VERSION "12.2.7"

NS_ :

BS_:

BU_: ACM ADAS_Body APM ASU_Gateway BCM BCM_BPM CCU_F CCU_R DUMMY_BCM_BPM ETG LDM_L LDM_R OCS_P PSM_D SRR_RR_M SHVU_F SHVU_R TRM USS_F USS_R XGW_Body

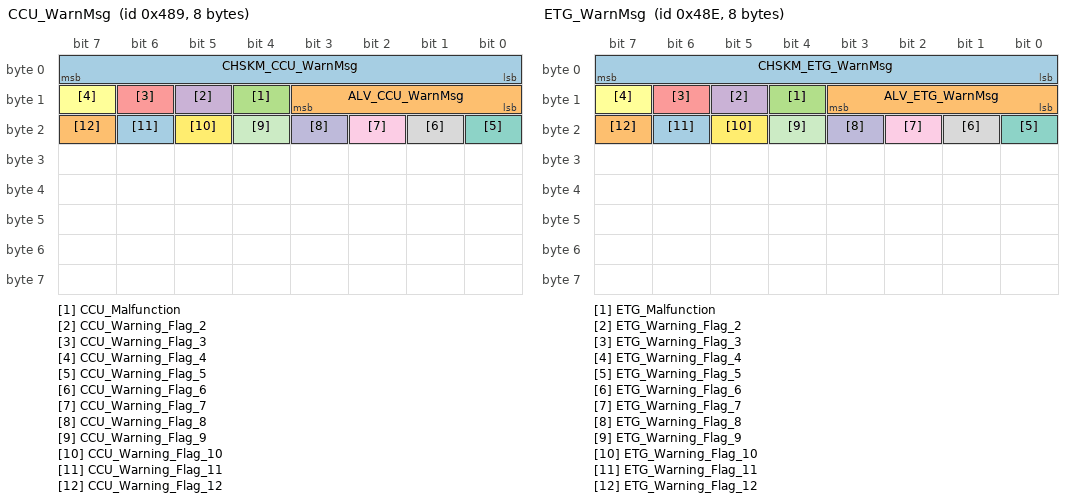
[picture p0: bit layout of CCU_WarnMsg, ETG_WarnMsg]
BO_ 1161 CCU_WarnMsg: 8 CCU_F
 SG_ CHSKM_CCU_WarnMsg : 7|8@0+ (1,0) [0|255] ""  XGW_Body
 SG_ ALV_CCU_WarnMsg : 11|4@0+ (1,0) [0|14] ""  XGW_Body
 SG_ CCU_Malfunction : 12|1@0+ (1,0) [0|1] ""  XGW_Body
 SG_ CCU_Warning_Flag_2 : 13|1@0+ (1,0) [0|1] "-"  XGW_Body
 SG_ CCU_Warning_Flag_3 : 14|1@0+ (1,0) [0|1] ""  XGW_Body
 SG_ CCU_Warning_Flag_4 : 15|1@0+ (1,0) [0|1] "-"  XGW_Body
 SG_ CCU_Warning_Flag_5 : 16|1@0+ (1,0) [0|1] "-"  XGW_Body
 SG_ CCU_Warning_Flag_6 : 17|1@0+ (1,0) [0|1] "-"  XGW_Body
 SG_ CCU_Warning_Flag_7 : 18|1@0+ (1,0) [0|1] "-"  XGW_Body
 SG_ CCU_Warning_Flag_8 : 19|1@0+ (1,0) [0|1] ""  XGW_Body
 SG_ CCU_Warning_Flag_9 : 20|1@0+ (1,0) [0|1] ""  XGW_Body
 SG_ CCU_Warning_Flag_10 : 21|1@0+ (1,0) [0|1] ""  XGW_Body
 SG_ CCU_Warning_Flag_11 : 22|1@0+ (1,0) [0|1] ""  XGW_Body
 SG_ CCU_Warning_Flag_12 : 23|1@0+ (1,0) [0|1] ""  XGW_Body

BO_ 1166 ETG_WarnMsg: 8 ETG
 SG_ CHSKM_ETG_WarnMsg : 7|8@0+ (1,0) [0|255] ""  XGW_Body
 SG_ ALV_ETG_WarnMsg : 11|4@0+ (1,0) [0|14] ""  XGW_Body
 SG_ ETG_Malfunction : 12|1@0+ (1,0) [0|1] "-"  XGW_Body
 SG_ ETG_Warning_Flag_2 : 13|1@0+ (1,0) [0|1] "-"  XGW_Body
 SG_ ETG_Warning_Flag_3 : 14|1@0+ (1,0) [0|1] ""  XGW_Body
 SG_ ETG_Warning_Flag_4 : 15|1@0+ (1,0) [0|1] ""  XGW_Body
 SG_ ETG_Warning_Flag_5 : 16|1@0+ (1,0) [0|1] "-"  XGW_Body
 SG_ ETG_Warning_Flag_6 : 17|1@0+ (1,0) [0|1] "-"  XGW_Body
 SG_ ETG_Warning_Flag_7 : 18|1@0+ (1,0) [0|1] "-"  XGW_Body
 SG_ ETG_Warning_Flag_8 : 19|1@0+ (1,0) [0|1] ""  XGW_Body
 SG_ ETG_Warning_Flag_9 : 20|1@0+ (1,0) [0|1] ""  XGW_Body
 SG_ ETG_Warning_Flag_10 : 21|1@0+ (1,0) [0|1] ""  XGW_Body
 SG_ ETG_Warning_Flag_11 : 22|1@0+ (1,0) [0|1] "-"  XGW_Body
 SG_ ETG_Warning_Flag_12 : 23|1@0+ (1,0) [0|1] ""  XGW_Body

BO_ 1171 BMS_WarnMsg: 8 XGW_Body
 SG_ CHSKM_BMS_WarnMsg : 7|8@0+ (1,0) [0|255] ""  BCM
 SG_ ALV_BMS_WarnMsg : 11|4@0+ (1,0) [0|14] ""  BCM
 SG_ BMS_PackTempSts : 13|2@0+ (1,0) [0|3] ""  BCM
 SG_ BMS_ThermalRunaway : 14|1@0+ (1,0) [0|1] ""  BCM
 SG_ BMS_BatteryReplacement : 15|1@0+ (1,0) [0|1] ""  BCM
 SG_ BMS_Warning_PowerDegrade : 16|1@0+ (1,0) [0|1] ""  BCM
 SG_ BMS_Warning_DeltaSoC : 17|1@0+ (1,0) [0|1] ""  BCM
 SG_ BMS_Warning_HVILSts : 18|1@0+ (1,0) [0|1] ""  BCM
 SG_ BMS_Warning_Isolation : 19|1@0+ (1,0) [0|1] ""  BCM
 SG_ BMS_Warning_CoolantLeakage : 20|1@0+ (1,0) [0|1] ""  BCM
 SG_ BMS_MalfunctionSts : 21|1@0+ (1,0) [0|1] ""  BCM
 SG_ BMS_LowBattery : 23|2@0+ (1,0) [0|3] ""  BCM
 SG_ BMS_Warning_DeltaTemperature : 31|8@0+ (1,0) [0|255] ""  BCM
 SG_ BMS_Warning_BDUTemperatureSts : 39|8@0+ (1,0) [0|255] ""  BCM
 SG_ BMS_Reserved_signal3 : 47|8@0+ (1,0) [0|255] ""  BCM
 SG_ BMS_Reserved_signal4 : 55|8@0+ (1,0) [0|255] ""  BCM
 SG_ BMS_Reserved_signal5 : 63|8@0+ (1,0) [0|255] ""  BCM

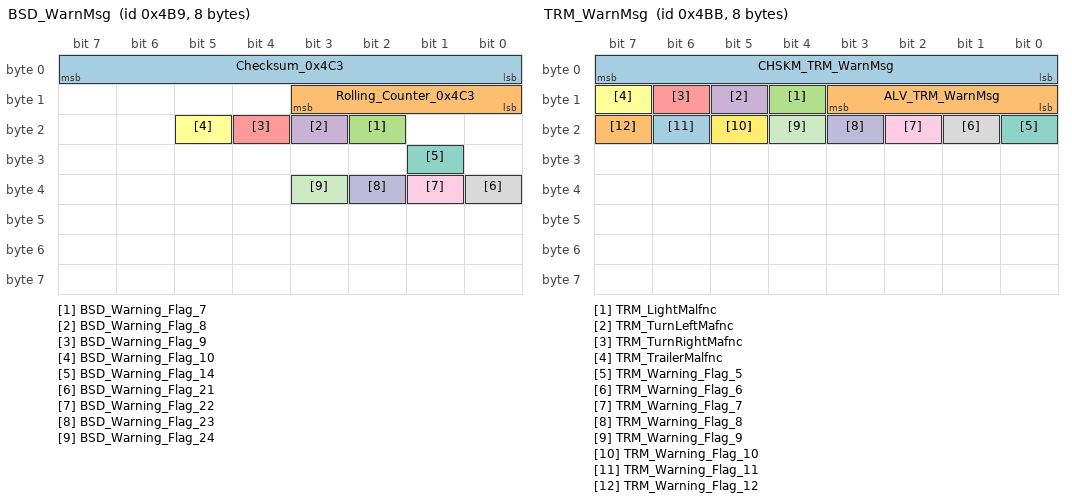
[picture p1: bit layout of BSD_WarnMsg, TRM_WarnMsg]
BO_ 1209 BSD_WarnMsg: 8 SRR_RR_M
 SG_ Checksum_0x4C3 : 7|8@0+ (1,0) [0|255] "" BCM,XGW_Body
 SG_ Rolling_Counter_0x4C3 : 11|4@0+ (1,0) [0|15] "" BCM,XGW_Body
 SG_ BSD_Warning_Flag_7 : 18|1@0+ (1,0) [0|1] "" BCM,XGW_Body
 SG_ BSD_Warning_Flag_8 : 19|1@0+ (1,0) [0|1] "" BCM,XGW_Body
 SG_ BSD_Warning_Flag_9 : 20|1@0+ (1,0) [0|1] "" BCM,XGW_Body
 SG_ BSD_Warning_Flag_10 : 21|1@0+ (1,0) [0|1] "" BCM,XGW_Body
 SG_ BSD_Warning_Flag_14 : 25|1@0+ (1,0) [0|1] "" BCM,XGW_Body
 SG_ BSD_Warning_Flag_21 : 32|1@0+ (1,0) [0|1] "" BCM,XGW_Body
 SG_ BSD_Warning_Flag_22 : 33|1@0+ (1,0) [0|1] "" BCM,XGW_Body
 SG_ BSD_Warning_Flag_23 : 34|1@0+ (1,0) [0|1] "" BCM,XGW_Body
 SG_ BSD_Warning_Flag_24 : 35|1@0+ (1,0) [0|1] "" BCM,XGW_Body

BO_ 1211 TRM_WarnMsg: 8 TRM
 SG_ CHSKM_TRM_WarnMsg : 7|8@0+ (1,0) [0|255] ""  XGW_Body
 SG_ ALV_TRM_WarnMsg : 11|4@0+ (1,0) [0|14] ""  XGW_Body
 SG_ TRM_LightMalfnc : 12|1@0+ (1,0) [0|1] "-"  XGW_Body
 SG_ TRM_TurnLeftMafnc : 13|1@0+ (1,0) [0|1] "-"  XGW_Body
 SG_ TRM_TurnRightMafnc : 14|1@0+ (1,0) [0|1] ""  XGW_Body
 SG_ TRM_TrailerMalfnc : 15|1@0+ (1,0) [0|1] ""  XGW_Body
 SG_ TRM_Warning_Flag_5 : 16|1@0+ (1,0) [0|1] "-"  XGW_Body
 SG_ TRM_Warning_Flag_6 : 17|1@0+ (1,0) [0|1] ""  XGW_Body
 SG_ TRM_Warning_Flag_7 : 18|1@0+ (1,0) [0|1] ""  XGW_Body
 SG_ TRM_Warning_Flag_8 : 19|1@0+ (1,0) [0|1] "-"  XGW_Body
 SG_ TRM_Warning_Flag_9 : 20|1@0+ (1,0) [0|1] "-"  XGW_Body
 SG_ TRM_Warning_Flag_10 : 21|1@0+ (1,0) [0|1] "-"  XGW_Body
 SG_ TRM_Warning_Flag_11 : 22|1@0+ (1,0) [0|1] ""  XGW_Body
 SG_ TRM_Warning_Flag_12 : 23|1@0+ (1,0) [0|1] ""  XGW_Body

BO_ 1216 BCM_STAT_DOOR: 8 BCM
 SG_ SECCAN_BCM_STAT_Door : 55|8@0+ (1,0) [0|255] ""  Vector__XXX
 SG_ BCM_STAT_DoorHandleRR : 56|1@0+ (1,0) [0|1] ""  Vector__XXX
 SG_ BCM_STAT_DoorHandleRL : 57|1@0+ (1,0) [0|1] ""  Vector__XXX
 SG_ BCM_STAT_DoorHandleFR : 58|1@0+ (1,0) [0|1] ""  Vector__XXX
 SG_ BCM_STAT_DoorHandleFL : 59|1@0+ (1,0) [0|1] ""  Vector__XXX

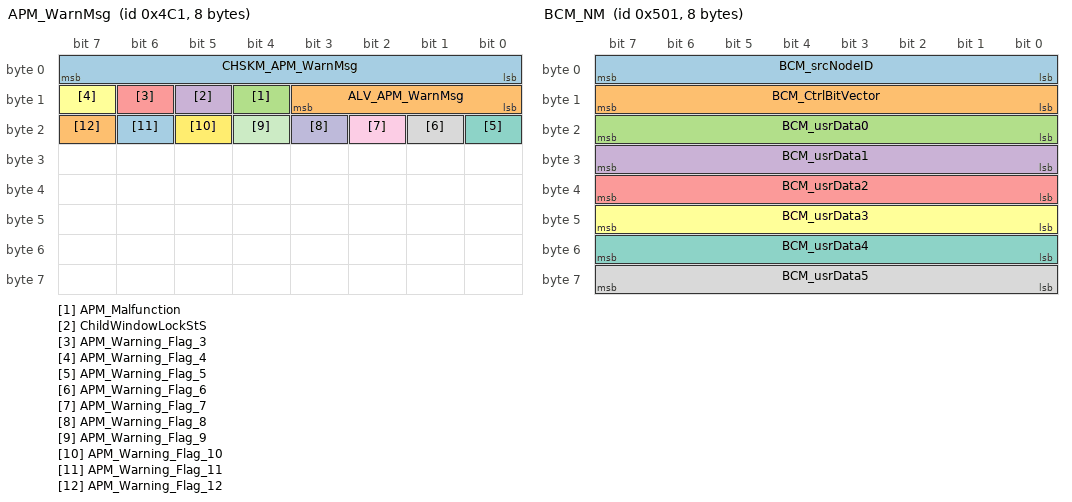
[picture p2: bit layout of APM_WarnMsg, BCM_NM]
BO_ 1217 APM_WarnMsg: 8 APM
 SG_ CHSKM_APM_WarnMsg : 7|8@0+ (1,0) [0|255] ""  XGW_Body
 SG_ ALV_APM_WarnMsg : 11|4@0+ (1,0) [0|14] ""  XGW_Body
 SG_ APM_Malfunction : 12|1@0+ (1,0) [0|1] ""  XGW_Body
 SG_ ChildWindowLockStS : 13|1@0+ (1,0) [0|1] "-"  XGW_Body
 SG_ APM_Warning_Flag_3 : 14|1@0+ (1,0) [0|1] ""  XGW_Body
 SG_ APM_Warning_Flag_4 : 15|1@0+ (1,0) [0|1] ""  XGW_Body
 SG_ APM_Warning_Flag_5 : 16|1@0+ (1,0) [0|1] "-"  XGW_Body
 SG_ APM_Warning_Flag_6 : 17|1@0+ (1,0) [0|1] ""  XGW_Body
 SG_ APM_Warning_Flag_7 : 18|1@0+ (1,0) [0|1] "-"  XGW_Body
 SG_ APM_Warning_Flag_8 : 19|1@0+ (1,0) [0|1] ""  XGW_Body
 SG_ APM_Warning_Flag_9 : 20|1@0+ (1,0) [0|1] ""  XGW_Body
 SG_ APM_Warning_Flag_10 : 21|1@0+ (1,0) [0|1] ""  XGW_Body
 SG_ APM_Warning_Flag_11 : 22|1@0+ (1,0) [0|1] ""  XGW_Body
 SG_ APM_Warning_Flag_12 : 23|1@0+ (1,0) [0|1] "-"  XGW_Body

BO_ 1281 BCM_NM: 8 BCM
 SG_ BCM_srcNodeID : 7|8@0+ (1,0) [0|255] ""  APM,CCU_F,CCU_R,ETG,LDM_L,LDM_R,PSM_D,SRR_RR_M,TRM,XGW_Body
 SG_ BCM_CtrlBitVector : 15|8@0+ (1,0) [0|255] ""  APM,CCU_F,CCU_R,ETG,LDM_L,LDM_R,PSM_D,SRR_RR_M,TRM,XGW_Body
 SG_ BCM_usrData0 : 23|8@0+ (1,0) [0|255] ""  APM,CCU_F,CCU_R,ETG,LDM_L,LDM_R,PSM_D,SRR_RR_M,TRM,XGW_Body
 SG_ BCM_usrData1 : 31|8@0+ (1,0) [0|255] ""  APM,CCU_F,CCU_R,ETG,LDM_L,LDM_R,PSM_D,SRR_RR_M,TRM,XGW_Body
 SG_ BCM_usrData2 : 39|8@0+ (1,0) [0|255] ""  APM,CCU_F,CCU_R,ETG,LDM_L,LDM_R,PSM_D,SRR_RR_M,TRM,XGW_Body
 SG_ BCM_usrData3 : 47|8@0+ (1,0) [0|255] ""  APM,CCU_F,CCU_R,ETG,LDM_L,LDM_R,PSM_D,SRR_RR_M,TRM,XGW_Body
 SG_ BCM_usrData4 : 55|8@0+ (1,0) [0|255] ""  APM,CCU_F,CCU_R,ETG,LDM_L,LDM_R,PSM_D,SRR_RR_M,TRM,XGW_Body
 SG_ BCM_usrData5 : 63|8@0+ (1,0) [0|255] ""  APM,CCU_F,CCU_R,ETG,LDM_L,LDM_R,PSM_D,SRR_RR_M,TRM,XGW_Body

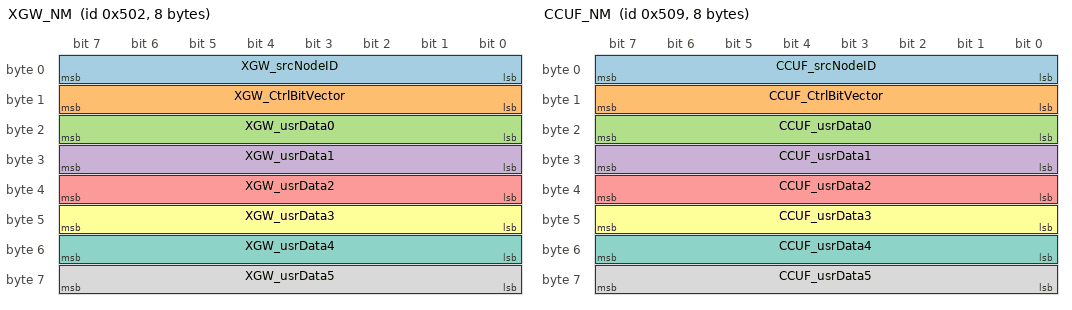
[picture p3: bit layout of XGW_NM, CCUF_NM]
BO_ 1282 XGW_NM: 8 XGW_Body
 SG_ XGW_srcNodeID : 7|8@0+ (1,0) [0|255] ""  APM,ASU_Gateway,BCM,CCU_F,CCU_R,ETG,LDM_L,LDM_R,PSM_D,SRR_RR_M,TRM
 SG_ XGW_CtrlBitVector : 15|8@0+ (1,0) [0|255] ""  APM,ASU_Gateway,BCM,CCU_F,CCU_R,ETG,LDM_L,LDM_R,PSM_D,SRR_RR_M,TRM
 SG_ XGW_usrData0 : 23|8@0+ (1,0) [0|255] ""  APM,ASU_Gateway,BCM,CCU_F,CCU_R,ETG,LDM_L,LDM_R,PSM_D,SRR_RR_M,TRM
 SG_ XGW_usrData1 : 31|8@0+ (1,0) [0|255] ""  APM,ASU_Gateway,BCM,CCU_F,CCU_R,ETG,LDM_L,LDM_R,PSM_D,SRR_RR_M,TRM
 SG_ XGW_usrData2 : 39|8@0+ (1,0) [0|255] ""  APM,ASU_Gateway,BCM,CCU_F,CCU_R,ETG,LDM_L,LDM_R,PSM_D,SRR_RR_M,TRM
 SG_ XGW_usrData3 : 47|8@0+ (1,0) [0|255] ""  APM,ASU_Gateway,BCM,CCU_F,CCU_R,ETG,LDM_L,LDM_R,PSM_D,SRR_RR_M,TRM
 SG_ XGW_usrData4 : 55|8@0+ (1,0) [0|255] ""  APM,ASU_Gateway,BCM,CCU_F,CCU_R,ETG,LDM_L,LDM_R,PSM_D,SRR_RR_M,TRM
 SG_ XGW_usrData5 : 63|8@0+ (1,0) [0|255] ""  APM,ASU_Gateway,BCM,CCU_F,CCU_R,ETG,LDM_L,LDM_R,PSM_D,SRR_RR_M,TRM

BO_ 1289 CCUF_NM: 8 CCU_F
 SG_ CCUF_srcNodeID : 7|8@0+ (1,0) [0|255] ""  APM,BCM,CCU_R,ETG,LDM_L,LDM_R,PSM_D,TRM,XGW_Body
 SG_ CCUF_CtrlBitVector : 15|8@0+ (1,0) [0|255] ""  APM,BCM,CCU_R,ETG,LDM_L,LDM_R,PSM_D,TRM,XGW_Body
 SG_ CCUF_usrData0 : 23|8@0+ (1,0) [0|255] ""  APM,BCM,CCU_R,ETG,LDM_L,LDM_R,PSM_D,TRM,XGW_Body
 SG_ CCUF_usrData1 : 31|8@0+ (1,0) [0|255] ""  APM,BCM,CCU_R,ETG,LDM_L,LDM_R,PSM_D,TRM,XGW_Body
 SG_ CCUF_usrData2 : 39|8@0+ (1,0) [0|255] ""  APM,BCM,CCU_R,ETG,LDM_L,LDM_R,PSM_D,TRM,XGW_Body
 SG_ CCUF_usrData3 : 47|8@0+ (1,0) [0|255] ""  APM,BCM,CCU_R,ETG,LDM_L,LDM_R,PSM_D,TRM,XGW_Body
 SG_ CCUF_usrData4 : 55|8@0+ (1,0) [0|255] ""  APM,BCM,CCU_R,ETG,LDM_L,LDM_R,PSM_D,TRM,XGW_Body
 SG_ CCUF_usrData5 : 63|8@0+ (1,0) [0|255] ""  APM,BCM,CCU_R,ETG,LDM_L,LDM_R,PSM_D,TRM,XGW_Body

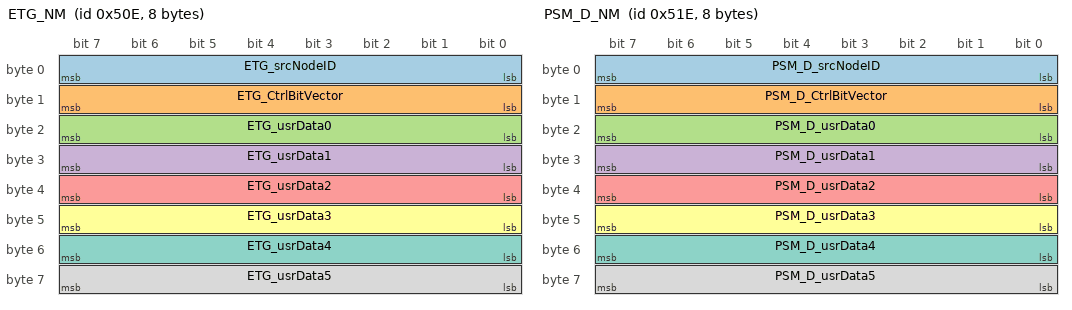
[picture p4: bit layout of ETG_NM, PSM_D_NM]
BO_ 1294 ETG_NM: 8 ETG
 SG_ ETG_srcNodeID : 7|8@0+ (1,0) [0|255] ""  APM,BCM,CCU_F,CCU_R,LDM_L,LDM_R,PSM_D,TRM,XGW_Body
 SG_ ETG_CtrlBitVector : 15|8@0+ (1,0) [0|255] ""  APM,BCM,CCU_F,CCU_R,LDM_L,LDM_R,PSM_D,TRM,XGW_Body
 SG_ ETG_usrData0 : 23|8@0+ (1,0) [0|255] ""  APM,BCM,CCU_F,CCU_R,LDM_L,LDM_R,PSM_D,TRM,XGW_Body
 SG_ ETG_usrData1 : 31|8@0+ (1,0) [0|255] ""  APM,BCM,CCU_F,CCU_R,LDM_L,LDM_R,PSM_D,TRM,XGW_Body
 SG_ ETG_usrData2 : 39|8@0+ (1,0) [0|255] ""  APM,BCM,CCU_F,CCU_R,LDM_L,LDM_R,PSM_D,TRM,XGW_Body
 SG_ ETG_usrData3 : 47|8@0+ (1,0) [0|255] ""  APM,BCM,CCU_F,CCU_R,LDM_L,LDM_R,PSM_D,TRM,XGW_Body
 SG_ ETG_usrData4 : 55|8@0+ (1,0) [0|255] ""  APM,BCM,CCU_F,CCU_R,LDM_L,LDM_R,PSM_D,TRM,XGW_Body
 SG_ ETG_usrData5 : 63|8@0+ (1,0) [0|255] ""  APM,BCM,CCU_F,CCU_R,LDM_L,LDM_R,PSM_D,TRM,XGW_Body

BO_ 1310 PSM_D_NM: 8 PSM_D
 SG_ PSM_D_srcNodeID : 7|8@0+ (1,0) [0|255] ""  APM,BCM,CCU_F,CCU_R,ETG,LDM_L,LDM_R,TRM,XGW_Body
 SG_ PSM_D_CtrlBitVector : 15|8@0+ (1,0) [0|255] ""  APM,BCM,CCU_F,CCU_R,ETG,LDM_L,LDM_R,TRM,XGW_Body
 SG_ PSM_D_usrData0 : 23|8@0+ (1,0) [0|255] ""  APM,BCM,CCU_F,CCU_R,ETG,LDM_L,LDM_R,TRM,XGW_Body
 SG_ PSM_D_usrData1 : 31|8@0+ (1,0) [0|255] ""  APM,BCM,CCU_F,CCU_R,ETG,LDM_L,LDM_R,TRM,XGW_Body
 SG_ PSM_D_usrData2 : 39|8@0+ (1,0) [0|255] ""  APM,BCM,CCU_F,CCU_R,ETG,LDM_L,LDM_R,TRM,XGW_Body
 SG_ PSM_D_usrData3 : 47|8@0+ (1,0) [0|255] ""  APM,BCM,CCU_F,CCU_R,ETG,LDM_L,LDM_R,TRM,XGW_Body
 SG_ PSM_D_usrData4 : 55|8@0+ (1,0) [0|255] ""  APM,BCM,CCU_F,CCU_R,ETG,LDM_L,LDM_R,TRM,XGW_Body
 SG_ PSM_D_usrData5 : 63|8@0+ (1,0) [0|255] ""  APM,BCM,CCU_F,CCU_R,ETG,LDM_L,LDM_R,TRM,XGW_Body

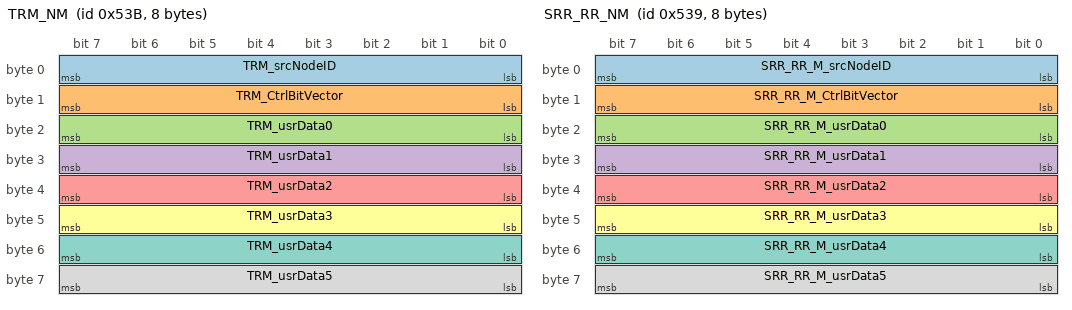
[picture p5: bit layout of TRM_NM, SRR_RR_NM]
BO_ 1339 TRM_NM: 8 TRM
 SG_ TRM_srcNodeID : 7|8@0+ (1,0) [0|255] ""  LDM_R,LDM_L,XGW_Body,BCM,ETG,APM,CCU_F,PSM_D,CCU_R
 SG_ TRM_CtrlBitVector : 15|8@0+ (1,0) [0|255] ""  LDM_R,LDM_L,XGW_Body,BCM,ETG,APM,CCU_F,PSM_D,CCU_R
 SG_ TRM_usrData0 : 23|8@0+ (1,0) [0|255] ""  LDM_R,LDM_L,XGW_Body,BCM,ETG,APM,CCU_F,PSM_D,CCU_R
 SG_ TRM_usrData1 : 31|8@0+ (1,0) [0|255] ""  LDM_R,LDM_L,XGW_Body,BCM,ETG,APM,CCU_F,PSM_D,CCU_R
 SG_ TRM_usrData2 : 39|8@0+ (1,0) [0|255] ""  LDM_R,LDM_L,XGW_Body,BCM,ETG,APM,CCU_F,PSM_D,CCU_R
 SG_ TRM_usrData3 : 47|8@0+ (1,0) [0|255] ""  LDM_R,LDM_L,XGW_Body,BCM,ETG,APM,CCU_F,PSM_D,CCU_R
 SG_ TRM_usrData4 : 55|8@0+ (1,0) [0|255] ""  LDM_R,LDM_L,XGW_Body,BCM,ETG,APM,CCU_F,PSM_D,CCU_R
 SG_ TRM_usrData5 : 63|8@0+ (1,0) [0|255] ""  LDM_R,LDM_L,XGW_Body,BCM,ETG,APM,CCU_F,PSM_D,CCU_R

BO_ 1337 SRR_RR_NM: 8 SRR_RR_M
 SG_ SRR_RR_M_srcNodeID : 7|8@0+ (1,0) [0|255] "" XGW_Body,BCM,ACM
 SG_ SRR_RR_M_CtrlBitVector : 15|8@0+ (1,0) [0|255] "" XGW_Body,BCM,ACM
 SG_ SRR_RR_M_usrData0 : 23|8@0+ (1,0) [0|255] "" XGW_Body,BCM,ACM
 SG_ SRR_RR_M_usrData1 : 31|8@0+ (1,0) [0|255] "" XGW_Body,BCM,ACM
 SG_ SRR_RR_M_usrData2 : 39|8@0+ (1,0) [0|255] "" XGW_Body,BCM,ACM
 SG_ SRR_RR_M_usrData3 : 47|8@0+ (1,0) [0|255] "" XGW_Body,BCM,ACM
 SG_ SRR_RR_M_usrData4 : 55|8@0+ (1,0) [0|255] "" XGW_Body,BCM,ACM
 SG_ SRR_RR_M_usrData5 : 63|8@0+ (1,0) [0|255] "" XGW_Body,BCM,ACM

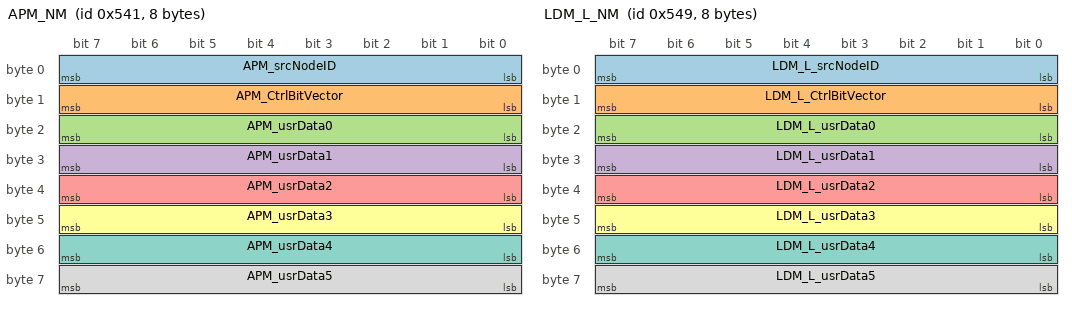
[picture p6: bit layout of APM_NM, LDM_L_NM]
BO_ 1345 APM_NM: 8 APM
 SG_ APM_srcNodeID : 7|8@0+ (1,0) [0|255] ""  BCM,CCU_F,CCU_R,ETG,LDM_L,LDM_R,PSM_D,TRM,XGW_Body
 SG_ APM_CtrlBitVector : 15|8@0+ (1,0) [0|255] ""  BCM,CCU_F,CCU_R,ETG,LDM_L,LDM_R,PSM_D,TRM,XGW_Body
 SG_ APM_usrData0 : 23|8@0+ (1,0) [0|255] ""  BCM,CCU_F,CCU_R,ETG,LDM_L,LDM_R,PSM_D,TRM,XGW_Body
 SG_ APM_usrData1 : 31|8@0+ (1,0) [0|255] ""  BCM,CCU_F,CCU_R,ETG,LDM_L,LDM_R,PSM_D,TRM,XGW_Body
 SG_ APM_usrData2 : 39|8@0+ (1,0) [0|255] ""  BCM,CCU_F,CCU_R,ETG,LDM_L,LDM_R,PSM_D,TRM,XGW_Body
 SG_ APM_usrData3 : 47|8@0+ (1,0) [0|255] ""  BCM,CCU_F,CCU_R,ETG,LDM_L,LDM_R,PSM_D,TRM,XGW_Body
 SG_ APM_usrData4 : 55|8@0+ (1,0) [0|255] ""  BCM,CCU_F,CCU_R,ETG,LDM_L,LDM_R,PSM_D,TRM,XGW_Body
 SG_ APM_usrData5 : 63|8@0+ (1,0) [0|255] ""  BCM,CCU_F,CCU_R,ETG,LDM_L,LDM_R,PSM_D,TRM,XGW_Body

BO_ 1353 LDM_L_NM: 8 LDM_L
 SG_ LDM_L_srcNodeID : 7|8@0+ (1,0) [0|255] ""  APM,BCM,CCU_F,CCU_R,ETG,PSM_D,TRM,XGW_Body
 SG_ LDM_L_CtrlBitVector : 15|8@0+ (1,0) [0|255] ""  APM,BCM,CCU_F,CCU_R,ETG,PSM_D,TRM,XGW_Body
 SG_ LDM_L_usrData0 : 23|8@0+ (1,0) [0|255] ""  APM,BCM,CCU_F,CCU_R,ETG,PSM_D,TRM,XGW_Body
 SG_ LDM_L_usrData1 : 31|8@0+ (1,0) [0|255] ""  APM,BCM,CCU_F,CCU_R,ETG,PSM_D,TRM,XGW_Body
 SG_ LDM_L_usrData2 : 39|8@0+ (1,0) [0|255] ""  APM,BCM,CCU_F,CCU_R,ETG,PSM_D,TRM,XGW_Body
 SG_ LDM_L_usrData3 : 47|8@0+ (1,0) [0|255] ""  APM,BCM,CCU_F,CCU_R,ETG,PSM_D,TRM,XGW_Body
 SG_ LDM_L_usrData4 : 55|8@0+ (1,0) [0|255] ""  APM,BCM,CCU_F,CCU_R,ETG,PSM_D,TRM,XGW_Body
 SG_ LDM_L_usrData5 : 63|8@0+ (1,0) [0|255] ""  APM,BCM,CCU_F,CCU_R,ETG,PSM_D,TRM,XGW_Body

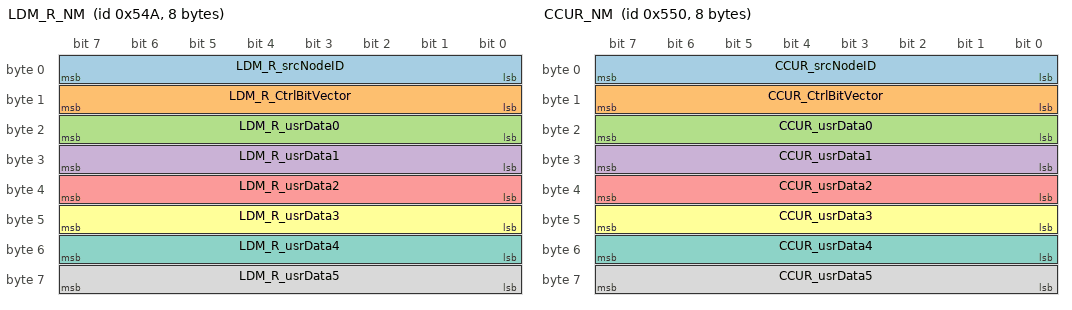
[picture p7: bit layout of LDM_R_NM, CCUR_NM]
BO_ 1354 LDM_R_NM: 8 LDM_R
 SG_ LDM_R_srcNodeID : 7|8@0+ (1,0) [0|255] ""  APM,BCM,CCU_F,CCU_R,ETG,LDM_L,LDM_R,PSM_D,TRM,XGW_Body
 SG_ LDM_R_CtrlBitVector : 15|8@0+ (1,0) [0|255] ""  APM,BCM,CCU_F,CCU_R,ETG,LDM_L,LDM_R,PSM_D,TRM,XGW_Body
 SG_ LDM_R_usrData0 : 23|8@0+ (1,0) [0|255] ""  APM,BCM,CCU_F,CCU_R,ETG,LDM_L,LDM_R,PSM_D,TRM,XGW_Body
 SG_ LDM_R_usrData1 : 31|8@0+ (1,0) [0|255] ""  APM,BCM,CCU_F,CCU_R,ETG,LDM_L,LDM_R,PSM_D,TRM,XGW_Body
 SG_ LDM_R_usrData2 : 39|8@0+ (1,0) [0|255] ""  APM,BCM,CCU_F,CCU_R,ETG,LDM_L,LDM_R,PSM_D,TRM,XGW_Body
 SG_ LDM_R_usrData3 : 47|8@0+ (1,0) [0|255] ""  APM,BCM,CCU_F,CCU_R,ETG,LDM_L,LDM_R,PSM_D,TRM,XGW_Body
 SG_ LDM_R_usrData4 : 55|8@0+ (1,0) [0|255] ""  APM,BCM,CCU_F,CCU_R,ETG,LDM_L,LDM_R,PSM_D,TRM,XGW_Body
 SG_ LDM_R_usrData5 : 63|8@0+ (1,0) [0|255] ""  APM,BCM,CCU_F,CCU_R,ETG,LDM_L,LDM_R,PSM_D,TRM,XGW_Body

BO_ 1360 CCUR_NM: 8 CCU_R
 SG_ CCUR_srcNodeID : 7|8@0+ (1,0) [0|255] ""  APM,BCM,CCU_F,ETG,LDM_L,LDM_R,PSM_D,TRM,XGW_Body
 SG_ CCUR_CtrlBitVector : 15|8@0+ (1,0) [0|255] ""  APM,BCM,CCU_F,ETG,LDM_L,LDM_R,PSM_D,TRM,XGW_Body
 SG_ CCUR_usrData0 : 23|8@0+ (1,0) [0|255] ""  APM,BCM,CCU_F,ETG,LDM_L,LDM_R,PSM_D,TRM,XGW_Body
 SG_ CCUR_usrData1 : 31|8@0+ (1,0) [0|255] ""  APM,BCM,CCU_F,ETG,LDM_L,LDM_R,PSM_D,TRM,XGW_Body
 SG_ CCUR_usrData2 : 39|8@0+ (1,0) [0|255] ""  APM,BCM,CCU_F,ETG,LDM_L,LDM_R,PSM_D,TRM,XGW_Body
 SG_ CCUR_usrData3 : 47|8@0+ (1,0) [0|255] ""  APM,BCM,CCU_F,ETG,LDM_L,LDM_R,PSM_D,TRM,XGW_Body
 SG_ CCUR_usrData4 : 55|8@0+ (1,0) [0|255] ""  APM,BCM,CCU_F,ETG,LDM_L,LDM_R,PSM_D,TRM,XGW_Body
 SG_ CCUR_usrData5 : 63|8@0+ (1,0) [0|255] ""  APM,BCM,CCU_F,ETG,LDM_L,LDM_R,PSM_D,TRM,XGW_Body

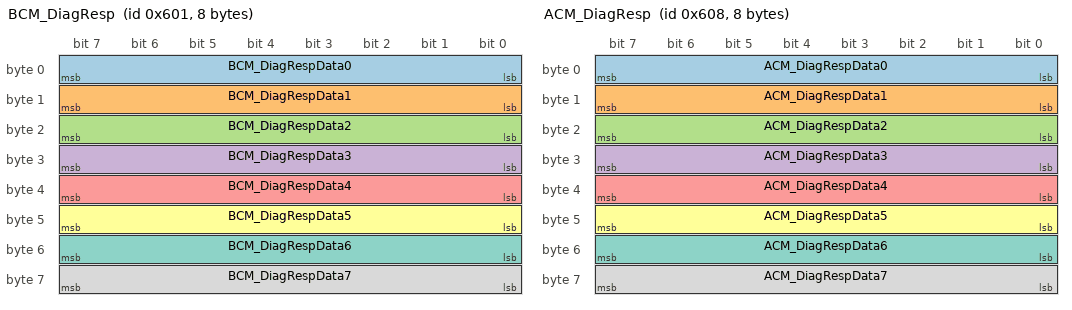
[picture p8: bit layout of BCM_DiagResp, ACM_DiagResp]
BO_ 1537 BCM_DiagResp: 8 BCM
 SG_ BCM_DiagRespData0 : 7|8@0+ (1,0) [0|255] ""  XGW_Body
 SG_ BCM_DiagRespData1 : 15|8@0+ (1,0) [0|255] "-"  XGW_Body
 SG_ BCM_DiagRespData2 : 23|8@0+ (1,0) [0|255] ""  XGW_Body
 SG_ BCM_DiagRespData3 : 31|8@0+ (1,0) [0|255] ""  XGW_Body
 SG_ BCM_DiagRespData4 : 39|8@0+ (1,0) [0|255] ""  XGW_Body
 SG_ BCM_DiagRespData5 : 47|8@0+ (1,0) [0|255] ""  XGW_Body
 SG_ BCM_DiagRespData6 : 55|8@0+ (1,0) [0|255] "-"  XGW_Body
 SG_ BCM_DiagRespData7 : 63|8@0+ (1,0) [0|255] ""  XGW_Body

BO_ 1544 ACM_DiagResp: 8 ACM
 SG_ ACM_DiagRespData0 : 7|8@0+ (1,0) [0|255] ""  XGW_Body
 SG_ ACM_DiagRespData1 : 15|8@0+ (1,0) [0|255] "-"  XGW_Body
 SG_ ACM_DiagRespData2 : 23|8@0+ (1,0) [0|255] ""  XGW_Body
 SG_ ACM_DiagRespData3 : 31|8@0+ (1,0) [0|255] "-"  XGW_Body
 SG_ ACM_DiagRespData4 : 39|8@0+ (1,0) [0|255] ""  XGW_Body
 SG_ ACM_DiagRespData5 : 47|8@0+ (1,0) [0|255] "-"  XGW_Body
 SG_ ACM_DiagRespData6 : 55|8@0+ (1,0) [0|255] ""  XGW_Body
 SG_ ACM_DiagRespData7 : 63|8@0+ (1,0) [0|255] "-"  XGW_Body

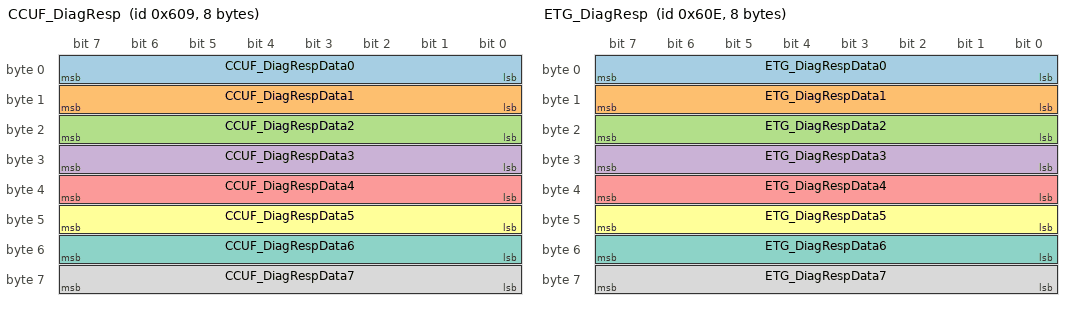
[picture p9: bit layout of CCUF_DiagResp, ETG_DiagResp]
BO_ 1545 CCUF_DiagResp: 8 CCU_F
 SG_ CCUF_DiagRespData0 : 7|8@0+ (1,0) [0|255] ""  XGW_Body
 SG_ CCUF_DiagRespData1 : 15|8@0+ (1,0) [0|255] "-"  XGW_Body
 SG_ CCUF_DiagRespData2 : 23|8@0+ (1,0) [0|255] "-"  XGW_Body
 SG_ CCUF_DiagRespData3 : 31|8@0+ (1,0) [0|255] ""  XGW_Body
 SG_ CCUF_DiagRespData4 : 39|8@0+ (1,0) [0|255] ""  XGW_Body
 SG_ CCUF_DiagRespData5 : 47|8@0+ (1,0) [0|255] "-"  XGW_Body
 SG_ CCUF_DiagRespData6 : 55|8@0+ (1,0) [0|255] "-"  XGW_Body
 SG_ CCUF_DiagRespData7 : 63|8@0+ (1,0) [0|255] ""  XGW_Body

BO_ 1550 ETG_DiagResp: 8 ETG
 SG_ ETG_DiagRespData0 : 7|8@0+ (1,0) [0|255] ""  XGW_Body
 SG_ ETG_DiagRespData1 : 15|8@0+ (1,0) [0|255] ""  XGW_Body
 SG_ ETG_DiagRespData2 : 23|8@0+ (1,0) [0|255] ""  XGW_Body
 SG_ ETG_DiagRespData3 : 31|8@0+ (1,0) [0|255] "-"  XGW_Body
 SG_ ETG_DiagRespData4 : 39|8@0+ (1,0) [0|255] ""  XGW_Body
 SG_ ETG_DiagRespData5 : 47|8@0+ (1,0) [0|255] ""  XGW_Body
 SG_ ETG_DiagRespData6 : 55|8@0+ (1,0) [0|255] ""  XGW_Body
 SG_ ETG_DiagRespData7 : 63|8@0+ (1,0) [0|255] ""  XGW_Body

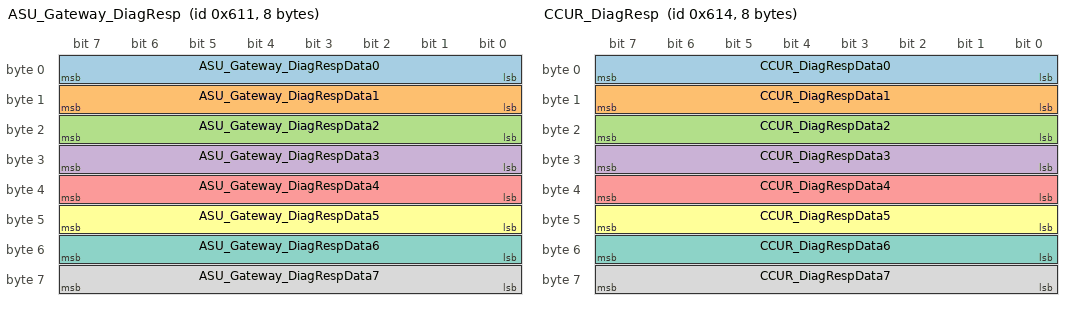
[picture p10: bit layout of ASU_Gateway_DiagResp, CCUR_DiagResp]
BO_ 1553 ASU_Gateway_DiagResp: 8 ASU_Gateway
 SG_ ASU_Gateway_DiagRespData0 : 7|8@0+ (1,0) [0|255] "-"  XGW_Body
 SG_ ASU_Gateway_DiagRespData1 : 15|8@0+ (1,0) [0|255] "-"  XGW_Body
 SG_ ASU_Gateway_DiagRespData2 : 23|8@0+ (1,0) [0|255] "-"  XGW_Body
 SG_ ASU_Gateway_DiagRespData3 : 31|8@0+ (1,0) [0|255] "-"  XGW_Body
 SG_ ASU_Gateway_DiagRespData4 : 39|8@0+ (1,0) [0|255] "-"  XGW_Body
 SG_ ASU_Gateway_DiagRespData5 : 47|8@0+ (1,0) [0|255] "-"  XGW_Body
 SG_ ASU_Gateway_DiagRespData6 : 55|8@0+ (1,0) [0|255] "-"  XGW_Body
 SG_ ASU_Gateway_DiagRespData7 : 63|8@0+ (1,0) [0|255] "-"  XGW_Body

BO_ 1556 CCUR_DiagResp: 8 CCU_R
 SG_ CCUR_DiagRespData0 : 7|8@0+ (1,0) [0|255] ""  XGW_Body
 SG_ CCUR_DiagRespData1 : 15|8@0+ (1,0) [0|255] ""  XGW_Body
 SG_ CCUR_DiagRespData2 : 23|8@0+ (1,0) [0|255] ""  XGW_Body
 SG_ CCUR_DiagRespData3 : 31|8@0+ (1,0) [0|255] ""  XGW_Body
 SG_ CCUR_DiagRespData4 : 39|8@0+ (1,0) [0|255] "-"  XGW_Body
 SG_ CCUR_DiagRespData5 : 47|8@0+ (1,0) [0|255] ""  XGW_Body
 SG_ CCUR_DiagRespData6 : 55|8@0+ (1,0) [0|255] "-"  XGW_Body
 SG_ CCUR_DiagRespData7 : 63|8@0+ (1,0) [0|255] ""  XGW_Body

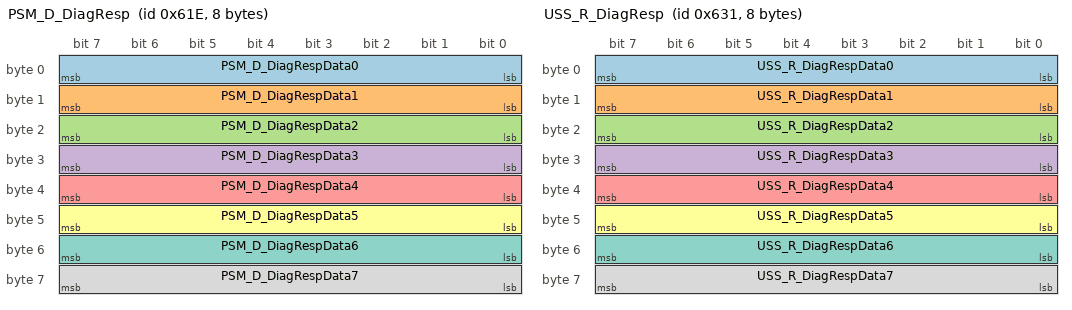
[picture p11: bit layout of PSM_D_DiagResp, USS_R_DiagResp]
BO_ 1566 PSM_D_DiagResp: 8 PSM_D
 SG_ PSM_D_DiagRespData0 : 7|8@0+ (1,0) [0|255] ""  XGW_Body
 SG_ PSM_D_DiagRespData1 : 15|8@0+ (1,0) [0|255] ""  XGW_Body
 SG_ PSM_D_DiagRespData2 : 23|8@0+ (1,0) [0|255] ""  XGW_Body
 SG_ PSM_D_DiagRespData3 : 31|8@0+ (1,0) [0|255] "-"  XGW_Body
 SG_ PSM_D_DiagRespData4 : 39|8@0+ (1,0) [0|255] ""  XGW_Body
 SG_ PSM_D_DiagRespData5 : 47|8@0+ (1,0) [0|255] ""  XGW_Body
 SG_ PSM_D_DiagRespData6 : 55|8@0+ (1,0) [0|255] ""  XGW_Body
 SG_ PSM_D_DiagRespData7 : 63|8@0+ (1,0) [0|255] ""  XGW_Body

BO_ 1585 USS_R_DiagResp: 8 USS_R
 SG_ USS_R_DiagRespData0 : 7|8@0+ (1,0) [0|255] "-"  XGW_Body
 SG_ USS_R_DiagRespData1 : 15|8@0+ (1,0) [0|255] "-"  XGW_Body
 SG_ USS_R_DiagRespData2 : 23|8@0+ (1,0) [0|255] "-"  XGW_Body
 SG_ USS_R_DiagRespData3 : 31|8@0+ (1,0) [0|255] "-"  XGW_Body
 SG_ USS_R_DiagRespData4 : 39|8@0+ (1,0) [0|255] "-"  XGW_Body
 SG_ USS_R_DiagRespData5 : 47|8@0+ (1,0) [0|255] "-"  XGW_Body
 SG_ USS_R_DiagRespData6 : 55|8@0+ (1,0) [0|255] "-"  XGW_Body
 SG_ USS_R_DiagRespData7 : 63|8@0+ (1,0) [0|255] "-"  XGW_Body

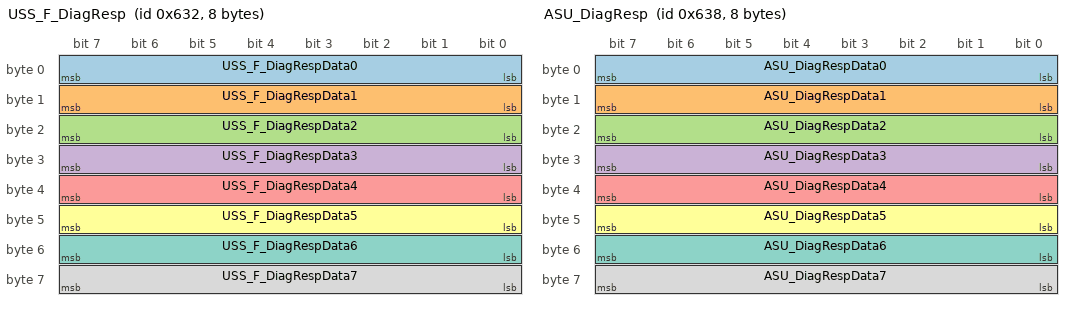
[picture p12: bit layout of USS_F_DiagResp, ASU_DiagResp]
BO_ 1586 USS_F_DiagResp: 8 USS_F
 SG_ USS_F_DiagRespData0 : 7|8@0+ (1,0) [0|255] "-"  XGW_Body
 SG_ USS_F_DiagRespData1 : 15|8@0+ (1,0) [0|255] "-"  XGW_Body
 SG_ USS_F_DiagRespData2 : 23|8@0+ (1,0) [0|255] "-"  XGW_Body
 SG_ USS_F_DiagRespData3 : 31|8@0+ (1,0) [0|255] "-"  XGW_Body
 SG_ USS_F_DiagRespData4 : 39|8@0+ (1,0) [0|255] "-"  XGW_Body
 SG_ USS_F_DiagRespData5 : 47|8@0+ (1,0) [0|255] "-"  XGW_Body
 SG_ USS_F_DiagRespData6 : 55|8@0+ (1,0) [0|255] "-"  XGW_Body
 SG_ USS_F_DiagRespData7 : 63|8@0+ (1,0) [0|255] "-"  XGW_Body

BO_ 1592 ASU_DiagResp: 8 ASU_Gateway
 SG_ ASU_DiagRespData0 : 7|8@0+ (1,0) [0|255] "-"  XGW_Body
 SG_ ASU_DiagRespData1 : 15|8@0+ (1,0) [0|255] "-"  XGW_Body
 SG_ ASU_DiagRespData2 : 23|8@0+ (1,0) [0|255] "-"  XGW_Body
 SG_ ASU_DiagRespData3 : 31|8@0+ (1,0) [0|255] "-"  XGW_Body
 SG_ ASU_DiagRespData4 : 39|8@0+ (1,0) [0|255] "-"  XGW_Body
 SG_ ASU_DiagRespData5 : 47|8@0+ (1,0) [0|255] "-"  XGW_Body
 SG_ ASU_DiagRespData6 : 55|8@0+ (1,0) [0|255] "-"  XGW_Body
 SG_ ASU_DiagRespData7 : 63|8@0+ (1,0) [0|255] "-"  XGW_Body

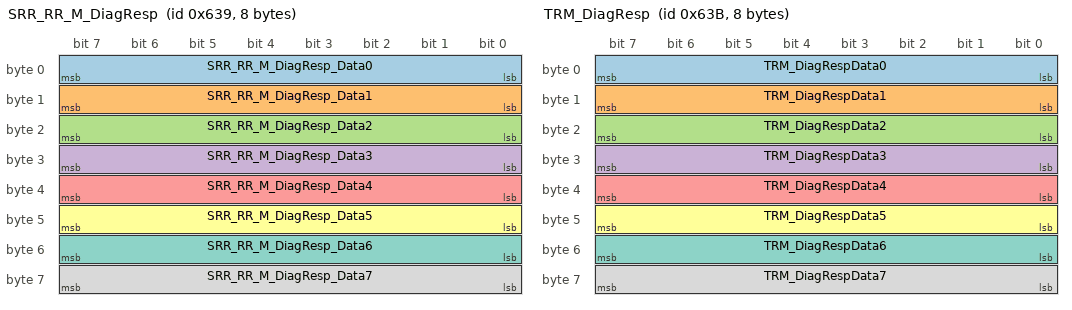
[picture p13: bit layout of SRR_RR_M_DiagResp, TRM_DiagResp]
BO_ 1593 SRR_RR_M_DiagResp: 8 SRR_RR_M
 SG_ SRR_RR_M_DiagResp_Data0 : 7|8@0+ (1,0) [0|255] "" XGW_Body
 SG_ SRR_RR_M_DiagResp_Data1 : 15|8@0+ (1,0) [0|255] "" XGW_Body
 SG_ SRR_RR_M_DiagResp_Data2 : 23|8@0+ (1,0) [0|255] "" XGW_Body
 SG_ SRR_RR_M_DiagResp_Data3 : 31|8@0+ (1,0) [0|255] "" XGW_Body
 SG_ SRR_RR_M_DiagResp_Data4 : 39|8@0+ (1,0) [0|255] "" XGW_Body
 SG_ SRR_RR_M_DiagResp_Data5 : 47|8@0+ (1,0) [0|255] "" XGW_Body
 SG_ SRR_RR_M_DiagResp_Data6 : 55|8@0+ (1,0) [0|255] "" XGW_Body
 SG_ SRR_RR_M_DiagResp_Data7 : 63|8@0+ (1,0) [0|255] "" XGW_Body

BO_ 1595 TRM_DiagResp: 8 TRM
 SG_ TRM_DiagRespData0 : 7|8@0+ (1,0) [0|255] ""  XGW_Body
 SG_ TRM_DiagRespData1 : 15|8@0+ (1,0) [0|255] ""  XGW_Body
 SG_ TRM_DiagRespData2 : 23|8@0+ (1,0) [0|255] ""  XGW_Body
 SG_ TRM_DiagRespData3 : 31|8@0+ (1,0) [0|255] "-"  XGW_Body
 SG_ TRM_DiagRespData4 : 39|8@0+ (1,0) [0|255] "-"  XGW_Body
 SG_ TRM_DiagRespData5 : 47|8@0+ (1,0) [0|255] "-"  XGW_Body
 SG_ TRM_DiagRespData6 : 55|8@0+ (1,0) [0|255] ""  XGW_Body
 SG_ TRM_DiagRespData7 : 63|8@0+ (1,0) [0|255] "-"  XGW_Body

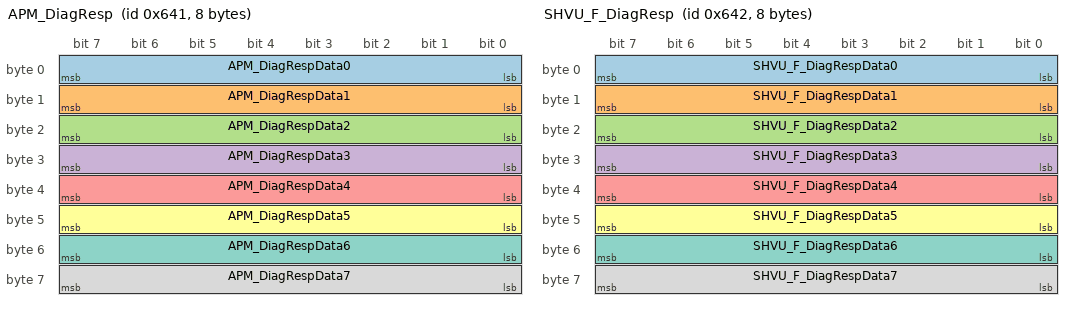
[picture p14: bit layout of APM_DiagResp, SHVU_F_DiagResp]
BO_ 1601 APM_DiagResp: 8 APM
 SG_ APM_DiagRespData0 : 7|8@0+ (1,0) [0|255] ""  XGW_Body
 SG_ APM_DiagRespData1 : 15|8@0+ (1,0) [0|255] ""  XGW_Body
 SG_ APM_DiagRespData2 : 23|8@0+ (1,0) [0|255] ""  XGW_Body
 SG_ APM_DiagRespData3 : 31|8@0+ (1,0) [0|255] ""  XGW_Body
 SG_ APM_DiagRespData4 : 39|8@0+ (1,0) [0|255] "-"  XGW_Body
 SG_ APM_DiagRespData5 : 47|8@0+ (1,0) [0|255] ""  XGW_Body
 SG_ APM_DiagRespData6 : 55|8@0+ (1,0) [0|255] "-"  XGW_Body
 SG_ APM_DiagRespData7 : 63|8@0+ (1,0) [0|255] ""  XGW_Body

BO_ 1602 SHVU_F_DiagResp: 8 SHVU_F
 SG_ SHVU_F_DiagRespData0 : 7|8@0+ (1,0) [0|255] ""  XGW_Body
 SG_ SHVU_F_DiagRespData1 : 15|8@0+ (1,0) [0|255] ""  XGW_Body
 SG_ SHVU_F_DiagRespData2 : 23|8@0+ (1,0) [0|255] "-"  XGW_Body
 SG_ SHVU_F_DiagRespData3 : 31|8@0+ (1,0) [0|255] ""  XGW_Body
 SG_ SHVU_F_DiagRespData4 : 39|8@0+ (1,0) [0|255] ""  XGW_Body
 SG_ SHVU_F_DiagRespData5 : 47|8@0+ (1,0) [0|255] ""  XGW_Body
 SG_ SHVU_F_DiagRespData6 : 55|8@0+ (1,0) [0|255] "-"  XGW_Body
 SG_ SHVU_F_DiagRespData7 : 63|8@0+ (1,0) [0|255] ""  XGW_Body

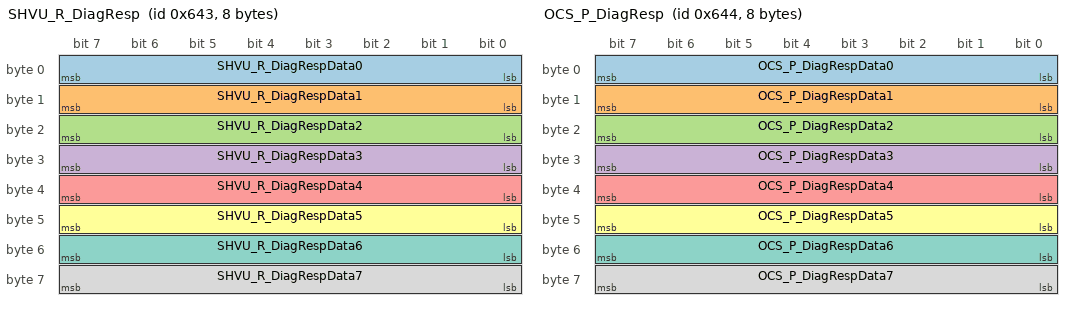
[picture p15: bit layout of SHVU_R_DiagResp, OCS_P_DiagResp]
BO_ 1603 SHVU_R_DiagResp: 8 SHVU_R
 SG_ SHVU_R_DiagRespData0 : 7|8@0+ (1,0) [0|255] ""  XGW_Body
 SG_ SHVU_R_DiagRespData1 : 15|8@0+ (1,0) [0|255] "-"  XGW_Body
 SG_ SHVU_R_DiagRespData2 : 23|8@0+ (1,0) [0|255] ""  XGW_Body
 SG_ SHVU_R_DiagRespData3 : 31|8@0+ (1,0) [0|255] "-"  XGW_Body
 SG_ SHVU_R_DiagRespData4 : 39|8@0+ (1,0) [0|255] "-"  XGW_Body
 SG_ SHVU_R_DiagRespData5 : 47|8@0+ (1,0) [0|255] ""  XGW_Body
 SG_ SHVU_R_DiagRespData6 : 55|8@0+ (1,0) [0|255] "-"  XGW_Body
 SG_ SHVU_R_DiagRespData7 : 63|8@0+ (1,0) [0|255] ""  XGW_Body

BO_ 1604 OCS_P_DiagResp: 8 OCS_P
 SG_ OCS_P_DiagRespData0 : 7|8@0+ (1,0) [0|255] ""  XGW_Body
 SG_ OCS_P_DiagRespData1 : 15|8@0+ (1,0) [0|255] "-"  XGW_Body
 SG_ OCS_P_DiagRespData2 : 23|8@0+ (1,0) [0|255] ""  XGW_Body
 SG_ OCS_P_DiagRespData3 : 31|8@0+ (1,0) [0|255] "-"  XGW_Body
 SG_ OCS_P_DiagRespData4 : 39|8@0+ (1,0) [0|255] ""  XGW_Body
 SG_ OCS_P_DiagRespData5 : 47|8@0+ (1,0) [0|255] ""  XGW_Body
 SG_ OCS_P_DiagRespData6 : 55|8@0+ (1,0) [0|255] ""  XGW_Body
 SG_ OCS_P_DiagRespData7 : 63|8@0+ (1,0) [0|255] ""  XGW_Body

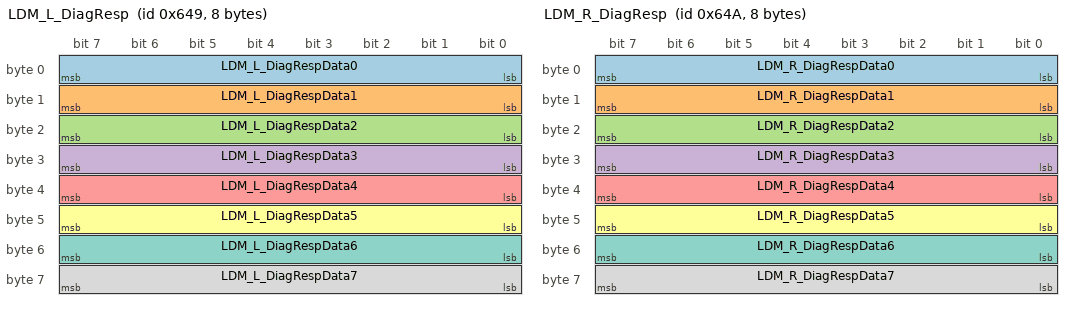
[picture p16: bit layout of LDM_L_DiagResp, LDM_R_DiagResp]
BO_ 1609 LDM_L_DiagResp: 8 LDM_L
 SG_ LDM_L_DiagRespData0 : 7|8@0+ (1,0) [0|255] "-"  XGW_Body
 SG_ LDM_L_DiagRespData1 : 15|8@0+ (1,0) [0|255] ""  XGW_Body
 SG_ LDM_L_DiagRespData2 : 23|8@0+ (1,0) [0|255] "-"  XGW_Body
 SG_ LDM_L_DiagRespData3 : 31|8@0+ (1,0) [0|255] ""  XGW_Body
 SG_ LDM_L_DiagRespData4 : 39|8@0+ (1,0) [0|255] ""  XGW_Body
 SG_ LDM_L_DiagRespData5 : 47|8@0+ (1,0) [0|255] "-"  XGW_Body
 SG_ LDM_L_DiagRespData6 : 55|8@0+ (1,0) [0|255] ""  XGW_Body
 SG_ LDM_L_DiagRespData7 : 63|8@0+ (1,0) [0|255] "-"  XGW_Body

BO_ 1610 LDM_R_DiagResp: 8 LDM_R
 SG_ LDM_R_DiagRespData0 : 7|8@0+ (1,0) [0|255] ""  XGW_Body
 SG_ LDM_R_DiagRespData1 : 15|8@0+ (1,0) [0|255] "-"  XGW_Body
 SG_ LDM_R_DiagRespData2 : 23|8@0+ (1,0) [0|255] ""  XGW_Body
 SG_ LDM_R_DiagRespData3 : 31|8@0+ (1,0) [0|255] ""  XGW_Body
 SG_ LDM_R_DiagRespData4 : 39|8@0+ (1,0) [0|255] "-"  XGW_Body
 SG_ LDM_R_DiagRespData5 : 47|8@0+ (1,0) [0|255] ""  XGW_Body
 SG_ LDM_R_DiagRespData6 : 55|8@0+ (1,0) [0|255] ""  XGW_Body
 SG_ LDM_R_DiagRespData7 : 63|8@0+ (1,0) [0|255] "-"  XGW_Body

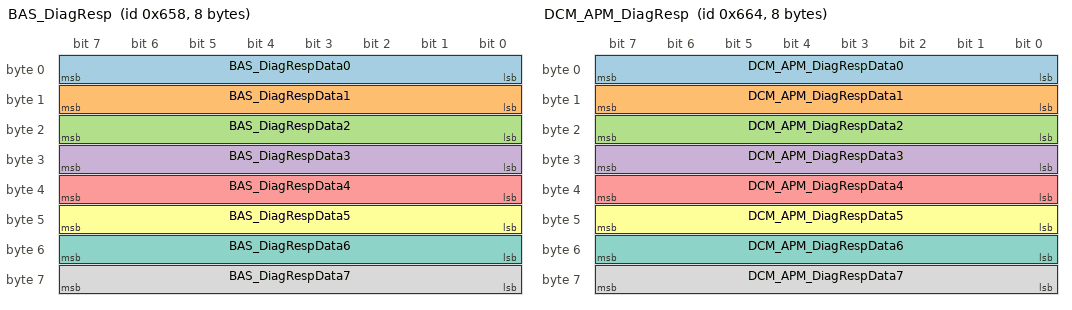
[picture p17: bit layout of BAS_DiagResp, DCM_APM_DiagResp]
BO_ 1624 BAS_DiagResp: 8 BCM
 SG_ BAS_DiagRespData0 : 7|8@0+ (1,0) [0|255] ""  XGW_Body
 SG_ BAS_DiagRespData1 : 15|8@0+ (1,0) [0|255] ""  XGW_Body
 SG_ BAS_DiagRespData2 : 23|8@0+ (1,0) [0|255] ""  XGW_Body
 SG_ BAS_DiagRespData3 : 31|8@0+ (1,0) [0|255] ""  XGW_Body
 SG_ BAS_DiagRespData4 : 39|8@0+ (1,0) [0|255] ""  XGW_Body
 SG_ BAS_DiagRespData5 : 47|8@0+ (1,0) [0|255] ""  XGW_Body
 SG_ BAS_DiagRespData6 : 55|8@0+ (1,0) [0|255] ""  XGW_Body
 SG_ BAS_DiagRespData7 : 63|8@0+ (1,0) [0|255] ""  XGW_Body

BO_ 1636 DCM_APM_DiagResp: 8 APM
 SG_ DCM_APM_DiagRespData0 : 7|8@0+ (1,0) [0|255] "-"  XGW_Body
 SG_ DCM_APM_DiagRespData1 : 15|8@0+ (1,0) [0|255] "-"  XGW_Body
 SG_ DCM_APM_DiagRespData2 : 23|8@0+ (1,0) [0|255] ""  XGW_Body
 SG_ DCM_APM_DiagRespData3 : 31|8@0+ (1,0) [0|255] "-"  XGW_Body
 SG_ DCM_APM_DiagRespData4 : 39|8@0+ (1,0) [0|255] ""  XGW_Body
 SG_ DCM_APM_DiagRespData5 : 47|8@0+ (1,0) [0|255] "-"  XGW_Body
 SG_ DCM_APM_DiagRespData6 : 55|8@0+ (1,0) [0|255] "-"  XGW_Body
 SG_ DCM_APM_DiagRespData7 : 63|8@0+ (1,0) [0|255] ""  XGW_Body

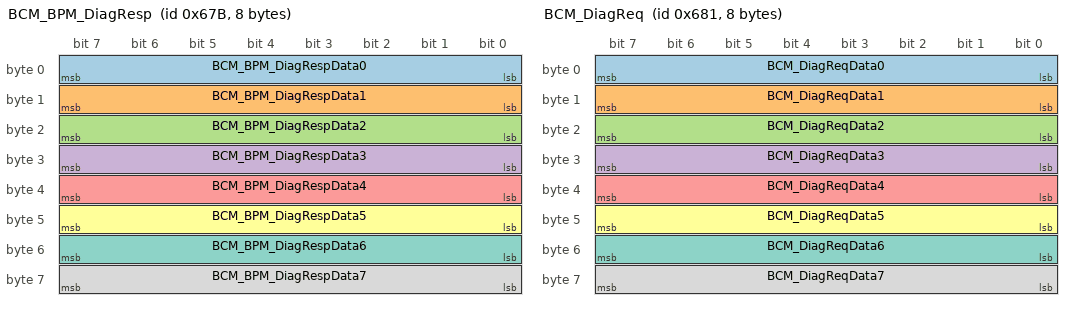
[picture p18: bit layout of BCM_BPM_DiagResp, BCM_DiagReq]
BO_ 1659 BCM_BPM_DiagResp: 8 BCM
 SG_ BCM_BPM_DiagRespData0 : 7|8@0+ (1,0) [0|255] ""  XGW_Body
 SG_ BCM_BPM_DiagRespData1 : 15|8@0+ (1,0) [0|255] "-"  XGW_Body
 SG_ BCM_BPM_DiagRespData2 : 23|8@0+ (1,0) [0|255] ""  XGW_Body
 SG_ BCM_BPM_DiagRespData3 : 31|8@0+ (1,0) [0|255] ""  XGW_Body
 SG_ BCM_BPM_DiagRespData4 : 39|8@0+ (1,0) [0|255] "-"  XGW_Body
 SG_ BCM_BPM_DiagRespData5 : 47|8@0+ (1,0) [0|255] ""  XGW_Body
 SG_ BCM_BPM_DiagRespData6 : 55|8@0+ (1,0) [0|255] "-"  XGW_Body
 SG_ BCM_BPM_DiagRespData7 : 63|8@0+ (1,0) [0|255] ""  XGW_Body

BO_ 1665 BCM_DiagReq: 8 XGW_Body
 SG_ BCM_DiagReqData0 : 7|8@0+ (1,0) [0|255] ""  BCM
 SG_ BCM_DiagReqData1 : 15|8@0+ (1,0) [0|255] ""  BCM
 SG_ BCM_DiagReqData2 : 23|8@0+ (1,0) [0|255] ""  BCM
 SG_ BCM_DiagReqData3 : 31|8@0+ (1,0) [0|255] ""  BCM
 SG_ BCM_DiagReqData4 : 39|8@0+ (1,0) [0|255] ""  BCM
 SG_ BCM_DiagReqData5 : 47|8@0+ (1,0) [0|255] ""  BCM
 SG_ BCM_DiagReqData6 : 55|8@0+ (1,0) [0|255] "-"  BCM
 SG_ BCM_DiagReqData7 : 63|8@0+ (1,0) [0|255] "-"  BCM

BO_ 1672 ACM_DiagReq: 8 XGW_Body
 SG_ ACM_DiagReqData0 : 7|8@0+ (1,0) [0|255] ""  ACM
 SG_ ACM_DiagReqData1 : 15|8@0+ (1,0) [0|255] ""  ACM
 SG_ ACM_DiagReqData2 : 23|8@0+ (1,0) [0|255] ""  ACM
 SG_ ACM_DiagReqData3 : 31|8@0+ (1,0) [0|255] "-"  ACM
 SG_ ACM_DiagReqData4 : 39|8@0+ (1,0) [0|255] ""  ACM
 SG_ ACM_DiagReqData5 : 47|8@0+ (1,0) [0|255] ""  ACM
 SG_ ACM_DiagReqData6 : 55|8@0+ (1,0) [0|255] "-"  ACM
 SG_ ACM_DiagReqData7 : 63|8@0+ (1,0) [0|255] ""  ACM

BO_ 1673 CCUF_DiagReq: 8 XGW_Body
 SG_ CCUF_DiagReqData0 : 7|8@0+ (1,0) [0|255] "-"  CCU_F
 SG_ CCUF_DiagReqData1 : 15|8@0+ (1,0) [0|255] ""  CCU_F
 SG_ CCUF_DiagReqData2 : 23|8@0+ (1,0) [0|255] ""  CCU_F
 SG_ CCUF_DiagReqData3 : 31|8@0+ (1,0) [0|255] ""  CCU_F
 SG_ CCUF_DiagReqData4 : 39|8@0+ (1,0) [0|255] ""  CCU_F
 SG_ CCUF_DiagReqData5 : 47|8@0+ (1,0) [0|255] ""  CCU_F
 SG_ CCUF_DiagReqData6 : 55|8@0+ (1,0) [0|255] ""  CCU_F
 SG_ CCUF_DiagReqData7 : 63|8@0+ (1,0) [0|255] ""  CCU_F

BO_ 1678 ETG_DiagReq: 8 XGW_Body
 SG_ ETG_DiagReqData0 : 7|8@0+ (1,0) [0|255] ""  ETG
 SG_ ETG_DiagReqData1 : 15|8@0+ (1,0) [0|255] ""  ETG
 SG_ ETG_DiagReqData2 : 23|8@0+ (1,0) [0|255] ""  ETG
 SG_ ETG_DiagReqData3 : 31|8@0+ (1,0) [0|255] ""  ETG
 SG_ ETG_DiagReqData4 : 39|8@0+ (1,0) [0|255] ""  ETG
 SG_ ETG_DiagReqData5 : 47|8@0+ (1,0) [0|255] ""  ETG
 SG_ ETG_DiagReqData6 : 55|8@0+ (1,0) [0|255] ""  ETG
 SG_ ETG_DiagReqData7 : 63|8@0+ (1,0) [0|255] "-"  ETG

BO_ 1681 ASU_Gateway_DiagReq: 8 XGW_Body
 SG_ ASU_Gateway_DiagReqData0 : 7|8@0+ (1,0) [0|255] "-"  ASU_Gateway
 SG_ ASU_Gateway_DiagReqData1 : 15|8@0+ (1,0) [0|255] "-"  ASU_Gateway
 SG_ ASU_Gateway_DiagReqData2 : 23|8@0+ (1,0) [0|255] "-"  ASU_Gateway
 SG_ ASU_Gateway_DiagReqData3 : 31|8@0+ (1,0) [0|255] "-"  ASU_Gateway
 SG_ ASU_Gateway_DiagReqData4 : 39|8@0+ (1,0) [0|255] "-"  ASU_Gateway
 SG_ ASU_Gateway_DiagReqData5 : 47|8@0+ (1,0) [0|255] "-"  ASU_Gateway
 SG_ ASU_Gateway_DiagReqData6 : 55|8@0+ (1,0) [0|255] "-"  ASU_Gateway
 SG_ ASU_Gateway_DiagReqData7 : 63|8@0+ (1,0) [0|255] "-"  ASU_Gateway

BO_ 1684 CCUR_DiagReq: 8 XGW_Body
 SG_ CCUR_DiagReqData0 : 7|8@0+ (1,0) [0|255] ""  CCU_R
 SG_ CCUR_DiagReqData1 : 15|8@0+ (1,0) [0|255] ""  CCU_R
 SG_ CCUR_DiagReqData2 : 23|8@0+ (1,0) [0|255] ""  CCU_R
 SG_ CCUR_DiagReqData3 : 31|8@0+ (1,0) [0|255] "-"  CCU_R
 SG_ CCUR_DiagReqData4 : 39|8@0+ (1,0) [0|255] "-"  CCU_R
 SG_ CCUR_DiagReqData5 : 47|8@0+ (1,0) [0|255] ""  CCU_R
 SG_ CCUR_DiagReqData6 : 55|8@0+ (1,0) [0|255] ""  CCU_R
 SG_ CCUR_DiagReqData7 : 63|8@0+ (1,0) [0|255] ""  CCU_R

BO_ 1694 PSM_D_DiagReq: 8 XGW_Body
 SG_ PSM_D_DiagReqData0 : 7|8@0+ (1,0) [0|255] "-"  PSM_D
 SG_ PSM_D_DiagReqData1 : 15|8@0+ (1,0) [0|255] ""  PSM_D
 SG_ PSM_D_DiagReqData2 : 23|8@0+ (1,0) [0|255] "-"  PSM_D
 SG_ PSM_D_DiagReqData3 : 31|8@0+ (1,0) [0|255] ""  PSM_D
 SG_ PSM_D_DiagReqData4 : 39|8@0+ (1,0) [0|255] ""  PSM_D
 SG_ PSM_D_DiagReqData5 : 47|8@0+ (1,0) [0|255] "-"  PSM_D
 SG_ PSM_D_DiagReqData6 : 55|8@0+ (1,0) [0|255] "-"  PSM_D
 SG_ PSM_D_DiagReqData7 : 63|8@0+ (1,0) [0|255] ""  PSM_D

BO_ 1713 USS_R_DiagReq: 8 XGW_Body
 SG_ USS_R_DiagReqData0 : 7|8@0+ (1,0) [0|255] "-"  USS_R
 SG_ USS_R_DiagReqData1 : 15|8@0+ (1,0) [0|255] ""  USS_R
 SG_ USS_R_DiagReqData2 : 23|8@0+ (1,0) [0|255] "-"  USS_R
 SG_ USS_R_DiagReqData3 : 31|8@0+ (1,0) [0|255] ""  USS_R
 SG_ USS_R_DiagReqData4 : 39|8@0+ (1,0) [0|255] ""  USS_R
 SG_ USS_R_DiagReqData5 : 47|8@0+ (1,0) [0|255] "-"  USS_R
 SG_ USS_R_DiagReqData6 : 55|8@0+ (1,0) [0|255] "-"  USS_R
 SG_ USS_R_DiagReqData7 : 63|8@0+ (1,0) [0|255] ""  USS_R

BO_ 1714 USS_F_DiagReq: 8 XGW_Body
 SG_ USS_F_DiagReqData0 : 7|8@0+ (1,0) [0|255] "-"  USS_F
 SG_ USS_F_DiagReqData1 : 15|8@0+ (1,0) [0|255] ""  USS_F
 SG_ USS_F_DiagReqData2 : 23|8@0+ (1,0) [0|255] "-"  USS_F
 SG_ USS_F_DiagReqData3 : 31|8@0+ (1,0) [0|255] ""  USS_F
 SG_ USS_F_DiagReqData4 : 39|8@0+ (1,0) [0|255] ""  USS_F
 SG_ USS_F_DiagReqData5 : 47|8@0+ (1,0) [0|255] "-"  USS_F
 SG_ USS_F_DiagReqData6 : 55|8@0+ (1,0) [0|255] "-"  USS_F
 SG_ USS_F_DiagReqData7 : 63|8@0+ (1,0) [0|255] ""  USS_F

BO_ 1721 SRR_RR_M_DiagReq: 8 XGW_Body
 SG_ SRR_RR_M_DiagReq_Data0 : 7|8@0+ (1,0) [0|255] "-"  SRR_RR_M
 SG_ SRR_RR_M_DiagReq_Data1 : 15|8@0+ (1,0) [0|255] ""  SRR_RR_M
 SG_ SRR_RR_M_DiagReq_Data2 : 23|8@0+ (1,0) [0|255] "-"  SRR_RR_M
 SG_ SRR_RR_M_DiagReq_Data3 : 31|8@0+ (1,0) [0|255] ""  SRR_RR_M
 SG_ SRR_RR_M_DiagReq_Data4 : 39|8@0+ (1,0) [0|255] ""  SRR_RR_M
 SG_ SRR_RR_M_DiagReq_Data5 : 47|8@0+ (1,0) [0|255] "-"  SRR_RR_M
 SG_ SRR_RR_M_DiagReq_Data6 : 55|8@0+ (1,0) [0|255] "-"  SRR_RR_M
 SG_ SRR_RR_M_DiagReq_Data7 : 63|8@0+ (1,0) [0|255] ""  SRR_RR_M

BO_ 1723 TRM_DiagReq: 8 XGW_Body
 SG_ TRM_DiagReqData0 : 7|8@0+ (1,0) [0|255] ""  TRM
 SG_ TRM_DiagReqData1 : 15|8@0+ (1,0) [0|255] ""  TRM
 SG_ TRM_DiagReqData2 : 23|8@0+ (1,0) [0|255] "-"  TRM
 SG_ TRM_DiagReqData3 : 31|8@0+ (1,0) [0|255] "-"  TRM
 SG_ TRM_DiagReqData4 : 39|8@0+ (1,0) [0|255] "-"  TRM
 SG_ TRM_DiagReqData5 : 47|8@0+ (1,0) [0|255] ""  TRM
 SG_ TRM_DiagReqData6 : 55|8@0+ (1,0) [0|255] ""  TRM
 SG_ TRM_DiagReqData7 : 63|8@0+ (1,0) [0|255] "-"  TRM

BO_ 1729 APM_DiagReq: 8 XGW_Body
 SG_ APM_DiagReqData0 : 7|8@0+ (1,0) [0|255] ""  APM
 SG_ APM_DiagReqData1 : 15|8@0+ (1,0) [0|255] ""  APM
 SG_ APM_DiagReqData2 : 23|8@0+ (1,0) [0|255] "-"  APM
 SG_ APM_DiagReqData3 : 31|8@0+ (1,0) [0|255] ""  APM
 SG_ APM_DiagReqData4 : 39|8@0+ (1,0) [0|255] ""  APM
 SG_ APM_DiagReqData5 : 47|8@0+ (1,0) [0|255] "-"  APM
 SG_ APM_DiagReqData6 : 55|8@0+ (1,0) [0|255] ""  APM
 SG_ APM_DiagReqData7 : 63|8@0+ (1,0) [0|255] ""  APM

BO_ 1730 SHVU_F_DiagReq: 8 XGW_Body
 SG_ SHVU_F_DiagReqData0 : 7|8@0+ (1,0) [0|255] ""  SHVU_F
 SG_ SHVU_F_DiagReqData1 : 15|8@0+ (1,0) [0|255] ""  SHVU_F
 SG_ SHVU_F_DiagReqData2 : 23|8@0+ (1,0) [0|255] ""  SHVU_F
 SG_ SHVU_F_DiagReqData3 : 31|8@0+ (1,0) [0|255] "-"  SHVU_F
 SG_ SHVU_F_DiagReqData4 : 39|8@0+ (1,0) [0|255] ""  SHVU_F
 SG_ SHVU_F_DiagReqData5 : 47|8@0+ (1,0) [0|255] ""  SHVU_F
 SG_ SHVU_F_DiagReqData6 : 55|8@0+ (1,0) [0|255] "-"  SHVU_F
 SG_ SHVU_F_DiagReqData7 : 63|8@0+ (1,0) [0|255] ""  SHVU_F

BO_ 1731 SHVU_R_DiagReq: 8 XGW_Body
 SG_ SHVU_R_DiagReqData0 : 7|8@0+ (1,0) [0|255] ""  SHVU_R
 SG_ SHVU_R_DiagReqData1 : 15|8@0+ (1,0) [0|255] ""  SHVU_R
 SG_ SHVU_R_DiagReqData2 : 23|8@0+ (1,0) [0|255] ""  SHVU_R
 SG_ SHVU_R_DiagReqData3 : 31|8@0+ (1,0) [0|255] ""  SHVU_R
 SG_ SHVU_R_DiagReqData4 : 39|8@0+ (1,0) [0|255] ""  SHVU_R
 SG_ SHVU_R_DiagReqData5 : 47|8@0+ (1,0) [0|255] "-"  SHVU_R
 SG_ SHVU_R_DiagReqData6 : 55|8@0+ (1,0) [0|255] ""  SHVU_R
 SG_ SHVU_R_DiagReqData7 : 63|8@0+ (1,0) [0|255] ""  SHVU_R

BO_ 1732 OCS_P_DiagReq: 8 XGW_Body
 SG_ OCS_P_DiagReqData0 : 7|8@0+ (1,0) [0|255] "-"  OCS_P
 SG_ OCS_P_DiagReqData1 : 15|8@0+ (1,0) [0|255] ""  OCS_P
 SG_ OCS_P_DiagReqData2 : 23|8@0+ (1,0) [0|255] ""  OCS_P
 SG_ OCS_P_DiagReqData3 : 31|8@0+ (1,0) [0|255] ""  OCS_P
 SG_ OCS_P_DiagReqData4 : 39|8@0+ (1,0) [0|255] ""  OCS_P
 SG_ OCS_P_DiagReqData5 : 47|8@0+ (1,0) [0|255] ""  OCS_P
 SG_ OCS_P_DiagReqData6 : 55|8@0+ (1,0) [0|255] ""  OCS_P
 SG_ OCS_P_DiagReqData7 : 63|8@0+ (1,0) [0|255] "-"  OCS_P

BO_ 1737 LDM_L_DiagReq: 8 XGW_Body
 SG_ LDM_L_DiagReqData0 : 7|8@0+ (1,0) [0|255] "-"  LDM_L
 SG_ LDM_L_DiagReqData1 : 15|8@0+ (1,0) [0|255] ""  LDM_L
 SG_ LDM_L_DiagReqData2 : 23|8@0+ (1,0) [0|255] ""  LDM_L
 SG_ LDM_L_DiagReqData3 : 31|8@0+ (1,0) [0|255] ""  LDM_L
 SG_ LDM_L_DiagReqData4 : 39|8@0+ (1,0) [0|255] "-"  LDM_L
 SG_ LDM_L_DiagReqData5 : 47|8@0+ (1,0) [0|255] ""  LDM_L
 SG_ LDM_L_DiagReqData6 : 55|8@0+ (1,0) [0|255] ""  LDM_L
 SG_ LDM_L_DiagReqData7 : 63|8@0+ (1,0) [0|255] ""  LDM_L

BO_ 1738 LDM_R_DiagReq: 8 XGW_Body
 SG_ LDM_R_DiagReqData0 : 7|8@0+ (1,0) [0|255] ""  LDM_R
 SG_ LDM_R_DiagReqData1 : 15|8@0+ (1,0) [0|255] ""  LDM_R
 SG_ LDM_R_DiagReqData2 : 23|8@0+ (1,0) [0|255] ""  LDM_R
 SG_ LDM_R_DiagReqData3 : 31|8@0+ (1,0) [0|255] "-"  LDM_R
 SG_ LDM_R_DiagReqData4 : 39|8@0+ (1,0) [0|255] ""  LDM_R
 SG_ LDM_R_DiagReqData5 : 47|8@0+ (1,0) [0|255] ""  LDM_R
 SG_ LDM_R_DiagReqData6 : 55|8@0+ (1,0) [0|255] "-"  LDM_R
 SG_ LDM_R_DiagReqData7 : 63|8@0+ (1,0) [0|255] "-"  LDM_R

BO_ 1752 BAS_DiagReq: 8 XGW_Body
 SG_ BAS_DiagReqData0 : 7|8@0+ (1,0) [0|255] ""  BCM
 SG_ BAS_DiagReqData1 : 15|8@0+ (1,0) [0|255] ""  BCM
 SG_ BAS_DiagReqData2 : 23|8@0+ (1,0) [0|255] ""  BCM
 SG_ BAS_DiagReqData3 : 31|8@0+ (1,0) [0|255] ""  BCM
 SG_ BAS_DiagReqData4 : 39|8@0+ (1,0) [0|255] ""  BCM
 SG_ BAS_DiagReqData5 : 47|8@0+ (1,0) [0|255] ""  BCM
 SG_ BAS_DiagReqData6 : 55|8@0+ (1,0) [0|255] ""  BCM
 SG_ BAS_DiagReqData7 : 63|8@0+ (1,0) [0|255] ""  ACM,BCM

BO_ 1764 DCM_APM_DiagReq: 8 XGW_Body
 SG_ DCM_APM_DiagReqData0 : 7|8@0+ (1,0) [0|255] "-"  APM,BCM
 SG_ DCM_APM_DiagReqData1 : 15|8@0+ (1,0) [0|255] "-"  APM
 SG_ DCM_APM_DiagReqData2 : 23|8@0+ (1,0) [0|255] "-"  APM
 SG_ DCM_APM_DiagReqData3 : 31|8@0+ (1,0) [0|255] "-"  APM
 SG_ DCM_APM_DiagReqData4 : 39|8@0+ (1,0) [0|255] ""  APM
 SG_ DCM_APM_DiagReqData5 : 47|8@0+ (1,0) [0|255] ""  APM
 SG_ DCM_APM_DiagReqData6 : 55|8@0+ (1,0) [0|255] ""  APM
 SG_ DCM_APM_DiagReqData7 : 63|8@0+ (1,0) [0|255] ""  APM

BO_ 1777 ASU_DiagReq: 8 XGW_Body
 SG_ ASU_DiagReqData0 : 7|8@0+ (1,0) [0|255] "-"  ASU_Gateway
 SG_ ASU_DiagReqData1 : 15|8@0+ (1,0) [0|255] "-"  ASU_Gateway
 SG_ ASU_DiagReqData2 : 23|8@0+ (1,0) [0|255] "-"  ASU_Gateway
 SG_ ASU_DiagReqData3 : 31|8@0+ (1,0) [0|255] "-"  ASU_Gateway
 SG_ ASU_DiagReqData4 : 39|8@0+ (1,0) [0|255] "-"  ASU_Gateway
 SG_ ASU_DiagReqData5 : 47|8@0+ (1,0) [0|255] "-"  ASU_Gateway
 SG_ ASU_DiagReqData6 : 55|8@0+ (1,0) [0|255] "-"  ASU_Gateway
 SG_ ASU_DiagReqData7 : 63|8@0+ (1,0) [0|255] "-"  ASU_Gateway

BO_ 1787 BCM_BPM_DiagReq: 8 XGW_Body
 SG_ BCM_BPM_DiagReqData0 : 7|8@0+ (1,0) [0|255] "-"  DUMMY_BCM_BPM
 SG_ BCM_BPM_DiagReqData1 : 15|8@0+ (1,0) [0|255] ""  DUMMY_BCM_BPM
 SG_ BCM_BPM_DiagReqData2 : 23|8@0+ (1,0) [0|255] ""  DUMMY_BCM_BPM
 SG_ BCM_BPM_DiagReqData3 : 31|8@0+ (1,0) [0|255] ""  DUMMY_BCM_BPM
 SG_ BCM_BPM_DiagReqData4 : 39|8@0+ (1,0) [0|255] ""  DUMMY_BCM_BPM
 SG_ BCM_BPM_DiagReqData5 : 47|8@0+ (1,0) [0|255] ""  DUMMY_BCM_BPM
 SG_ BCM_BPM_DiagReqData6 : 55|8@0+ (1,0) [0|255] "-"  DUMMY_BCM_BPM
 SG_ BCM_BPM_DiagReqData7 : 63|8@0+ (1,0) [0|255] "-"  DUMMY_BCM_BPM

BO_ 1791 DIAG_Req_All_Ecu: 8 XGW_Body
 SG_ OBD_Func_DiagReqData0 : 7|8@0+ (1,0) [0|255] ""  ACM,APM,ASU_Gateway,BCM,BCM_BPM,CCU_F,CCU_R,ETG,LDM_L,LDM_R,OCS_P,PSM_D,SHVU_F,SHVU_R,SRR_RR_M,TRM
 SG_ OBD_Func_DiagReqData1 : 15|8@0+ (1,0) [0|255] ""  ACM,APM,ASU_Gateway,BCM,BCM_BPM,CCU_F,CCU_R,ETG,LDM_L,LDM_R,OCS_P,PSM_D,SHVU_F,SHVU_R,SRR_RR_M,TRM
 SG_ OBD_Func_DiagReqData2 : 23|8@0+ (1,0) [0|255] ""  ACM,APM,ASU_Gateway,BCM,BCM_BPM,CCU_F,CCU_R,ETG,LDM_L,LDM_R,OCS_P,PSM_D,SHVU_F,SHVU_R,SRR_RR_M,TRM
 SG_ OBD_Func_DiagReqData3 : 31|8@0+ (1,0) [0|255] ""  ACM,APM,ASU_Gateway,BCM,BCM_BPM,CCU_F,CCU_R,ETG,LDM_L,LDM_R,OCS_P,PSM_D,SHVU_F,SHVU_R,SRR_RR_M,TRM
 SG_ OBD_Func_DiagReqData4 : 39|8@0+ (1,0) [0|255] ""  ACM,APM,ASU_Gateway,BCM,BCM_BPM,CCU_F,CCU_R,ETG,LDM_L,LDM_R,OCS_P,PSM_D,SHVU_F,SHVU_R,SRR_RR_M,TRM
 SG_ OBD_Func_DiagReqData5 : 47|8@0+ (1,0) [0|255] ""  ACM,APM,ASU_Gateway,BCM,BCM_BPM,CCU_F,CCU_R,ETG,LDM_L,LDM_R,OCS_P,PSM_D,SHVU_F,SHVU_R,SRR_RR_M,TRM
 SG_ OBD_Func_DiagReqData6 : 55|8@0+ (1,0) [0|255] ""  ACM,APM,ASU_Gateway,BCM,BCM_BPM,CCU_F,CCU_R,ETG,LDM_L,LDM_R,OCS_P,PSM_D,SHVU_F,SHVU_R,SRR_RR_M,TRM
 SG_ OBD_Func_DiagReqData7 : 63|8@0+ (1,0) [0|255] ""  ACM,APM,ASU_Gateway,BCM,BCM_BPM,CCU_F,CCU_R,ETG,LDM_L,LDM_R,OCS_P,PSM_D,SHVU_F,SHVU_R,SRR_RR_M,TRM

BO_ 1793 SEED_CAN_Req1_CCU_R: 8 CCU_R
 SG_ SEED_CAN_Req1 : 7|64@0+ (1,0) [0|1.84467440737096E+019] ""  CCU_F,XGW_Body

BO_ 1795 SEED_CAN_Req2_CCU_F: 8 CCU_F
 SG_ SEED_CAN_Req2 : 7|64@0+ (1,0) [0|1.84467440737096E+019] ""  CCU_R,XGW_Body

BO_ 1803 SEED_CAN_Req6_BCM: 8 BCM
 SG_ SEED_CAN_Req6 : 7|64@0+ (1,0) [0|1.84467440737096E+019] ""  XGW_Body

BO_ 1805 SEED_CAN_Req7_VCU_PT: 8 XGW_Body
 SG_ SEED_CAN_Req7 : 7|64@0+ (1,0) [0|1.84467440737096E+019] ""  BCM,CCU_F,CCU_R

BO_ 1809 BCM_Data: 8 BCM
 SG_ BCM_Data0 : 7|8@0+ (1,0) [0|255] ""  BCM_BPM
 SG_ BCM_Data1 : 15|8@0+ (1,0) [0|255] ""  BCM_BPM
 SG_ BCM_Data2 : 23|8@0+ (1,0) [0|255] ""  BCM_BPM
 SG_ BCM_Data3 : 31|8@0+ (1,0) [0|255] ""  BCM_BPM
 SG_ BCM_Data4 : 39|8@0+ (1,0) [0|255] ""  BCM_BPM
 SG_ BCM_Data5 : 47|8@0+ (1,0) [0|255] ""  BCM_BPM
 SG_ BCM_Data6 : 55|8@0+ (1,0) [0|255] ""  BCM_BPM
 SG_ BCM_Data7 : 63|8@0+ (1,0) [0|255] ""  BCM_BPM

BO_ 1810 BCM_BPM_Data: 8 BCM
 SG_ BCM_BPM_Data0 : 7|8@0+ (1,0) [0|255] ""  BCM_BPM
 SG_ BCM_BPM_Data1 : 15|8@0+ (1,0) [0|255] ""  BCM_BPM
 SG_ BCM_BPM_Data2 : 23|8@0+ (1,0) [0|255] ""  BCM_BPM
 SG_ BCM_BPM_Data3 : 31|8@0+ (1,0) [0|255] ""  BCM_BPM
 SG_ BCM_BPM_Data4 : 39|8@0+ (1,0) [0|255] ""  BCM_BPM
 SG_ BCM_BPM_Data5 : 47|8@0+ (1,0) [0|255] ""  BCM_BPM
 SG_ BCM_BPM_Data6 : 55|8@0+ (1,0) [0|255] ""  BCM_BPM
 SG_ BCM_BPM_Data7 : 63|8@0+ (1,0) [0|255] ""  BCM_BPM

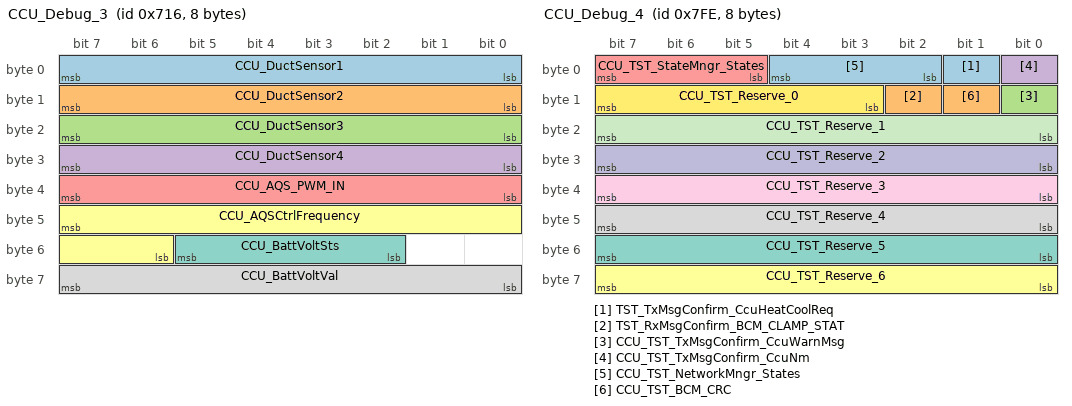
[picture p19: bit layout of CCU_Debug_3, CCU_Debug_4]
BO_ 1814 CCU_Debug_3: 8 CCU_F
 SG_ CCU_DuctSensor1 : 7|8@0+ (0.5,-30) [-30|97.5] "degree C" Vector__XXX
 SG_ CCU_DuctSensor2 : 15|8@0+ (0.5,-30) [-30|97.5] "degree C" Vector__XXX
 SG_ CCU_DuctSensor3 : 23|8@0+ (0.5,-30) [-30|97.5] "degree C" Vector__XXX
 SG_ CCU_DuctSensor4 : 31|8@0+ (0.5,-30) [-30|97.5] "degree C" Vector__XXX
 SG_ CCU_AQS_PWM_IN : 39|8@0+ (0.5,0) [0|100] "%" Vector__XXX
 SG_ CCU_AQSCtrlFrequency : 47|10@0+ (1,0) [0|1000] "Hz" Vector__XXX
 SG_ CCU_BattVoltSts : 53|4@0+ (1,0) [0|14] "" Vector__XXX
 SG_ CCU_BattVoltVal : 63|8@0+ (0.1,0) [0|25] "V" Vector__XXX

BO_ 1843 SEED_CAN_Req18_MHU: 8 XGW_Body
 SG_ SEED_CAN_Req18 : 7|64@0+ (1,0) [0|1.84467440737096E+019] ""  BCM,ETG

BO_ 1847 SEED_CAN_Req21_ETG: 8 ETG
 SG_ SEED_CAN_Req21 : 7|64@0+ (1,0) [0|1.84467440737096E+019] ""  XGW_Body

BO_ 1850 SEED_CAN_Req25_FCAM: 8 XGW_Body
 SG_ SEED_CAN_Req25 : 7|64@0+ (1,0) [0|1.84467440737096E+019] ""  BCM

BO_ 1853 SEED_CAN_Req29_PAS: 8 XGW_Body
 SG_ SEED_CAN_Req29 : 7|64@0+ (1,0) [0|1.84467440737096E+019] ""  BCM

BO_ 1857 CCU_Debug_1: 8 CCU_F
 SG_ CCU_ERL_FL : 7|8@0+ (1,0) [0|255] "" Vector__XXX
 SG_ CCU_ERL_FR : 15|8@0+ (1,0) [0|255] "" Vector__XXX
 SG_ CCU_EvapTempSet : 23|8@0+ (0.1,-5) [-5|20.5] "Degree C" Vector__XXX
 SG_ CCU_BlowerFltPWM : 31|8@0+ (0.5,0) [0|100] "%" Vector__XXX
 SG_ CCU_AirDistribFlapPos : 39|8@0+ (0.5,0) [0|100] "%" Vector__XXX
 SG_ CCU_RecircFlapPos : 47|8@0+ (0.5,0) [0|100] "%" Vector__XXX
 SG_ CCU_AirDistribFeedback : 55|8@0+ (0.05,0) [0|5] "V" Vector__XXX
 SG_ CCU_RecircFlapFeedback : 63|8@0+ (0.05,0) [0|5] "V" Vector__XXX

BO_ 1858 CCU_Debug_2: 8 CCU_F
 SG_ CCU_TempFlapPos_FL : 7|8@0+ (0.5,0) [0|100] "%" Vector__XXX
 SG_ CCU_TempFlapPos_FR : 15|8@0+ (0.5,0) [0|100] "%" Vector__XXX
 SG_ CCU_DuctTargetTemp_FL : 23|8@0+ (0.5,-40) [-40|85] "Degree C" Vector__XXX
 SG_ CCU_DuctTargetTemp_FR : 31|8@0+ (0.5,-40) [-40|85] "Degree C" Vector__XXX
 SG_ CCU_TempFLFeedback : 39|8@0+ (0.05,0) [0|5] "V" Vector__XXX
 SG_ CCU_TempFRFeedback : 47|8@0+ (0.05,0) [0|5] "V" Vector__XXX
 SG_ CCU_PTCSetTemp : 55|8@0+ (0.5,0) [0|127] "Degree C" Vector__XXX

BO_ 2046 CCU_Debug_4: 8 CCU_F
 SG_ TST_TxMsgConfirm_CcuHeatCoolReq : 1|1@0+ (1,0) [0|1] ""  DUMMY_ECU
 SG_ TST_RxMsgConfirm_BCM_CLAMP_STAT : 10|1@0+ (1,0) [0|1] ""  DUMMY_ECU
 SG_ CCU_TST_TxMsgConfirm_CcuWarnMsg : 8|1@0+ (1,0) [0|1] ""  DUMMY_ECU
 SG_ CCU_TST_TxMsgConfirm_CcuNm : 0|1@0+ (1,0) [0|1] ""  DUMMY_ECU
 SG_ CCU_TST_StateMngr_States : 7|3@0+ (1,0) [0|7] ""  DUMMY_ECU
 SG_ CCU_TST_Reserve_6 : 63|8@0+ (1,0) [0|255] ""  DUMMY_ECU
 SG_ CCU_TST_Reserve_5 : 55|8@0+ (1,0) [0|255] ""  DUMMY_ECU
 SG_ CCU_TST_Reserve_4 : 47|8@0+ (1,0) [0|255] ""  DUMMY_ECU
 SG_ CCU_TST_Reserve_3 : 39|8@0+ (1,0) [0|255] ""  DUMMY_ECU
 SG_ CCU_TST_Reserve_2 : 31|8@0+ (1,0) [0|255] ""  DUMMY_ECU
 SG_ CCU_TST_Reserve_1 : 23|8@0+ (1,0) [0|255] ""  DUMMY_ECU
 SG_ CCU_TST_Reserve_0 : 15|5@0+ (1,0) [0|31] "" Vector__XXX
 SG_ CCU_TST_NetworkMngr_States : 4|3@0+ (1,0) [0|7] ""  DUMMY_ECU
 SG_ CCU_TST_BCM_CRC : 9|1@0+ (1,0) [0|1] ""  DUMMY_ECU

BO_ 1938 CCU_Resp_CCP: 8 CCU_F
 SG_ CCU_Resp_CCP : 7|64@0+ (1,0) [0|0] "" Vector__XXX

BO_ 1939 Internal_MSG_1: 8 LDM_L
 SG_ LDML_FltReactn : 7|32@0+ (1,0) [0|4294967295] ""  LDM_R
 SG_ LDML_RiAdjstAgOutp : 39|11@0+ (0.01,-10) [-10|10] "degree"  LDM_R

BO_ 1940 Internal_MSG_2: 8 LDM_R
 SG_ LDMR_FltReactn : 7|32@0+ (1,0) [0|4294967295] ""  LDM_L
 SG_ LDMR_ModuleCurAg : 39|11@0+ (0.01,-10) [-10|10] "degree"  LDM_L

BO_ 1977 CCU_Resp_EOL: 8 CCU_F
 SG_ CCU_Resp_EOL : 7|64@0+ (1,0) [0|0] "" Vector__XXX

BO_ 1980 CCUR_Resp_EOL: 8 CCU_R
 SG_ CCUR_Resp_EOL_ : 7|64@0+ (1,0) [0|0] "" Vector__XXX

BO_ 2015 Diag_Request_ECU: 8 XGW_Body
 SG_ Diag_Request_ECU_Data0 : 7|8@0+ (1,0) [0|255] ""  ACM,APM,BCM,BCM_BPM,CCU_F,ETG,LDM_L,LDM_R,OCS_P,PSM_D,SHVU_F,SHVU_R,TRM
 SG_ Diag_Request_ECU_Data1 : 15|8@0+ (1,0) [0|255] "-"  ACM,APM,BCM,BCM_BPM,CCU_F,ETG,LDM_L,LDM_R,OCS_P,PSM_D,SHVU_F,SHVU_R,TRM
 SG_ Diag_Request_ECU_Data2 : 23|8@0+ (1,0) [0|255] "-"  ACM,APM,BCM,BCM_BPM,CCU_F,ETG,LDM_L,LDM_R,OCS_P,PSM_D,SHVU_F,SHVU_R,TRM
 SG_ Diag_Request_ECU_Data3 : 31|8@0+ (1,0) [0|255] ""  ACM,APM,BCM,BCM_BPM,CCU_F,ETG,LDM_L,LDM_R,OCS_P,PSM_D,SHVU_F,SHVU_R,TRM
 SG_ Diag_Request_ECU_Data4 : 39|8@0+ (1,0) [0|255] "-"  ACM,APM,BCM,BCM_BPM,CCU_F,ETG,LDM_L,LDM_R,OCS_P,PSM_D,SHVU_F,SHVU_R,TRM
 SG_ Diag_Request_ECU_Data5 : 47|8@0+ (1,0) [0|255] ""  ACM,APM,BCM,BCM_BPM,CCU_F,ETG,LDM_L,LDM_R,OCS_P,PSM_D,SHVU_F,SHVU_R,TRM
 SG_ Diag_Request_ECU_Data6 : 55|8@0+ (1,0) [0|255] "-"  ACM,APM,BCM,BCM_BPM,CCU_F,ETG,LDM_L,LDM_R,OCS_P,PSM_D,SHVU_F,SHVU_R,TRM
 SG_ Diag_Request_ECU_Data7 : 63|8@0+ (1,0) [0|255] ""  ACM,APM,BCM,BCM_BPM,CCU_F,ETG,LDM_L,LDM_R,OCS_P,PSM_D,SHVU_F,SHVU_R,TRM

BO_ 2033 DIAG_Req_Airbag_Deploy: 8 XGW_Body
 SG_ Request_Airbag_Deployment : 7|64@0+ (1,0) [0|1.84467440737096E+019] ""  ACM

BO_ 2041 DIAG_Resp_Airbag_Deploy: 8 ACM
 SG_ Response_Airbag_Deployment : 7|64@0+ (1,0) [0|1.84467440737096E+019] ""  XGW_Body

CM_ BO_ 1161 "CCU WarnMsg";
CM_ SG_ 1161 CHSKM_CCU_WarnMsg "Checksum";
CM_ SG_ 1161 ALV_CCU_WarnMsg "Alive Counter";
CM_ SG_ 1161 CCU_Malfunction "Warning Message Flag, Component owner, Supplier align and define for this signal";
CM_ SG_ 1161 CCU_Warning_Flag_2 "Warning Message Flag, Component owner, Supplier align and define for this signal";
CM_ SG_ 1161 CCU_Warning_Flag_3 "Warning Message Flag, Component owner, Supplier align and define for this signal";
CM_ SG_ 1161 CCU_Warning_Flag_4 "Warning Message Flag, Component owner, Supplier align and define for this signal";
CM_ SG_ 1161 CCU_Warning_Flag_5 "Warning Message Flag, Component owner, Supplier align and define for this signal";
CM_ SG_ 1161 CCU_Warning_Flag_6 "Warning Message Flag, Component owner, Supplier align and define for this signal";
CM_ SG_ 1161 CCU_Warning_Flag_7 "Warning Message Flag, Component owner, Supplier align and define for this signal";
CM_ SG_ 1161 CCU_Warning_Flag_8 "Warning Message Flag, Component owner, Supplier align and define for this signal";
CM_ SG_ 1161 CCU_Warning_Flag_9 "Warning Message Flag, Component owner, Supplier align and define for this signal";
CM_ SG_ 1161 CCU_Warning_Flag_10 "Warning Message Flag, Component owner, Supplier align and define for this signal";
CM_ SG_ 1161 CCU_Warning_Flag_11 "Warning Message Flag, Component owner, Supplier align and define for this signal";
CM_ SG_ 1161 CCU_Warning_Flag_12 "Warning Message Flag, Component owner, Supplier align and define for this signal";
CM_ BO_ 1166 "ETG WarnMsg";
CM_ SG_ 1166 CHSKM_ETG_WarnMsg "Checksum";
CM_ SG_ 1166 ALV_ETG_WarnMsg "Alive Counter";
CM_ SG_ 1166 ETG_Malfunction "ETG_Malfunction";
CM_ SG_ 1166 ETG_Warning_Flag_2 "Warning Message Flag, Component owner, Supplier align and define for this signal";
CM_ SG_ 1166 ETG_Warning_Flag_3 "Warning Message Flag, Component owner, Supplier align and define for this signal";
CM_ SG_ 1166 ETG_Warning_Flag_4 "Warning Message Flag, Component owner, Supplier align and define for this signal";
CM_ SG_ 1166 ETG_Warning_Flag_5 "Warning Message Flag, Component owner, Supplier align and define for this signal";
CM_ SG_ 1166 ETG_Warning_Flag_6 "Warning Message Flag, Component owner, Supplier align and define for this signal";
CM_ SG_ 1166 ETG_Warning_Flag_7 "Warning Message Flag, Component owner, Supplier align and define for this signal";
CM_ SG_ 1166 ETG_Warning_Flag_8 "Warning Message Flag, Component owner, Supplier align and define for this signal";
CM_ SG_ 1166 ETG_Warning_Flag_9 "Warning Message Flag, Component owner, Supplier align and define for this signal";
CM_ SG_ 1166 ETG_Warning_Flag_10 "Warning Message Flag, Component owner, Supplier align and define for this signal";
CM_ SG_ 1166 ETG_Warning_Flag_11 "Warning Message Flag, Component owner, Supplier align and define for this signal";
CM_ SG_ 1166 ETG_Warning_Flag_12 "Warning Message Flag, Component owner, Supplier align and define for this signal";
CM_ BO_ 1171 "BMS Warning message";
CM_ SG_ 1171 CHSKM_BMS_WarnMsg "Checksum";
CM_ SG_ 1171 ALV_BMS_WarnMsg "Alive Counter";
CM_ SG_ 1171 BMS_PackTempSts "Pack temperature warning";
CM_ SG_ 1171 BMS_ThermalRunaway "Thermal runaway warning";
CM_ SG_ 1171 BMS_BatteryReplacement "Separate signal to indicate the battery replacement information(Battery replacement MHU)";
CM_ SG_ 1171 BMS_Warning_PowerDegrade "Pack Power Degrade: Battery is cold & limited capacity, please charge";
CM_ SG_ 1171 BMS_Warning_DeltaSoC "EV Battery Delta SOC is high, range reduction in vehicle will be absorbed";
CM_ SG_ 1171 BMS_Warning_HVILSts "HVIL warning signal";
CM_ SG_ 1171 BMS_Warning_Isolation "Coolant Leakage warning";
CM_ SG_ 1171 BMS_Warning_CoolantLeakage "Coolant Leakage warning";
CM_ SG_ 1171 BMS_MalfunctionSts "Malfunction status of battery for MHU display";
CM_ SG_ 1171 BMS_LowBattery "Low Battery Warning";
CM_ SG_ 1171 BMS_Warning_DeltaTemperature "Delta temperature warning signal";
CM_ SG_ 1171 BMS_Warning_BDUTemperatureSts "BDU temperature warning signal";
CM_ SG_ 1171 BMS_Reserved_signal3 "Warning Message Flag, Component owner, Supplier align and define for this signal";
CM_ SG_ 1171 BMS_Reserved_signal4 "Warning Message Flag, Component owner, Supplier align and define for this signal";
CM_ SG_ 1171 BMS_Reserved_signal5 "Warning Message Flag, Component owner, Supplier align and define for this signal";
CM_ BO_ 1209  "BSD WarnMsg";
CM_ SG_ 1209 Checksum_0x4C3 "Checksum";
CM_ SG_ 1209 Rolling_Counter_0x4C3 "Rolling_Counter";
CM_ SG_ 1209 BSD_Warning_Flag_7 "Corner Short Range Rear Left Radar temporary not available";
CM_ SG_ 1209 BSD_Warning_Flag_8 "Corner Short Range Rear Left Radar permanently not available";
CM_ SG_ 1209 BSD_Warning_Flag_9 "Corner Short Range Rear Right Radar temporary not available";
CM_ SG_ 1209 BSD_Warning_Flag_10 "Corner Short Range Rear Right Radar permanently not available";
CM_ SG_ 1209 BSD_Warning_Flag_14 "I-ECU has BSD function fault : speed /gear loss";
CM_ SG_ 1209 BSD_Warning_Flag_21 "LeftCornerRadaar Install Faulty";
CM_ SG_ 1209 BSD_Warning_Flag_22 "RightCornerRadaar Install Faulty";
CM_ SG_ 1209 BSD_Warning_Flag_23 "LeftCornerRadaar Calib Faulty";
CM_ SG_ 1209 BSD_Warning_Flag_24 "RightCornerRadaar Calib Faulty";
CM_ BO_ 1211 "TRM WarnMsg";
CM_ SG_ 1211 CHSKM_TRM_WarnMsg "Checksum";
CM_ SG_ 1211 ALV_TRM_WarnMsg "Alive Counter";
CM_ SG_ 1211 TRM_LightMalfnc "Trailer light malffunction";
CM_ SG_ 1211 TRM_TurnLeftMafnc "Trailer turn indicator left malfunction";
CM_ SG_ 1211 TRM_TurnRightMafnc "Trailer turn indicator right malfunction";
CM_ SG_ 1211 TRM_TrailerMalfnc "Trailer system malfunction";
CM_ SG_ 1211 TRM_Warning_Flag_5 "Warning Message Flag, Component owner, Supplier align and define for this signal";
CM_ SG_ 1211 TRM_Warning_Flag_6 "Warning Message Flag, Component owner, Supplier align and define for this signal";
CM_ SG_ 1211 TRM_Warning_Flag_7 "Warning Message Flag, Component owner, Supplier align and define for this signal";
CM_ SG_ 1211 TRM_Warning_Flag_8 "Warning Message Flag, Component owner, Supplier align and define for this signal";
CM_ SG_ 1211 TRM_Warning_Flag_9 "Warning Message Flag, Component owner, Supplier align and define for this signal";
CM_ SG_ 1211 TRM_Warning_Flag_10 "Warning Message Flag, Component owner, Supplier align and define for this signal";
CM_ SG_ 1211 TRM_Warning_Flag_11 "Warning Message Flag, Component owner, Supplier align and define for this signal";
CM_ SG_ 1211 TRM_Warning_Flag_12 "Warning Message Flag, Component owner, Supplier align and define for this signal";
CM_ BO_ 1216 "Door State";
CM_ SG_ 1216 SECCAN_BCM_STAT_Door "Secret portion from Secure CAN algorithm";
CM_ SG_ 1216 BCM_STAT_DoorHandleRR "Handle Door Rear Right Pull Event";
CM_ SG_ 1216 BCM_STAT_DoorHandleRL "Handle Door Rear Left Pull Event";
CM_ SG_ 1216 BCM_STAT_DoorHandleFR "Handle Door Front Right Pull Event";
CM_ SG_ 1216 BCM_STAT_DoorHandleFL "Handle Door Front Left Pull Event";
CM_ BO_ 1217 "APM WarnMsg";
CM_ SG_ 1217 CHSKM_APM_WarnMsg "Checksum";
CM_ SG_ 1217 ALV_APM_WarnMsg "Alive Counter";
CM_ SG_ 1217 APM_Malfunction "Anti-pinch module malfunction";
CM_ SG_ 1217 ChildWindowLockStS "Child window lock status";
CM_ SG_ 1217 APM_Warning_Flag_3 "Warning Message Flag, Component owner, Supplier align and define for this signal";
CM_ SG_ 1217 APM_Warning_Flag_4 "Warning Message Flag, Component owner, Supplier align and define for this signal";
CM_ SG_ 1217 APM_Warning_Flag_5 "Warning Message Flag, Component owner, Supplier align and define for this signal";
CM_ SG_ 1217 APM_Warning_Flag_6 "Warning Message Flag, Component owner, Supplier align and define for this signal";
CM_ SG_ 1217 APM_Warning_Flag_7 "Warning Message Flag, Component owner, Supplier align and define for this signal";
CM_ SG_ 1217 APM_Warning_Flag_8 "Warning Message Flag, Component owner, Supplier align and define for this signal";
CM_ SG_ 1217 APM_Warning_Flag_9 "Warning Message Flag, Component owner, Supplier align and define for this signal";
CM_ SG_ 1217 APM_Warning_Flag_10 "Warning Message Flag, Component owner, Supplier align and define for this signal";
CM_ SG_ 1217 APM_Warning_Flag_11 "Warning Message Flag, Component owner, Supplier align and define for this signal";
CM_ SG_ 1217 APM_Warning_Flag_12 "Warning Message Flag, Component owner, Supplier align and define for this signal";
CM_ BO_ 1281 "BCM Network management";
CM_ SG_ 1281 BCM_srcNodeID "Network Management Signal";
CM_ SG_ 1281 BCM_CtrlBitVector "Network Management Signal";
CM_ SG_ 1281 BCM_usrData0 "Network Management Signal";
CM_ SG_ 1281 BCM_usrData1 "Network Management Signal";
CM_ SG_ 1281 BCM_usrData2 "Network Management Signal";
CM_ SG_ 1281 BCM_usrData3 "Network Management Signal";
CM_ SG_ 1281 BCM_usrData4 "Network Management Signal";
CM_ SG_ 1281 BCM_usrData5 "Network Management Signal";
CM_ BO_ 1282 "XGW Network Management";
CM_ SG_ 1282 XGW_srcNodeID "Network Management Signal";
CM_ SG_ 1282 XGW_CtrlBitVector "Network Management Signal";
CM_ SG_ 1282 XGW_usrData0 "Network Management Signal";
CM_ SG_ 1282 XGW_usrData1 "Network Management Signal";
CM_ SG_ 1282 XGW_usrData2 "Network Management Signal";
CM_ SG_ 1282 XGW_usrData3 "Network Management Signal";
CM_ SG_ 1282 XGW_usrData4 "Network Management Signal";
CM_ SG_ 1282 XGW_usrData5 "Network Management Signal";
CM_ BO_ 1289 "CCUF Network management";
CM_ SG_ 1289 CCUF_srcNodeID "Network Management Signal";
CM_ SG_ 1289 CCUF_CtrlBitVector "Network Management Signal";
CM_ SG_ 1289 CCUF_usrData0 "Network Management Signal";
CM_ SG_ 1289 CCUF_usrData1 "Network Management Signal";
CM_ SG_ 1289 CCUF_usrData2 "Network Management Signal";
CM_ SG_ 1289 CCUF_usrData3 "Network Management Signal";
CM_ SG_ 1289 CCUF_usrData4 "Network Management Signal";
CM_ SG_ 1289 CCUF_usrData5 "Network Management Signal";
CM_ BO_ 1294 "ETG Network management";
CM_ SG_ 1294 ETG_srcNodeID "Network Management Signal";
CM_ SG_ 1294 ETG_CtrlBitVector "Network Management Signal";
CM_ SG_ 1294 ETG_usrData0 "Network Management Signal";
CM_ SG_ 1294 ETG_usrData1 "Network Management Signal";
CM_ SG_ 1294 ETG_usrData2 "Network Management Signal";
CM_ SG_ 1294 ETG_usrData3 "Network Management Signal";
CM_ SG_ 1294 ETG_usrData4 "Network Management Signal";
CM_ SG_ 1294 ETG_usrData5 "Network Management Signal";
CM_ BO_ 1310 "PSM D Network management";
CM_ SG_ 1310 PSM_D_srcNodeID "Network Management Signal";
CM_ SG_ 1310 PSM_D_CtrlBitVector "Network Management Signal";
CM_ SG_ 1310 PSM_D_usrData0 "Network Management Signal";
CM_ SG_ 1310 PSM_D_usrData1 "Network Management Signal";
CM_ SG_ 1310 PSM_D_usrData2 "Network Management Signal";
CM_ SG_ 1310 PSM_D_usrData3 "Network Management Signal";
CM_ SG_ 1310 PSM_D_usrData4 "Network Management Signal";
CM_ SG_ 1310 PSM_D_usrData5 "Network Management Signal";
CM_ BO_ 1339 "TRM Network management";
CM_ SG_ 1339 TRM_srcNodeID "Network Management Signal";
CM_ SG_ 1339 TRM_CtrlBitVector "Network Management Signal";
CM_ SG_ 1339 TRM_usrData0 "Network Management Signal";
CM_ SG_ 1339 TRM_usrData1 "Network Management Signal";
CM_ SG_ 1339 TRM_usrData2 "Network Management Signal";
CM_ SG_ 1339 TRM_usrData3 "Network Management Signal";
CM_ SG_ 1339 TRM_usrData4 "Network Management Signal";
CM_ SG_ 1339 TRM_usrData5 "Network Management Signal";
CM_ BO_ 1337 "SRR_RR_M Network Management";
CM_ SG_ 1337 SRR_RR_M_srcNodeID "Network Management Signal";
CM_ SG_ 1337 SRR_RR_M_CtrlBitVector "Network Management Signal";
CM_ SG_ 1337 SRR_RR_M_usrData0 "Network Management Signal";
CM_ SG_ 1337 SRR_RR_M_usrData1 "Network Management Signal";
CM_ SG_ 1337 SRR_RR_M_usrData2 "Network Management Signal";
CM_ SG_ 1337 SRR_RR_M_usrData3 "Network Management Signal";
CM_ SG_ 1337 SRR_RR_M_usrData4 "Network Management Signal";
CM_ SG_ 1337 SRR_RR_M_usrData5 "Network Management Signal";
CM_ BO_ 1345 "APM Network management";
CM_ SG_ 1345 APM_srcNodeID "Network Management Signal";
CM_ SG_ 1345 APM_CtrlBitVector "Network Management Signal";
CM_ SG_ 1345 APM_usrData0 "Network Management Signal";
CM_ SG_ 1345 APM_usrData1 "Network Management Signal";
CM_ SG_ 1345 APM_usrData2 "Network Management Signal";
CM_ SG_ 1345 APM_usrData3 "Network Management Signal";
CM_ SG_ 1345 APM_usrData4 "Network Management Signal";
CM_ SG_ 1345 APM_usrData5 "Network Management Signal";
CM_ BO_ 1353 "LDM_L Network management";
CM_ SG_ 1353 LDM_L_srcNodeID "Network Management Signal";
CM_ SG_ 1353 LDM_L_CtrlBitVector "Network Management Signal";
CM_ SG_ 1353 LDM_L_usrData0 "Network Management Signal";
CM_ SG_ 1353 LDM_L_usrData1 "Network Management Signal";
CM_ SG_ 1353 LDM_L_usrData2 "Network Management Signal";
CM_ SG_ 1353 LDM_L_usrData3 "Network Management Signal";
CM_ SG_ 1353 LDM_L_usrData4 "Network Management Signal";
CM_ SG_ 1353 LDM_L_usrData5 "Network Management Signal";
CM_ BO_ 1354 "LDM_R Network management";
CM_ SG_ 1354 LDM_R_srcNodeID "Network Management Signal";
CM_ SG_ 1354 LDM_R_CtrlBitVector "Network Management Signal";
CM_ SG_ 1354 LDM_R_usrData0 "Network Management Signal";
CM_ SG_ 1354 LDM_R_usrData1 "Network Management Signal";
CM_ SG_ 1354 LDM_R_usrData2 "Network Management Signal";
CM_ SG_ 1354 LDM_R_usrData3 "Network Management Signal";
CM_ SG_ 1354 LDM_R_usrData4 "Network Management Signal";
CM_ SG_ 1354 LDM_R_usrData5 "Network Management Signal";
CM_ BO_ 1360 "CCUR Network management";
CM_ SG_ 1360 CCUR_srcNodeID "Network Management Signal";
CM_ SG_ 1360 CCUR_CtrlBitVector "Network Management Signal";
CM_ SG_ 1360 CCUR_usrData0 "Network Management Signal";
CM_ SG_ 1360 CCUR_usrData1 "Network Management Signal";
CM_ SG_ 1360 CCUR_usrData2 "Network Management Signal";
CM_ SG_ 1360 CCUR_usrData3 "Network Management Signal";
CM_ SG_ 1360 CCUR_usrData4 "Network Management Signal";
CM_ SG_ 1360 CCUR_usrData5 "Network Management Signal";
CM_ BO_ 1537 "BCM DiagResp";
CM_ SG_ 1537 BCM_DiagRespData0 "Diagnostic signal Data response";
CM_ SG_ 1537 BCM_DiagRespData1 "Remote Diagnostic signal Data response";
CM_ SG_ 1537 BCM_DiagRespData2 "Diagnostic signal Data response";
CM_ SG_ 1537 BCM_DiagRespData3 "Diagnostic signal Data response";
CM_ SG_ 1537 BCM_DiagRespData4 "Diagnostic signal Data response";
CM_ SG_ 1537 BCM_DiagRespData5 "Diagnostic signal Data response";
CM_ SG_ 1537 BCM_DiagRespData6 "Remote Diagnostic signal Data response";
CM_ SG_ 1537 BCM_DiagRespData7 "Diagnostic signal Data response";
CM_ BO_ 1544 "ACM DiagResp";
CM_ SG_ 1544 ACM_DiagRespData0 "Diagnostic signal Data response";
CM_ SG_ 1544 ACM_DiagRespData1 "Remote Diagnostic signal Data response";
CM_ SG_ 1544 ACM_DiagRespData2 "Diagnostic signal Data response";
CM_ SG_ 1544 ACM_DiagRespData3 "Remote Diagnostic signal Data response";
CM_ SG_ 1544 ACM_DiagRespData4 "Diagnostic signal Data response";
CM_ SG_ 1544 ACM_DiagRespData5 "Remote Diagnostic signal Data response";
CM_ SG_ 1544 ACM_DiagRespData6 "Diagnostic signal Data response";
CM_ SG_ 1544 ACM_DiagRespData7 "Remote Diagnostic signal Data response";
CM_ BO_ 1545 "CCU DiagResp";
CM_ SG_ 1545 CCUF_DiagRespData0 "Diagnostic signal Data response";
CM_ SG_ 1545 CCUF_DiagRespData1 "Remote Diagnostic signal Data response";
CM_ SG_ 1545 CCUF_DiagRespData2 "Remote Diagnostic signal Data response";
CM_ SG_ 1545 CCUF_DiagRespData3 "Diagnostic signal Data response";
CM_ SG_ 1545 CCUF_DiagRespData4 "Diagnostic signal Data response";
CM_ SG_ 1545 CCUF_DiagRespData5 "Remote Diagnostic signal Data response";
CM_ SG_ 1545 CCUF_DiagRespData6 "Remote Diagnostic signal Data response";
CM_ SG_ 1545 CCUF_DiagRespData7 "Diagnostic signal Data response";
CM_ BO_ 1550 "ETG DiagResp";
CM_ SG_ 1550 ETG_DiagRespData0 "Diagnostic signal Data response";
CM_ SG_ 1550 ETG_DiagRespData1 "Diagnostic signal Data response";
CM_ SG_ 1550 ETG_DiagRespData2 "Diagnostic signal Data response";
CM_ SG_ 1550 ETG_DiagRespData3 "Remote Diagnostic signal Data response";
CM_ SG_ 1550 ETG_DiagRespData4 "Diagnostic signal Data response";
CM_ SG_ 1550 ETG_DiagRespData5 "Diagnostic signal Data response";
CM_ SG_ 1550 ETG_DiagRespData6 "Diagnostic signal Data response";
CM_ SG_ 1550 ETG_DiagRespData7 "Diagnostic signal Data response";
CM_ BO_ 1553 "ASU gateway Diagnostic response";
CM_ SG_ 1553 ASU_Gateway_DiagRespData0 "Diagnostic signal Data response";
CM_ SG_ 1553 ASU_Gateway_DiagRespData1 "Diagnostic signal Data response";
CM_ SG_ 1553 ASU_Gateway_DiagRespData2 "Diagnostic signal Data response";
CM_ SG_ 1553 ASU_Gateway_DiagRespData3 "Diagnostic signal Data response";
CM_ SG_ 1553 ASU_Gateway_DiagRespData4 "Diagnostic signal Data response";
CM_ SG_ 1553 ASU_Gateway_DiagRespData5 "Diagnostic signal Data response";
CM_ SG_ 1553 ASU_Gateway_DiagRespData6 "Diagnostic signal Data response";
CM_ SG_ 1553 ASU_Gateway_DiagRespData7 "Diagnostic signal Data response";
CM_ BO_ 1556 "CCUR Diagnostic Response";
CM_ SG_ 1556 CCUR_DiagRespData0 "Diagnostic signal Data response";
CM_ SG_ 1556 CCUR_DiagRespData1 "Diagnostic signal Data response";
CM_ SG_ 1556 CCUR_DiagRespData2 "Diagnostic signal Data response";
CM_ SG_ 1556 CCUR_DiagRespData3 "Diagnostic signal Data response";
CM_ SG_ 1556 CCUR_DiagRespData4 "Remote Diagnostic signal Data response";
CM_ SG_ 1556 CCUR_DiagRespData5 "Diagnostic signal Data response";
CM_ SG_ 1556 CCUR_DiagRespData6 "Remote Diagnostic signal Data response";
CM_ SG_ 1556 CCUR_DiagRespData7 "Diagnostic signal Data response";
CM_ BO_ 1566 "PSM D DiagResp";
CM_ SG_ 1566 PSM_D_DiagRespData0 "Diagnostic signal Data response";
CM_ SG_ 1566 PSM_D_DiagRespData1 "Diagnostic signal Data response";
CM_ SG_ 1566 PSM_D_DiagRespData2 "Diagnostic signal Data response";
CM_ SG_ 1566 PSM_D_DiagRespData3 "Remote Diagnostic signal Data response";
CM_ SG_ 1566 PSM_D_DiagRespData4 "Diagnostic signal Data response";
CM_ SG_ 1566 PSM_D_DiagRespData5 "Diagnostic signal Data response";
CM_ SG_ 1566 PSM_D_DiagRespData6 "Diagnostic signal Data response";
CM_ SG_ 1566 PSM_D_DiagRespData7 "Diagnostic signal Data response";
CM_ BO_ 1585 "USS Rear Diagnostic Response";
CM_ SG_ 1585 USS_R_DiagRespData0 "Diagnostic signal Data response";
CM_ SG_ 1585 USS_R_DiagRespData1 "Diagnostic signal Data response";
CM_ SG_ 1585 USS_R_DiagRespData2 "Diagnostic signal Data response";
CM_ SG_ 1585 USS_R_DiagRespData3 "Diagnostic signal Data response";
CM_ SG_ 1585 USS_R_DiagRespData4 "Diagnostic signal Data response";
CM_ SG_ 1585 USS_R_DiagRespData5 "Diagnostic signal Data response";
CM_ SG_ 1585 USS_R_DiagRespData6 "Diagnostic signal Data response";
CM_ SG_ 1585 USS_R_DiagRespData7 "Diagnostic signal Data response";
CM_ BO_ 1586 "USS Front Diagnostic Response";
CM_ SG_ 1586 USS_F_DiagRespData0 "Diagnostic signal Data response";
CM_ SG_ 1586 USS_F_DiagRespData1 "Diagnostic signal Data response";
CM_ SG_ 1586 USS_F_DiagRespData2 "Diagnostic signal Data response";
CM_ SG_ 1586 USS_F_DiagRespData3 "Diagnostic signal Data response";
CM_ SG_ 1586 USS_F_DiagRespData4 "Diagnostic signal Data response";
CM_ SG_ 1586 USS_F_DiagRespData5 "Diagnostic signal Data response";
CM_ SG_ 1586 USS_F_DiagRespData6 "Diagnostic signal Data response";
CM_ SG_ 1586 USS_F_DiagRespData7 "Diagnostic signal Data response";
CM_ BO_ 1592 "ASU Diagnostic Response";
CM_ SG_ 1592 ASU_DiagRespData0 "Diagnostic signal Data response";
CM_ SG_ 1592 ASU_DiagRespData1 "Diagnostic signal Data response";
CM_ SG_ 1592 ASU_DiagRespData2 "Diagnostic signal Data response";
CM_ SG_ 1592 ASU_DiagRespData3 "Diagnostic signal Data response";
CM_ SG_ 1592 ASU_DiagRespData4 "Diagnostic signal Data response";
CM_ SG_ 1592 ASU_DiagRespData5 "Diagnostic signal Data response";
CM_ SG_ 1592 ASU_DiagRespData6 "Diagnostic signal Data response";
CM_ SG_ 1592 ASU_DiagRespData7 "Diagnostic signal Data response";
CM_ BO_ 1593 "SRR_RR_M Diagnostic Response";
CM_ SG_ 1593 SRR_RR_M_DiagResp_Data0 "Diagnostic signal Data response";
CM_ SG_ 1593 SRR_RR_M_DiagResp_Data1 "Diagnostic signal Data response";
CM_ SG_ 1593 SRR_RR_M_DiagResp_Data2 "Diagnostic signal Data response";
CM_ SG_ 1593 SRR_RR_M_DiagResp_Data3 "Diagnostic signal Data response";
CM_ SG_ 1593 SRR_RR_M_DiagResp_Data4 "Diagnostic signal Data response";
CM_ SG_ 1593 SRR_RR_M_DiagResp_Data5 "Diagnostic signal Data response";
CM_ SG_ 1593 SRR_RR_M_DiagResp_Data6 "Diagnostic signal Data response";
CM_ SG_ 1593 SRR_RR_M_DiagResp_Data7 "Diagnostic signal Data response";
CM_ BO_ 1595 "TRM DiagResp";
CM_ SG_ 1595 TRM_DiagRespData0 "Diagnostic signal Data response";
CM_ SG_ 1595 TRM_DiagRespData1 "Diagnostic signal Data response";
CM_ SG_ 1595 TRM_DiagRespData2 "Diagnostic signal Data response";
CM_ SG_ 1595 TRM_DiagRespData3 "Remote Diagnostic signal Data response";
CM_ SG_ 1595 TRM_DiagRespData4 "Remote Diagnostic signal Data response";
CM_ SG_ 1595 TRM_DiagRespData5 "Remote Diagnostic signal Data response";
CM_ SG_ 1595 TRM_DiagRespData6 "Diagnostic signal Data response";
CM_ SG_ 1595 TRM_DiagRespData7 "Remote Diagnostic signal Data response";
CM_ BO_ 1601 "APM DiagResp";
CM_ SG_ 1601 APM_DiagRespData0 "Diagnostic signal Data response";
CM_ SG_ 1601 APM_DiagRespData1 "Diagnostic signal Data response";
CM_ SG_ 1601 APM_DiagRespData2 "Diagnostic signal Data response";
CM_ SG_ 1601 APM_DiagRespData3 "Diagnostic signal Data response";
CM_ SG_ 1601 APM_DiagRespData4 "Remote Diagnostic signal Data response";
CM_ SG_ 1601 APM_DiagRespData5 "Diagnostic signal Data response";
CM_ SG_ 1601 APM_DiagRespData6 "Remote Diagnostic signal Data response";
CM_ SG_ 1601 APM_DiagRespData7 "Diagnostic signal Data response";
CM_ BO_ 1602 "SHVU F DiagResp";
CM_ SG_ 1602 SHVU_F_DiagRespData0 "Diagnostic signal Data response";
CM_ SG_ 1602 SHVU_F_DiagRespData1 "Diagnostic signal Data response";
CM_ SG_ 1602 SHVU_F_DiagRespData2 "Remote Diagnostic signal Data response";
CM_ SG_ 1602 SHVU_F_DiagRespData3 "Diagnostic signal Data response";
CM_ SG_ 1602 SHVU_F_DiagRespData4 "Diagnostic signal Data response";
CM_ SG_ 1602 SHVU_F_DiagRespData5 "Diagnostic signal Data response";
CM_ SG_ 1602 SHVU_F_DiagRespData6 "Remote Diagnostic signal Data response";
CM_ SG_ 1602 SHVU_F_DiagRespData7 "Diagnostic signal Data response";
CM_ BO_ 1603 "SHVU R DiagResp";
CM_ SG_ 1603 SHVU_R_DiagRespData0 "Diagnostic signal Data response";
CM_ SG_ 1603 SHVU_R_DiagRespData1 "Remote Diagnostic signal Data response";
CM_ SG_ 1603 SHVU_R_DiagRespData2 "Diagnostic signal Data response";
CM_ SG_ 1603 SHVU_R_DiagRespData3 "Remote Diagnostic signal Data response";
CM_ SG_ 1603 SHVU_R_DiagRespData4 "Remote Diagnostic signal Data response";
CM_ SG_ 1603 SHVU_R_DiagRespData5 "Diagnostic signal Data response";
CM_ SG_ 1603 SHVU_R_DiagRespData6 "Remote Diagnostic signal Data response";
CM_ SG_ 1603 SHVU_R_DiagRespData7 "Diagnostic signal Data response";
CM_ BO_ 1604 "OCS_P_DiagResp";
CM_ SG_ 1604 OCS_P_DiagRespData0 "Diagnostic signal Data response";
CM_ SG_ 1604 OCS_P_DiagRespData1 "Remote Diagnostic signal Data response";
CM_ SG_ 1604 OCS_P_DiagRespData2 "Diagnostic signal Data response";
CM_ SG_ 1604 OCS_P_DiagRespData3 "Remote Diagnostic signal Data response";
CM_ SG_ 1604 OCS_P_DiagRespData4 "Diagnostic signal Data response";
CM_ SG_ 1604 OCS_P_DiagRespData5 "Diagnostic signal Data response";
CM_ SG_ 1604 OCS_P_DiagRespData6 "Diagnostic signal Data response";
CM_ SG_ 1604 OCS_P_DiagRespData7 "Diagnostic signal Data response";
CM_ BO_ 1609 "LDM_L DiagResp";
CM_ SG_ 1609 LDM_L_DiagRespData0 "Remote Diagnostic signal Data response
";
CM_ SG_ 1609 LDM_L_DiagRespData1 "Diagnostic signal Data response";
CM_ SG_ 1609 LDM_L_DiagRespData2 "Remote Diagnostic signal Data response
";
CM_ SG_ 1609 LDM_L_DiagRespData3 "Diagnostic signal Data response";
CM_ SG_ 1609 LDM_L_DiagRespData4 "Diagnostic signal Data response";
CM_ SG_ 1609 LDM_L_DiagRespData5 "Remote Diagnostic signal Data response
";
CM_ SG_ 1609 LDM_L_DiagRespData6 "Diagnostic signal Data response";
CM_ SG_ 1609 LDM_L_DiagRespData7 "Remote Diagnostic signal Data response
";
CM_ BO_ 1610 "LDM_R DiagResp";
CM_ SG_ 1610 LDM_R_DiagRespData0 "Diagnostic signal Data response";
CM_ SG_ 1610 LDM_R_DiagRespData1 "Remote Diagnostic signal Data response
";
CM_ SG_ 1610 LDM_R_DiagRespData2 "Diagnostic signal Data response";
CM_ SG_ 1610 LDM_R_DiagRespData3 "Diagnostic signal Data response";
CM_ SG_ 1610 LDM_R_DiagRespData4 "Remote Diagnostic signal Data response
";
CM_ SG_ 1610 LDM_R_DiagRespData5 "Diagnostic signal Data response";
CM_ SG_ 1610 LDM_R_DiagRespData6 "Diagnostic signal Data response";
CM_ SG_ 1610 LDM_R_DiagRespData7 "Remote Diagnostic signal Data response
";
CM_ BO_ 1624 "BAS DiagResp";
CM_ SG_ 1624 BAS_DiagRespData0 "Diagnostic signal Data response";
CM_ SG_ 1624 BAS_DiagRespData1 "Diagnostic signal Data response";
CM_ SG_ 1624 BAS_DiagRespData2 "Diagnostic signal Data response";
CM_ SG_ 1624 BAS_DiagRespData3 "Diagnostic signal Data response";
CM_ SG_ 1624 BAS_DiagRespData4 "Diagnostic signal Data response";
CM_ SG_ 1624 BAS_DiagRespData5 "Diagnostic signal Data response";
CM_ SG_ 1624 BAS_DiagRespData6 "Diagnostic signal Data response";
CM_ SG_ 1624 BAS_DiagRespData7 "Diagnostic signal Data response";
CM_ BO_ 1636 "DCM_APM_DiagResp";
CM_ SG_ 1636 DCM_APM_DiagRespData0 "Remote Diagnostic signal Data response
";
CM_ SG_ 1636 DCM_APM_DiagRespData1 "Remote Diagnostic signal Data response
";
CM_ SG_ 1636 DCM_APM_DiagRespData2 "Diagnostic signal Data response";
CM_ SG_ 1636 DCM_APM_DiagRespData3 "Remote Diagnostic signal Data response
";
CM_ SG_ 1636 DCM_APM_DiagRespData4 "Diagnostic signal Data response";
CM_ SG_ 1636 DCM_APM_DiagRespData5 "Remote Diagnostic signal Data response
";
CM_ SG_ 1636 DCM_APM_DiagRespData6 "Remote Diagnostic signal Data response
";
CM_ SG_ 1636 DCM_APM_DiagRespData7 "Diagnostic signal Data response";
CM_ BO_ 1659 "BCM_BPM Diagnostic Response";
CM_ SG_ 1659 BCM_BPM_DiagRespData0 "Diagnostic signal Data response";
CM_ SG_ 1659 BCM_BPM_DiagRespData1 "Diagnostic signal Data response";
CM_ SG_ 1659 BCM_BPM_DiagRespData2 "Diagnostic signal Data response";
CM_ SG_ 1659 BCM_BPM_DiagRespData3 "Diagnostic signal Data response";
CM_ SG_ 1659 BCM_BPM_DiagRespData4 "Diagnostic signal Data response";
CM_ SG_ 1659 BCM_BPM_DiagRespData5 "Diagnostic signal Data response";
CM_ SG_ 1659 BCM_BPM_DiagRespData6 "Diagnostic signal Data response";
CM_ SG_ 1659 BCM_BPM_DiagRespData7 "Diagnostic signal Data response";
CM_ BO_ 1665 "BCM DiagReq";
CM_ SG_ 1665 BCM_DiagReqData0 "Diagnostic signal Data request";
CM_ SG_ 1665 BCM_DiagReqData1 "Diagnostic signal Data request";
CM_ SG_ 1665 BCM_DiagReqData2 "Diagnostic signal Data request";
CM_ SG_ 1665 BCM_DiagReqData3 "Diagnostic signal Data request";
CM_ SG_ 1665 BCM_DiagReqData4 "Diagnostic signal Data request";
CM_ SG_ 1665 BCM_DiagReqData5 "Diagnostic signal Data request";
CM_ SG_ 1665 BCM_DiagReqData6 "Remote Diagnostic signal Data request";
CM_ SG_ 1665 BCM_DiagReqData7 "Remote Diagnostic signal Data request";
CM_ BO_ 1672 "ACM DiagReq";
CM_ SG_ 1672 ACM_DiagReqData0 "Diagnostic signal Data request";
CM_ SG_ 1672 ACM_DiagReqData1 "Diagnostic signal Data request";
CM_ SG_ 1672 ACM_DiagReqData2 "Diagnostic signal Data request";
CM_ SG_ 1672 ACM_DiagReqData3 "Remote Diagnostic signal Data request";
CM_ SG_ 1672 ACM_DiagReqData4 "Diagnostic signal Data request";
CM_ SG_ 1672 ACM_DiagReqData5 "Diagnostic signal Data request";
CM_ SG_ 1672 ACM_DiagReqData6 "Remote Diagnostic signal Data request";
CM_ SG_ 1672 ACM_DiagReqData7 "Diagnostic signal Data request";
CM_ BO_ 1673 "CCU DiagReq";
CM_ SG_ 1673 CCUF_DiagReqData0 "Remote Diagnostic signal Data request";
CM_ SG_ 1673 CCUF_DiagReqData1 "Diagnostic signal Data request";
CM_ SG_ 1673 CCUF_DiagReqData2 "Diagnostic signal Data request";
CM_ SG_ 1673 CCUF_DiagReqData3 "Diagnostic signal Data request";
CM_ SG_ 1673 CCUF_DiagReqData4 "Diagnostic signal Data request";
CM_ SG_ 1673 CCUF_DiagReqData5 "Diagnostic signal Data request";
CM_ SG_ 1673 CCUF_DiagReqData6 "Diagnostic signal Data request";
CM_ SG_ 1673 CCUF_DiagReqData7 "Diagnostic signal Data request";
CM_ BO_ 1678 "ETG DiagReq";
CM_ SG_ 1678 ETG_DiagReqData0 "Diagnostic signal Data request";
CM_ SG_ 1678 ETG_DiagReqData1 "Diagnostic signal Data request";
CM_ SG_ 1678 ETG_DiagReqData2 "Diagnostic signal Data request";
CM_ SG_ 1678 ETG_DiagReqData3 "Diagnostic signal Data request";
CM_ SG_ 1678 ETG_DiagReqData4 "Diagnostic signal Data request";
CM_ SG_ 1678 ETG_DiagReqData5 "Diagnostic signal Data request";
CM_ SG_ 1678 ETG_DiagReqData6 "Diagnostic signal Data request";
CM_ SG_ 1678 ETG_DiagReqData7 "Remote Diagnostic signal Data request";
CM_ BO_ 1681 "ASU gateway Diagnostic Request";
CM_ SG_ 1681 ASU_Gateway_DiagReqData0 "Diagnostic signal Data request";
CM_ SG_ 1681 ASU_Gateway_DiagReqData1 "Diagnostic signal Data request";
CM_ SG_ 1681 ASU_Gateway_DiagReqData2 "Diagnostic signal Data request";
CM_ SG_ 1681 ASU_Gateway_DiagReqData3 "Diagnostic signal Data request";
CM_ SG_ 1681 ASU_Gateway_DiagReqData4 "Diagnostic signal Data request";
CM_ SG_ 1681 ASU_Gateway_DiagReqData5 "Diagnostic signal Data request";
CM_ SG_ 1681 ASU_Gateway_DiagReqData6 "Diagnostic signal Data request";
CM_ SG_ 1681 ASU_Gateway_DiagReqData7 "Diagnostic signal Data request";
CM_ BO_ 1684 "CCUR Diagnostic Request";
CM_ SG_ 1684 CCUR_DiagReqData0 "Diagnostic signal Data request";
CM_ SG_ 1684 CCUR_DiagReqData1 "Diagnostic signal Data request";
CM_ SG_ 1684 CCUR_DiagReqData2 "Diagnostic signal Data request";
CM_ SG_ 1684 CCUR_DiagReqData3 "Remote Diagnostic signal Data request";
CM_ SG_ 1684 CCUR_DiagReqData4 "Remote Diagnostic signal Data request";
CM_ SG_ 1684 CCUR_DiagReqData5 "Diagnostic signal Data request";
CM_ SG_ 1684 CCUR_DiagReqData6 "Diagnostic signal Data request";
CM_ SG_ 1684 CCUR_DiagReqData7 "Diagnostic signal Data request";
CM_ BO_ 1694 "PSM D DiagReq";
CM_ SG_ 1694 PSM_D_DiagReqData0 "Remote Diagnostic signal Data request";
CM_ SG_ 1694 PSM_D_DiagReqData1 "Diagnostic signal Data request";
CM_ SG_ 1694 PSM_D_DiagReqData2 "Remote Diagnostic signal Data request";
CM_ SG_ 1694 PSM_D_DiagReqData3 "Diagnostic signal Data request";
CM_ SG_ 1694 PSM_D_DiagReqData4 "Diagnostic signal Data request";
CM_ SG_ 1694 PSM_D_DiagReqData5 "Remote Diagnostic signal Data request";
CM_ SG_ 1694 PSM_D_DiagReqData6 "Remote Diagnostic signal Data request";
CM_ SG_ 1694 PSM_D_DiagReqData7 "Diagnostic signal Data request";
CM_ BO_ 1713 "USS Rear Diagnostic Request";
CM_ SG_ 1713 USS_R_DiagReqData0 "Diagnostic signal Data request";
CM_ SG_ 1713 USS_R_DiagReqData1 "Diagnostic signal Data request";
CM_ SG_ 1713 USS_R_DiagReqData2 "Diagnostic signal Data request";
CM_ SG_ 1713 USS_R_DiagReqData3 "Diagnostic signal Data request";
CM_ SG_ 1713 USS_R_DiagReqData4 "Diagnostic signal Data request";
CM_ SG_ 1713 USS_R_DiagReqData5 "Diagnostic signal Data request";
CM_ SG_ 1713 USS_R_DiagReqData6 "Diagnostic signal Data request";
CM_ SG_ 1713 USS_R_DiagReqData7 "Diagnostic signal Data request";
CM_ BO_ 1714 "USS Front Diagnostic Request";
CM_ SG_ 1714 USS_F_DiagReqData0 "Diagnostic signal Data request";
CM_ SG_ 1714 USS_F_DiagReqData1 "Diagnostic signal Data request";
CM_ SG_ 1714 USS_F_DiagReqData2 "Diagnostic signal Data request";
CM_ SG_ 1714 USS_F_DiagReqData3 "Diagnostic signal Data request";
CM_ SG_ 1714 USS_F_DiagReqData4 "Diagnostic signal Data request";
CM_ SG_ 1714 USS_F_DiagReqData5 "Diagnostic signal Data request";
CM_ SG_ 1714 USS_F_DiagReqData6 "Diagnostic signal Data request";
CM_ SG_ 1714 USS_F_DiagReqData7 "Diagnostic signal Data request";
CM_ BO_ 1721 "SRR_RR_M Diagnostic Request";
CM_ SG_ 1721 SRR_RR_M_DiagReq_Data0 "Diagnostic signal Data request";
CM_ SG_ 1721 SRR_RR_M_DiagReq_Data1 "Diagnostic signal Data request";
CM_ SG_ 1721 SRR_RR_M_DiagReq_Data2 "Diagnostic signal Data request";
CM_ SG_ 1721 SRR_RR_M_DiagReq_Data3 "Diagnostic signal Data request";
CM_ SG_ 1721 SRR_RR_M_DiagReq_Data4 "Diagnostic signal Data request";
CM_ SG_ 1721 SRR_RR_M_DiagReq_Data5 "Diagnostic signal Data request";
CM_ SG_ 1721 SRR_RR_M_DiagReq_Data6 "Diagnostic signal Data request";
CM_ SG_ 1721 SRR_RR_M_DiagReq_Data7 "Diagnostic signal Data request";
CM_ BO_ 1723 "TRM DiagReq";
CM_ SG_ 1723 TRM_DiagReqData0 "Diagnostic signal Data request";
CM_ SG_ 1723 TRM_DiagReqData1 "Diagnostic signal Data request";
CM_ SG_ 1723 TRM_DiagReqData2 "Remote Diagnostic signal Data request";
CM_ SG_ 1723 TRM_DiagReqData3 "Remote Diagnostic signal Data request";
CM_ SG_ 1723 TRM_DiagReqData4 "Remote Diagnostic signal Data request";
CM_ SG_ 1723 TRM_DiagReqData5 "Diagnostic signal Data request";
CM_ SG_ 1723 TRM_DiagReqData6 "Diagnostic signal Data request";
CM_ SG_ 1723 TRM_DiagReqData7 "Remote Diagnostic signal Data request";
CM_ BO_ 1729 "APM DiagReq";
CM_ SG_ 1729 APM_DiagReqData0 "Diagnostic signal Data request";
CM_ SG_ 1729 APM_DiagReqData1 "Diagnostic signal Data request";
CM_ SG_ 1729 APM_DiagReqData2 "Remote Diagnostic signal Data request";
CM_ SG_ 1729 APM_DiagReqData3 "Diagnostic signal Data request";
CM_ SG_ 1729 APM_DiagReqData4 "Diagnostic signal Data request";
CM_ SG_ 1729 APM_DiagReqData5 "Remote Diagnostic signal Data request";
CM_ SG_ 1729 APM_DiagReqData6 "Diagnostic signal Data request";
CM_ SG_ 1729 APM_DiagReqData7 "Diagnostic signal Data request";
CM_ BO_ 1730 "SHVU F DiagReq";
CM_ SG_ 1730 SHVU_F_DiagReqData0 "Diagnostic signal Data request";
CM_ SG_ 1730 SHVU_F_DiagReqData1 "Diagnostic signal Data request";
CM_ SG_ 1730 SHVU_F_DiagReqData2 "Diagnostic signal Data request";
CM_ SG_ 1730 SHVU_F_DiagReqData3 "Remote Diagnostic signal Data request";
CM_ SG_ 1730 SHVU_F_DiagReqData4 "Diagnostic signal Data request";
CM_ SG_ 1730 SHVU_F_DiagReqData5 "Diagnostic signal Data request";
CM_ SG_ 1730 SHVU_F_DiagReqData6 "Remote Diagnostic signal Data request";
CM_ SG_ 1730 SHVU_F_DiagReqData7 "Diagnostic signal Data request";
CM_ BO_ 1731 "SHVU R DiagReq";
CM_ SG_ 1731 SHVU_R_DiagReqData0 "Diagnostic signal Data request";
CM_ SG_ 1731 SHVU_R_DiagReqData1 "Diagnostic signal Data request";
CM_ SG_ 1731 SHVU_R_DiagReqData2 "Diagnostic signal Data request";
CM_ SG_ 1731 SHVU_R_DiagReqData3 "Diagnostic signal Data request";
CM_ SG_ 1731 SHVU_R_DiagReqData4 "Diagnostic signal Data request";
CM_ SG_ 1731 SHVU_R_DiagReqData5 "Remote Diagnostic signal Data request";
CM_ SG_ 1731 SHVU_R_DiagReqData6 "Diagnostic signal Data request";
CM_ SG_ 1731 SHVU_R_DiagReqData7 "Diagnostic signal Data request";
CM_ BO_ 1732 "OCS P DiagReq";
CM_ SG_ 1732 OCS_P_DiagReqData0 "Remote Diagnostic signal Data request";
CM_ SG_ 1732 OCS_P_DiagReqData1 "Diagnostic signal Data request";
CM_ SG_ 1732 OCS_P_DiagReqData2 "Diagnostic signal Data request";
CM_ SG_ 1732 OCS_P_DiagReqData3 "Diagnostic signal Data request";
CM_ SG_ 1732 OCS_P_DiagReqData4 "Diagnostic signal Data request";
CM_ SG_ 1732 OCS_P_DiagReqData5 "Diagnostic signal Data request";
CM_ SG_ 1732 OCS_P_DiagReqData6 "Diagnostic signal Data request";
CM_ SG_ 1732 OCS_P_DiagReqData7 "Remote Diagnostic signal Data request";
CM_ BO_ 1737 "LDM_L DiagReq";
CM_ SG_ 1737 LDM_L_DiagReqData0 "Remote Diagnostic signal Data request
";
CM_ SG_ 1737 LDM_L_DiagReqData1 "Diagnostic signal Data request";
CM_ SG_ 1737 LDM_L_DiagReqData2 "Diagnostic signal Data request";
CM_ SG_ 1737 LDM_L_DiagReqData3 "Diagnostic signal Data request";
CM_ SG_ 1737 LDM_L_DiagReqData4 "Remote Diagnostic signal Data request
";
CM_ SG_ 1737 LDM_L_DiagReqData5 "Diagnostic signal Data request";
CM_ SG_ 1737 LDM_L_DiagReqData6 "Diagnostic signal Data request";
CM_ SG_ 1737 LDM_L_DiagReqData7 "Diagnostic signal Data request";
CM_ BO_ 1738 "LDM_R DiagReq";
CM_ SG_ 1738 LDM_R_DiagReqData0 "Diagnostic signal Data request";
CM_ SG_ 1738 LDM_R_DiagReqData1 "Diagnostic signal Data request";
CM_ SG_ 1738 LDM_R_DiagReqData2 "Diagnostic signal Data request";
CM_ SG_ 1738 LDM_R_DiagReqData3 "Remote Diagnostic signal Data request
";
CM_ SG_ 1738 LDM_R_DiagReqData4 "Diagnostic signal Data request";
CM_ SG_ 1738 LDM_R_DiagReqData5 "Diagnostic signal Data request";
CM_ SG_ 1738 LDM_R_DiagReqData6 "Remote Diagnostic signal Data request
";
CM_ SG_ 1738 LDM_R_DiagReqData7 "Remote Diagnostic signal Data request
";
CM_ BO_ 1752 "BAS DiagReq";
CM_ SG_ 1752 BAS_DiagReqData0 "Diagnostic signal Data request";
CM_ SG_ 1752 BAS_DiagReqData1 "Diagnostic signal Data request";
CM_ SG_ 1752 BAS_DiagReqData2 "Diagnostic signal Data request";
CM_ SG_ 1752 BAS_DiagReqData3 "Diagnostic signal Data request";
CM_ SG_ 1752 BAS_DiagReqData4 "Diagnostic signal Data request";
CM_ SG_ 1752 BAS_DiagReqData5 "Diagnostic signal Data request";
CM_ SG_ 1752 BAS_DiagReqData6 "Diagnostic signal Data request";
CM_ SG_ 1752 BAS_DiagReqData7 "Diagnostic signal Data request";
CM_ BO_ 1764 "DCM APM DiagReq";
CM_ SG_ 1764 DCM_APM_DiagReqData0 "Remote Diagnostic signal Data request";
CM_ SG_ 1764 DCM_APM_DiagReqData1 "Remote Diagnostic signal Data request";
CM_ SG_ 1764 DCM_APM_DiagReqData2 "Remote Diagnostic signal Data request";
CM_ SG_ 1764 DCM_APM_DiagReqData3 "Remote Diagnostic signal Data request";
CM_ SG_ 1764 DCM_APM_DiagReqData4 "Diagnostic signal Data request";
CM_ SG_ 1764 DCM_APM_DiagReqData5 "Diagnostic signal Data request";
CM_ SG_ 1764 DCM_APM_DiagReqData6 "Diagnostic signal Data request";
CM_ SG_ 1764 DCM_APM_DiagReqData7 "Diagnostic signal Data request";
CM_ BO_ 1777 "ASU Diagnostic Request";
CM_ SG_ 1777 ASU_DiagReqData0 "Diagnostic signal Data request";
CM_ SG_ 1777 ASU_DiagReqData1 "Diagnostic signal Data request";
CM_ SG_ 1777 ASU_DiagReqData2 "Diagnostic signal Data request";
CM_ SG_ 1777 ASU_DiagReqData3 "Diagnostic signal Data request";
CM_ SG_ 1777 ASU_DiagReqData4 "Diagnostic signal Data request";
CM_ SG_ 1777 ASU_DiagReqData5 "Diagnostic signal Data request";
CM_ SG_ 1777 ASU_DiagReqData6 "Diagnostic signal Data request";
CM_ SG_ 1777 ASU_DiagReqData7 "Diagnostic signal Data request";
CM_ BO_ 1787 "BCM_BPM Diagnostic Request";
CM_ SG_ 1787 BCM_BPM_DiagReqData0 "Diagnostic signal Data request";
CM_ SG_ 1787 BCM_BPM_DiagReqData1 "Diagnostic signal Data request";
CM_ SG_ 1787 BCM_BPM_DiagReqData2 "Diagnostic signal Data request";
CM_ SG_ 1787 BCM_BPM_DiagReqData3 "Diagnostic signal Data request";
CM_ SG_ 1787 BCM_BPM_DiagReqData4 "Diagnostic signal Data request";
CM_ SG_ 1787 BCM_BPM_DiagReqData5 "Diagnostic signal Data request";
CM_ SG_ 1787 BCM_BPM_DiagReqData6 "Diagnostic signal Data request";
CM_ SG_ 1787 BCM_BPM_DiagReqData7 "Diagnostic signal Data request";
CM_ BO_ 1791 "Diagnostic Request for all ECUs";
CM_ SG_ 1791 OBD_Func_DiagReqData0 "Diagnostic message all ECUs";
CM_ SG_ 1791 OBD_Func_DiagReqData1 "Diagnostic message all ECUs";
CM_ SG_ 1791 OBD_Func_DiagReqData2 "Diagnostic message all ECUs";
CM_ SG_ 1791 OBD_Func_DiagReqData3 "Diagnostic message all ECUs";
CM_ SG_ 1791 OBD_Func_DiagReqData4 "Diagnostic message all ECUs";
CM_ SG_ 1791 OBD_Func_DiagReqData5 "Diagnostic message all ECUs";
CM_ SG_ 1791 OBD_Func_DiagReqData6 "Diagnostic message all ECUs";
CM_ SG_ 1791 OBD_Func_DiagReqData7 "Diagnostic message all ECUs";
CM_ BO_ 1793 "SEED_CAN_Req1";
CM_ SG_ 1793 SEED_CAN_Req1 "byte 0/1 identifier of target ECU...";
CM_ BO_ 1795 "SEED_CAN_Req2";
CM_ SG_ 1795 SEED_CAN_Req2 "byte 0/1 identifier of target ECU...";
CM_ BO_ 1803 "SEED_CAN_Req6";
CM_ SG_ 1803 SEED_CAN_Req6 "byte 0/1 identifier of target ECU
byte 2/3 service request type 270x/670x
byte 4-7 seed key";
CM_ BO_ 1805 "SEED_CAN_Req7";
CM_ SG_ 1805 SEED_CAN_Req7 "byte 0/1 identifier of target ECU
byte 2/3 service request type 270x/670x
byte 4-7 seed key";
CM_ BO_ 1809 "BCM and BCM_BPM Internal communication";
CM_ SG_ 1809 BCM_Data0 "BCM and BCM_BPM Internal communication Data0";
CM_ SG_ 1809 BCM_Data1 "BCM and BCM_BPM Internal communication Data1";
CM_ SG_ 1809 BCM_Data2 "BCM and BCM_BPM Internal communication Data2";
CM_ SG_ 1809 BCM_Data3 "BCM and BCM_BPM Internal communication Data3";
CM_ SG_ 1809 BCM_Data4 "BCM and BCM_BPM Internal communication Data4";
CM_ SG_ 1809 BCM_Data5 "BCM and BCM_BPM Internal communication Data5";
CM_ SG_ 1809 BCM_Data6 "BCM and BCM_BPM Internal communication Data6";
CM_ SG_ 1809 BCM_Data7 "BCM and BCM_BPM Internal communication Data7";
CM_ BO_ 1810 "BCM_BPM and BCM Internal communication";
CM_ SG_ 1810 BCM_BPM_Data0 "BCM and BCM_BPM Internal communication Data0";
CM_ SG_ 1810 BCM_BPM_Data1 "BCM and BCM_BPM Internal communication Data1";
CM_ SG_ 1810 BCM_BPM_Data2 "BCM and BCM_BPM Internal communication Data2";
CM_ SG_ 1810 BCM_BPM_Data3 "BCM and BCM_BPM Internal communication Data3";
CM_ SG_ 1810 BCM_BPM_Data4 "BCM and BCM_BPM Internal communication Data4";
CM_ SG_ 1810 BCM_BPM_Data5 "BCM and BCM_BPM Internal communication Data5";
CM_ SG_ 1810 BCM_BPM_Data6 "BCM and BCM_BPM Internal communication Data6";
CM_ SG_ 1810 BCM_BPM_Data7 "BCM and BCM_BPM Internal communication Data7";
CM_ BO_ 1814 "CCU debug message 3";
CM_ BO_ 1843 "SEED_CAN_Req18";
CM_ SG_ 1843 SEED_CAN_Req18 "byte 0/1 identifier of target ECU...";
CM_ BO_ 1847 "SEED_CAN_Req21";
CM_ SG_ 1847 SEED_CAN_Req21 "byte 0/1 identifier of target ECU...";
CM_ SG_ 1850 SEED_CAN_Req25 "Secret portion from Secure CAN algorithm";
CM_ SG_ 1853 SEED_CAN_Req29 "Secret portion from Secure CAN algorithm";
CM_ BO_ 1857 "Internal message for CCU supplier";
CM_ SG_ 1857 CCU_ERL_FL "Energy Requirement Level for Driver";
CM_ SG_ 1857 CCU_ERL_FR "Energy Requirement Level for Co-driver";
CM_ SG_ 1857 CCU_EvapTempSet "Evaporator Target Temperature";
CM_ SG_ 1857 CCU_BlowerFltPWM "Blower PWM";
CM_ SG_ 1857 CCU_AirDistribFlapPos "Air Distribution Flap Position";
CM_ SG_ 1857 CCU_RecircFlapPos "Air Intake Flap Position";
CM_ SG_ 1857 CCU_AirDistribFeedback "Air Distribution flap feedback";
CM_ SG_ 1857 CCU_RecircFlapFeedback "Air Intake flap feedback";
CM_ BO_ 1858 "Internal message for CCU supplier";
CM_ SG_ 1858 CCU_TempFlapPos_FL "Temperature Flap position for Driver";
CM_ SG_ 1858 CCU_TempFlapPos_FR "Temperature Flap position for Co-driver";
CM_ SG_ 1858 CCU_DuctTargetTemp_FL "Target Duct Temperature for Driver";
CM_ SG_ 1858 CCU_DuctTargetTemp_FR "Target Duct Temperature for Co-driver";
CM_ SG_ 1858 CCU_TempFLFeedback "Temperature flap feedback for FL";
CM_ SG_ 1858 CCU_TempFRFeedback "Temperature flap feedback for FR";
CM_ SG_ 1858 CCU_PTCSetTemp "Target PTC Temperature";
CM_ BO_ 2046 "Internal message for CCU supplier";
CM_ SG_ 2046 TST_TxMsgConfirm_CcuHeatCoolReq "Message is transmitted or not";
CM_ SG_ 2046 CCU_TST_TxMsgConfirm_CcuNm "Message is transmitted or not";
CM_ SG_ 2046 CCU_TST_Reserve_6 "Reserve Signal 6";
CM_ SG_ 2046 CCU_TST_Reserve_5 "Reserve Signal 5";
CM_ SG_ 2046 CCU_TST_Reserve_4 "Reserve Signal 4";
CM_ SG_ 2046 CCU_TST_Reserve_3 "Reserve Signal 3";
CM_ SG_ 2046 CCU_TST_Reserve_2 "Reserve Signal 2";
CM_ SG_ 2046 CCU_TST_Reserve_1 "Reserve Signal 1";
CM_ SG_ 2046 CCU_TST_Reserve_0 "Reserve Signal 0";
CM_ BO_ 1938 "CCU Response CCP";
CM_ SG_ 1938 CCU_Resp_CCP "For development phase only";
CM_ BO_ 1939 "LDM_L Internal Message";
CM_ SG_ 1939 LDML_FltReactn "Partial Fault Reaction of LDML";
CM_ SG_ 1939 LDML_RiAdjstAgOutp "Right light to adjust the Angle";
CM_ BO_ 1940 "LDM_R Internal Message";
CM_ SG_ 1940 LDMR_FltReactn "Partial Fault Reaction of LDMR";
CM_ SG_ 1940 LDMR_ModuleCurAg "Current Angle of right headlight module";
CM_ BO_ 1977 "CCU Response for private message for EOL purpose";
CM_ SG_ 1977 CCU_Resp_EOL "Used for BHTC End-Of-Line testing";
CM_ BO_ 1980 "CCU Response for private message for EOL purpose";
CM_ SG_ 1980 CCUR_Resp_EOL_ "Used for BHTC End-Of-Line testing";
CM_ BO_ 2015 "Diagnostic Request for all ECUs";
CM_ SG_ 2015 Diag_Request_ECU_Data0 "Diagnostic message all ECUs";
CM_ SG_ 2015 Diag_Request_ECU_Data1 "Diagnostic message all ECUs";
CM_ SG_ 2015 Diag_Request_ECU_Data2 "Diagnostic message all ECUs";
CM_ SG_ 2015 Diag_Request_ECU_Data3 "Diagnostic message all ECUs";
CM_ SG_ 2015 Diag_Request_ECU_Data4 "Diagnostic message all ECUs";
CM_ SG_ 2015 Diag_Request_ECU_Data5 "Diagnostic message all ECUs";
CM_ SG_ 2015 Diag_Request_ECU_Data6 "Diagnostic message all ECUs";
CM_ SG_ 2015 Diag_Request_ECU_Data7 "Diagnostic message all ECUs";
CM_ BO_ 2033 "ACM Scrapping Diag Req";
CM_ SG_ 2033 Request_Airbag_Deployment "Diagnostic request for ACM Scrapping";
CM_ BO_ 2041 "ACM Scrapping Diag Resp";
CM_ SG_ 2041 Response_Airbag_Deployment "Diagnostic response for ACM Scrapping";
BA_DEF_ BO_  "GenMsgSendType" ENUM  "Cyclic","NotUsed","NotUsed","NotUsed","NotUsed","NotUsed","NotUsed","IfActive","NoMsgSendType","NotUsed";
BA_DEF_ BO_  "GenMsgILSupport" ENUM  "No","Yes";
BA_DEF_ BO_  "DiagResponse" ENUM  "No","Yes";
BA_DEF_ BO_  "DiagRequest" ENUM  "No","Yes";
BA_DEF_ BO_  "NmAsrMessage" ENUM  "No","Yes";
BA_DEF_ BO_  "DiagState" ENUM  "No","Yes";
BA_DEF_ BO_  "DiagUudtResponse" ENUM  "False","True";
BA_DEF_ BO_  "GenMsgStartDelayTime" INT 0 65535;
BA_DEF_ BO_  "GenMsgDelayTime" INT 0 0;
BA_DEF_ BO_  "GenMsgNrOfRepetition" INT 0 0;
BA_DEF_ BO_  "GenMsgCycleTimeFast" INT 0 0;
BA_DEF_ BO_  "GenMsgCycleTime" INT 0 0;
BA_DEF_ SG_  "GenSigSendType" ENUM  "Cyclic","OnWrite","OnWriteWithRepetition","OnChange","OnChangeWithRepetition","IfActive","IfActiveWithRepetition","NoSigSendType","NotUsed","NotUsed","NotUsed","NotUsed","NotUsed";
BA_DEF_ SG_  "InvalidValue" STRING ;
BA_DEF_ SG_  "GenSigStartValue" INT 0 0;
BA_DEF_ SG_  "GenSigTimeoutTime_ALL" INT 0 65535;
BA_DEF_DEF_  "GenMsgSendType" "NoMsgSendType";
BA_DEF_DEF_  "GenMsgILSupport" "Yes";
BA_DEF_DEF_  "DiagResponse" "No";
BA_DEF_DEF_  "DiagRequest" "No";
BA_DEF_DEF_  "NmAsrMessage" "No";
BA_DEF_DEF_  "DiagState" "No";
BA_DEF_DEF_  "DiagUudtResponse" "False";
BA_DEF_DEF_  "GenMsgStartDelayTime" 0;
BA_DEF_DEF_  "GenMsgDelayTime" 0;
BA_DEF_DEF_  "GenMsgNrOfRepetition" 0;
BA_DEF_DEF_  "GenMsgCycleTimeFast" 0;
BA_DEF_DEF_  "GenMsgCycleTime" 0;
BA_DEF_DEF_  "GenSigSendType" "Cyclic";
BA_DEF_DEF_  "InvalidValue" "";
BA_DEF_DEF_  "GenSigStartValue" 0;
BA_DEF_DEF_  "GenSigTimeoutTime_ALL" 0;
BA_ "GenMsgCycleTime" BO_ 1161 1000;
BA_ "GenMsgSendType" BO_ 1161 0;
BA_ "GenMsgStartDelayTime" BO_ 1161 30;
BA_ "GenMsgCycleTime" BO_ 1166 100;
BA_ "GenMsgSendType" BO_ 1166 0;
BA_ "GenMsgCycleTime" BO_ 1171 1000;
BA_ "GenMsgCycleTimeFast" BO_ 1171 100;
BA_ "GenMsgNrOfRepetition" BO_ 1171 2;
BA_ "GenMsgSendType" BO_ 1171 0;
BA_ "GenMsgSendType" BO_ 1209 0;
BA_ "GenMsgCycleTime" BO_ 1209 1000;
BA_ "GenMsgCycleTime" BO_ 1211 100;
BA_ "GenMsgCycleTimeFast" BO_ 1211 25;
BA_ "GenMsgDelayTime" BO_ 1211 25;
BA_ "GenMsgNrOfRepetition" BO_ 1211 3;
BA_ "GenMsgSendType" BO_ 1211 0;
BA_ "GenMsgCycleTime" BO_ 1217 1000;
BA_ "GenMsgSendType" BO_ 1217 0;
BA_ "GenMsgCycleTime" BO_ 1281 640;
BA_ "GenMsgILSupport" BO_ 1281 0;
BA_ "GenMsgSendType" BO_ 1281 0;
BA_ "NmAsrMessage" BO_ 1281 1;
BA_ "GenMsgCycleTime" BO_ 1282 640;
BA_ "GenMsgILSupport" BO_ 1282 0;
BA_ "GenMsgSendType" BO_ 1282 0;
BA_ "NmAsrMessage" BO_ 1282 1;
BA_ "GenMsgCycleTime" BO_ 1289 640;
BA_ "GenMsgILSupport" BO_ 1289 0;
BA_ "GenMsgSendType" BO_ 1289 0;
BA_ "NmAsrMessage" BO_ 1289 1;
BA_ "GenMsgCycleTime" BO_ 1294 640;
BA_ "GenMsgILSupport" BO_ 1294 0;
BA_ "GenMsgSendType" BO_ 1294 0;
BA_ "NmAsrMessage" BO_ 1294 1;
BA_ "GenMsgCycleTime" BO_ 1339 640;
BA_ "GenMsgILSupport" BO_ 1339 0;
BA_ "GenMsgSendType" BO_ 1339 0;
BA_ "NmAsrMessage" BO_ 1339 1;
BA_ "GenMsgCycleTime" BO_ 1310 640;
BA_ "GenMsgILSupport" BO_ 1310 0;
BA_ "GenMsgSendType" BO_ 1310 0;
BA_ "NmAsrMessage" BO_ 1310 1;
BA_ "GenMsgSendType" BO_ 1337 0;
BA_ "GenMsgCycleTime" BO_ 1337 640;
BA_ "NmAsrMessage" BO_ 1337 1;
BA_ "GenMsgCycleTime" BO_ 1345 640;
BA_ "GenMsgILSupport" BO_ 1345 0;
BA_ "GenMsgSendType" BO_ 1345 0;
BA_ "NmAsrMessage" BO_ 1345 1;
BA_ "GenMsgCycleTime" BO_ 1353 640;
BA_ "GenMsgILSupport" BO_ 1353 0;
BA_ "GenMsgSendType" BO_ 1353 0;
BA_ "NmAsrMessage" BO_ 1353 1;
BA_ "GenMsgCycleTime" BO_ 1354 640;
BA_ "GenMsgILSupport" BO_ 1354 0;
BA_ "GenMsgSendType" BO_ 1354 0;
BA_ "NmAsrMessage" BO_ 1354 1;
BA_ "GenMsgCycleTime" BO_ 1360 640;
BA_ "GenMsgILSupport" BO_ 1360 0;
BA_ "GenMsgSendType" BO_ 1360 0;
BA_ "NmAsrMessage" BO_ 1360 1;
BA_ "DiagResponse" BO_ 1537 1;
BA_ "GenMsgILSupport" BO_ 1537 0;
BA_ "DiagResponse" BO_ 1544 1;
BA_ "GenMsgILSupport" BO_ 1544 0;
BA_ "DiagResponse" BO_ 1545 1;
BA_ "GenMsgILSupport" BO_ 1545 0;
BA_ "DiagResponse" BO_ 1550 1;
BA_ "GenMsgILSupport" BO_ 1550 0;
BA_ "DiagResponse" BO_ 1553 1;
BA_ "DiagResponse" BO_ 1556 1;
BA_ "GenMsgILSupport" BO_ 1556 0;
BA_ "DiagResponse" BO_ 1566 1;
BA_ "GenMsgILSupport" BO_ 1566 0;
BA_ "DiagResponse" BO_ 1585 1;
BA_ "GenMsgILSupport" BO_ 1585 0;
BA_ "DiagResponse" BO_ 1586 1;
BA_ "GenMsgILSupport" BO_ 1586 0;
BA_ "DiagResponse" BO_ 1592 1;
BA_ "DiagResponse" BO_ 1593 1;
BA_ "GenMsgILSupport" BO_ 1593 0;
BA_ "DiagResponse" BO_ 1595 1;
BA_ "GenMsgILSupport" BO_ 1595 0;
BA_ "DiagResponse" BO_ 1601 1;
BA_ "GenMsgILSupport" BO_ 1601 0;
BA_ "DiagResponse" BO_ 1602 1;
BA_ "GenMsgILSupport" BO_ 1602 0;
BA_ "DiagResponse" BO_ 1603 1;
BA_ "GenMsgILSupport" BO_ 1603 0;
BA_ "DiagResponse" BO_ 1604 1;
BA_ "GenMsgILSupport" BO_ 1604 0;
BA_ "DiagResponse" BO_ 1609 1;
BA_ "GenMsgILSupport" BO_ 1609 0;
BA_ "DiagResponse" BO_ 1610 1;
BA_ "GenMsgILSupport" BO_ 1610 0;
BA_ "DiagResponse" BO_ 1624 1;
BA_ "GenMsgILSupport" BO_ 1624 0;
BA_ "DiagResponse" BO_ 1636 1;
BA_ "GenMsgILSupport" BO_ 1636 0;
BA_ "DiagResponse" BO_ 1659 1;
BA_ "GenMsgILSupport" BO_ 1659 0;
BA_ "DiagRequest" BO_ 1665 1;
BA_ "GenMsgILSupport" BO_ 1665 0;
BA_ "DiagRequest" BO_ 1672 1;
BA_ "GenMsgILSupport" BO_ 1672 0;
BA_ "DiagRequest" BO_ 1673 1;
BA_ "GenMsgILSupport" BO_ 1673 0;
BA_ "DiagRequest" BO_ 1678 1;
BA_ "GenMsgILSupport" BO_ 1678 0;
BA_ "DiagRequest" BO_ 1681 1;
BA_ "DiagRequest" BO_ 1684 1;
BA_ "GenMsgILSupport" BO_ 1684 0;
BA_ "DiagRequest" BO_ 1694 1;
BA_ "GenMsgILSupport" BO_ 1694 0;
BA_ "DiagRequest" BO_ 1713 1;
BA_ "GenMsgILSupport" BO_ 1713 0;
BA_ "DiagRequest" BO_ 1714 1;
BA_ "GenMsgILSupport" BO_ 1714 0;
BA_ "DiagRequest" BO_ 1721 1;
BA_ "GenMsgILSupport" BO_ 1721 0;
BA_ "DiagRequest" BO_ 1723 1;
BA_ "GenMsgILSupport" BO_ 1723 0;
BA_ "DiagRequest" BO_ 1729 1;
BA_ "GenMsgILSupport" BO_ 1729 0;
BA_ "DiagRequest" BO_ 1730 1;
BA_ "GenMsgILSupport" BO_ 1730 0;
BA_ "DiagRequest" BO_ 1731 1;
BA_ "GenMsgILSupport" BO_ 1731 0;
BA_ "DiagRequest" BO_ 1732 1;
BA_ "GenMsgILSupport" BO_ 1732 0;
BA_ "DiagRequest" BO_ 1737 1;
BA_ "GenMsgILSupport" BO_ 1737 0;
BA_ "DiagRequest" BO_ 1738 1;
BA_ "GenMsgILSupport" BO_ 1738 0;
BA_ "DiagRequest" BO_ 1752 1;
BA_ "GenMsgILSupport" BO_ 1752 0;
BA_ "DiagRequest" BO_ 1764 1;
BA_ "GenMsgILSupport" BO_ 1764 0;
BA_ "DiagRequest" BO_ 1777 1;
BA_ "DiagRequest" BO_ 1787 1;
BA_ "GenMsgILSupport" BO_ 1787 0;
BA_ "DiagRequest" BO_ 1791 1;
BA_ "DiagState" BO_ 1791 1;
BA_ "GenMsgILSupport" BO_ 1791 0;
BA_ "GenMsgCycleTime" BO_ 1809 50;
BA_ "GenMsgSendType" BO_ 1809 0;
BA_ "GenMsgCycleTime" BO_ 1810 50;
BA_ "GenMsgSendType" BO_ 1810 0;
BA_ "GenMsgCycleTime" BO_ 1814 200;
BA_ "GenMsgSendType" BO_ 1814 0;
BA_ "GenMsgStartDelayTime" BO_ 1814 45;
BA_ "GenMsgCycleTime" BO_ 1857 200;
BA_ "GenMsgSendType" BO_ 1857 0;
BA_ "GenMsgStartDelayTime" BO_ 1857 35;
BA_ "GenMsgCycleTime" BO_ 1858 200;
BA_ "GenMsgSendType" BO_ 1858 0;
BA_ "GenMsgStartDelayTime" BO_ 1858 40;
BA_ "GenMsgSendType" BO_ 2046 0;
BA_ "GenMsgStartDelayTime" BO_ 2046 50;
BA_ "GenMsgCycleTime" BO_ 2046 200;
BA_ "DiagResponse" BO_ 1938 1;
BA_ "GenMsgCycleTime" BO_ 1939 50;
BA_ "GenMsgSendType" BO_ 1939 0;
BA_ "GenMsgCycleTime" BO_ 1940 50;
BA_ "GenMsgSendType" BO_ 1940 0;
BA_ "DiagResponse" BO_ 1977 1;
BA_ "DiagResponse" BO_ 1980 1;
BA_ "DiagRequest" BO_ 2015 1;
BA_ "DiagRequest" BO_ 2033 1;
BA_ "GenMsgILSupport" BO_ 2033 0;
BA_ "DiagResponse" BO_ 2041 1;
BA_ "GenMsgILSupport" BO_ 2041 0;
BA_ "GenSigTimeoutTime_ALL" SG_ 1161 CHSKM_CCU_WarnMsg 500;
BA_ "InvalidValue" SG_ 1161 CHSKM_CCU_WarnMsg "null";
BA_ "GenSigTimeoutTime_ALL" SG_ 1161 ALV_CCU_WarnMsg 500;
BA_ "InvalidValue" SG_ 1161 ALV_CCU_WarnMsg "Fh";
BA_ "GenSigTimeoutTime_ALL" SG_ 1161 CCU_Malfunction 500;
BA_ "InvalidValue" SG_ 1161 CCU_Malfunction "null";
BA_ "GenSigTimeoutTime_ALL" SG_ 1161 CCU_Warning_Flag_2 500;
BA_ "InvalidValue" SG_ 1161 CCU_Warning_Flag_2 "null";
BA_ "GenSigTimeoutTime_ALL" SG_ 1161 CCU_Warning_Flag_3 500;
BA_ "InvalidValue" SG_ 1161 CCU_Warning_Flag_3 "null";
BA_ "GenSigTimeoutTime_ALL" SG_ 1161 CCU_Warning_Flag_4 500;
BA_ "InvalidValue" SG_ 1161 CCU_Warning_Flag_4 "null";
BA_ "GenSigTimeoutTime_ALL" SG_ 1161 CCU_Warning_Flag_5 500;
BA_ "InvalidValue" SG_ 1161 CCU_Warning_Flag_5 "null";
BA_ "GenSigTimeoutTime_ALL" SG_ 1161 CCU_Warning_Flag_6 500;
BA_ "InvalidValue" SG_ 1161 CCU_Warning_Flag_6 "null";
BA_ "GenSigTimeoutTime_ALL" SG_ 1161 CCU_Warning_Flag_7 500;
BA_ "InvalidValue" SG_ 1161 CCU_Warning_Flag_7 "null";
BA_ "GenSigTimeoutTime_ALL" SG_ 1161 CCU_Warning_Flag_8 500;
BA_ "InvalidValue" SG_ 1161 CCU_Warning_Flag_8 "null";
BA_ "GenSigTimeoutTime_ALL" SG_ 1161 CCU_Warning_Flag_9 500;
BA_ "InvalidValue" SG_ 1161 CCU_Warning_Flag_9 "null";
BA_ "GenSigTimeoutTime_ALL" SG_ 1161 CCU_Warning_Flag_10 500;
BA_ "InvalidValue" SG_ 1161 CCU_Warning_Flag_10 "null";
BA_ "GenSigTimeoutTime_ALL" SG_ 1161 CCU_Warning_Flag_11 500;
BA_ "InvalidValue" SG_ 1161 CCU_Warning_Flag_11 "null";
BA_ "GenSigTimeoutTime_ALL" SG_ 1161 CCU_Warning_Flag_12 500;
BA_ "InvalidValue" SG_ 1161 CCU_Warning_Flag_12 "null";
BA_ "GenSigTimeoutTime_ALL" SG_ 1166 CHSKM_ETG_WarnMsg 500;
BA_ "InvalidValue" SG_ 1166 CHSKM_ETG_WarnMsg "null";
BA_ "GenSigTimeoutTime_ALL" SG_ 1166 ALV_ETG_WarnMsg 500;
BA_ "InvalidValue" SG_ 1166 ALV_ETG_WarnMsg "Fh";
BA_ "GenSigTimeoutTime_ALL" SG_ 1166 ETG_Malfunction 500;
BA_ "InvalidValue" SG_ 1166 ETG_Malfunction "null";
BA_ "GenSigTimeoutTime_ALL" SG_ 1166 ETG_Warning_Flag_2 500;
BA_ "InvalidValue" SG_ 1166 ETG_Warning_Flag_2 "null";
BA_ "GenSigTimeoutTime_ALL" SG_ 1166 ETG_Warning_Flag_3 500;
BA_ "InvalidValue" SG_ 1166 ETG_Warning_Flag_3 "null";
BA_ "GenSigTimeoutTime_ALL" SG_ 1166 ETG_Warning_Flag_4 500;
BA_ "InvalidValue" SG_ 1166 ETG_Warning_Flag_4 "null";
BA_ "GenSigTimeoutTime_ALL" SG_ 1166 ETG_Warning_Flag_5 500;
BA_ "InvalidValue" SG_ 1166 ETG_Warning_Flag_5 "null";
BA_ "GenSigTimeoutTime_ALL" SG_ 1166 ETG_Warning_Flag_6 500;
BA_ "InvalidValue" SG_ 1166 ETG_Warning_Flag_6 "null";
BA_ "GenSigTimeoutTime_ALL" SG_ 1166 ETG_Warning_Flag_7 500;
BA_ "InvalidValue" SG_ 1166 ETG_Warning_Flag_7 "null";
BA_ "GenSigTimeoutTime_ALL" SG_ 1166 ETG_Warning_Flag_8 500;
BA_ "InvalidValue" SG_ 1166 ETG_Warning_Flag_8 "null";
BA_ "GenSigTimeoutTime_ALL" SG_ 1166 ETG_Warning_Flag_9 500;
BA_ "InvalidValue" SG_ 1166 ETG_Warning_Flag_9 "null";
BA_ "GenSigTimeoutTime_ALL" SG_ 1166 ETG_Warning_Flag_10 500;
BA_ "InvalidValue" SG_ 1166 ETG_Warning_Flag_10 "null";
BA_ "GenSigTimeoutTime_ALL" SG_ 1166 ETG_Warning_Flag_11 500;
BA_ "InvalidValue" SG_ 1166 ETG_Warning_Flag_11 "null";
BA_ "GenSigTimeoutTime_ALL" SG_ 1166 ETG_Warning_Flag_12 500;
BA_ "InvalidValue" SG_ 1166 ETG_Warning_Flag_12 "null";
BA_ "GenSigSendType" SG_ 1171 CHSKM_BMS_WarnMsg 3;
BA_ "GenSigTimeoutTime_ALL" SG_ 1171 CHSKM_BMS_WarnMsg 5000;
BA_ "InvalidValue" SG_ 1171 CHSKM_BMS_WarnMsg "null";
BA_ "GenSigSendType" SG_ 1171 ALV_BMS_WarnMsg 3;
BA_ "GenSigTimeoutTime_ALL" SG_ 1171 ALV_BMS_WarnMsg 5000;
BA_ "InvalidValue" SG_ 1171 ALV_BMS_WarnMsg "Fh";
BA_ "GenSigSendType" SG_ 1171 BMS_PackTempSts 4;
BA_ "GenSigTimeoutTime_ALL" SG_ 1171 BMS_PackTempSts 5000;
BA_ "InvalidValue" SG_ 1171 BMS_PackTempSts "null";
BA_ "GenSigSendType" SG_ 1171 BMS_ThermalRunaway 4;
BA_ "GenSigTimeoutTime_ALL" SG_ 1171 BMS_ThermalRunaway 5000;
BA_ "InvalidValue" SG_ 1171 BMS_ThermalRunaway "null";
BA_ "GenSigSendType" SG_ 1171 BMS_BatteryReplacement 4;
BA_ "GenSigTimeoutTime_ALL" SG_ 1171 BMS_BatteryReplacement 5000;
BA_ "InvalidValue" SG_ 1171 BMS_BatteryReplacement "null";
BA_ "GenSigSendType" SG_ 1171 BMS_Warning_PowerDegrade 4;
BA_ "GenSigTimeoutTime_ALL" SG_ 1171 BMS_Warning_PowerDegrade 5000;
BA_ "InvalidValue" SG_ 1171 BMS_Warning_PowerDegrade "null";
BA_ "GenSigSendType" SG_ 1171 BMS_Warning_DeltaSoC 4;
BA_ "GenSigTimeoutTime_ALL" SG_ 1171 BMS_Warning_DeltaSoC 5000;
BA_ "InvalidValue" SG_ 1171 BMS_Warning_DeltaSoC "null";
BA_ "GenSigSendType" SG_ 1171 BMS_Warning_HVILSts 4;
BA_ "GenSigTimeoutTime_ALL" SG_ 1171 BMS_Warning_HVILSts 5000;
BA_ "InvalidValue" SG_ 1171 BMS_Warning_HVILSts "null";
BA_ "GenSigSendType" SG_ 1171 BMS_Warning_Isolation 4;
BA_ "GenSigTimeoutTime_ALL" SG_ 1171 BMS_Warning_Isolation 5000;
BA_ "InvalidValue" SG_ 1171 BMS_Warning_Isolation "null";
BA_ "GenSigSendType" SG_ 1171 BMS_Warning_CoolantLeakage 4;
BA_ "GenSigTimeoutTime_ALL" SG_ 1171 BMS_Warning_CoolantLeakage 5000;
BA_ "InvalidValue" SG_ 1171 BMS_Warning_CoolantLeakage "null";
BA_ "GenSigSendType" SG_ 1171 BMS_MalfunctionSts 4;
BA_ "GenSigTimeoutTime_ALL" SG_ 1171 BMS_MalfunctionSts 5000;
BA_ "InvalidValue" SG_ 1171 BMS_MalfunctionSts "null";
BA_ "GenSigSendType" SG_ 1171 BMS_LowBattery 4;
BA_ "GenSigTimeoutTime_ALL" SG_ 1171 BMS_LowBattery 5000;
BA_ "InvalidValue" SG_ 1171 BMS_LowBattery "null";
BA_ "GenSigSendType" SG_ 1171 BMS_Warning_DeltaTemperature 4;
BA_ "GenSigTimeoutTime_ALL" SG_ 1171 BMS_Warning_DeltaTemperature 5000;
BA_ "InvalidValue" SG_ 1171 BMS_Warning_DeltaTemperature "null";
BA_ "GenSigSendType" SG_ 1171 BMS_Warning_BDUTemperatureSts 4;
BA_ "GenSigTimeoutTime_ALL" SG_ 1171 BMS_Warning_BDUTemperatureSts 5000;
BA_ "InvalidValue" SG_ 1171 BMS_Warning_BDUTemperatureSts "null";
BA_ "GenSigSendType" SG_ 1171 BMS_Reserved_signal3 4;
BA_ "GenSigTimeoutTime_ALL" SG_ 1171 BMS_Reserved_signal3 5000;
BA_ "InvalidValue" SG_ 1171 BMS_Reserved_signal3 "null";
BA_ "GenSigSendType" SG_ 1171 BMS_Reserved_signal4 4;
BA_ "GenSigTimeoutTime_ALL" SG_ 1171 BMS_Reserved_signal4 5000;
BA_ "InvalidValue" SG_ 1171 BMS_Reserved_signal4 "null";
BA_ "GenSigSendType" SG_ 1171 BMS_Reserved_signal5 4;
BA_ "GenSigTimeoutTime_ALL" SG_ 1171 BMS_Reserved_signal5 5000;
BA_ "InvalidValue" SG_ 1171 BMS_Reserved_signal5 "null";
BA_ "GenSigTimeoutTime_ALL" SG_ 1209 Checksum_0x4C3 5000;
BA_ "InvalidValue" SG_ 1209 Checksum_0x4C3 "0";
BA_ "GenSigTimeoutTime_ALL" SG_ 1209 Rolling_Counter_0x4C3 5000;
BA_ "InvalidValue" SG_ 1209 Rolling_Counter_0x4C3 "Fh";
BA_ "GenSigTimeoutTime_ALL" SG_ 1209 BSD_Warning_Flag_7 5000;
BA_ "InvalidValue" SG_ 1209 BSD_Warning_Flag_7 "0";
BA_ "GenSigTimeoutTime_ALL" SG_ 1209 BSD_Warning_Flag_8 5000;
BA_ "InvalidValue" SG_ 1209 BSD_Warning_Flag_8 "0";
BA_ "GenSigTimeoutTime_ALL" SG_ 1209 BSD_Warning_Flag_9 5000;
BA_ "InvalidValue" SG_ 1209 BSD_Warning_Flag_9 "0";
BA_ "GenSigTimeoutTime_ALL" SG_ 1209 BSD_Warning_Flag_10 5000;
BA_ "InvalidValue" SG_ 1209 BSD_Warning_Flag_10 "0";
BA_ "GenSigTimeoutTime_ALL" SG_ 1209 BSD_Warning_Flag_14 5000;
BA_ "InvalidValue" SG_ 1209 BSD_Warning_Flag_14 "0";
BA_ "GenSigTimeoutTime_ALL" SG_ 1209 BSD_Warning_Flag_21 5000;
BA_ "InvalidValue" SG_ 1209 BSD_Warning_Flag_21 "0";
BA_ "GenSigTimeoutTime_ALL" SG_ 1209 BSD_Warning_Flag_22 5000;
BA_ "InvalidValue" SG_ 1209 BSD_Warning_Flag_22 "0";
BA_ "GenSigTimeoutTime_ALL" SG_ 1209 BSD_Warning_Flag_23 5000;
BA_ "InvalidValue" SG_ 1209 BSD_Warning_Flag_23 "0";
BA_ "GenSigTimeoutTime_ALL" SG_ 1209 BSD_Warning_Flag_24 5000;
BA_ "InvalidValue" SG_ 1209 BSD_Warning_Flag_24 "0";
BA_ "GenSigSendType" SG_ 1211 CHSKM_TRM_WarnMsg 4;
BA_ "GenSigTimeoutTime_ALL" SG_ 1211 CHSKM_TRM_WarnMsg 500;
BA_ "InvalidValue" SG_ 1211 CHSKM_TRM_WarnMsg "null";
BA_ "GenSigSendType" SG_ 1211 ALV_TRM_WarnMsg 4;
BA_ "GenSigTimeoutTime_ALL" SG_ 1211 ALV_TRM_WarnMsg 500;
BA_ "InvalidValue" SG_ 1211 ALV_TRM_WarnMsg "Fh";
BA_ "GenSigSendType" SG_ 1211 TRM_LightMalfnc 4;
BA_ "GenSigTimeoutTime_ALL" SG_ 1211 TRM_LightMalfnc 500;
BA_ "InvalidValue" SG_ 1211 TRM_LightMalfnc "null";
BA_ "GenSigSendType" SG_ 1211 TRM_TurnLeftMafnc 4;
BA_ "GenSigTimeoutTime_ALL" SG_ 1211 TRM_TurnLeftMafnc 500;
BA_ "InvalidValue" SG_ 1211 TRM_TurnLeftMafnc "null";
BA_ "GenSigSendType" SG_ 1211 TRM_TurnRightMafnc 4;
BA_ "GenSigTimeoutTime_ALL" SG_ 1211 TRM_TurnRightMafnc 500;
BA_ "InvalidValue" SG_ 1211 TRM_TurnRightMafnc "null";
BA_ "GenSigSendType" SG_ 1211 TRM_TrailerMalfnc 4;
BA_ "GenSigTimeoutTime_ALL" SG_ 1211 TRM_TrailerMalfnc 500;
BA_ "InvalidValue" SG_ 1211 TRM_TrailerMalfnc "null";
BA_ "GenSigSendType" SG_ 1211 TRM_Warning_Flag_5 4;
BA_ "GenSigTimeoutTime_ALL" SG_ 1211 TRM_Warning_Flag_5 500;
BA_ "InvalidValue" SG_ 1211 TRM_Warning_Flag_5 "null";
BA_ "GenSigSendType" SG_ 1211 TRM_Warning_Flag_6 4;
BA_ "GenSigTimeoutTime_ALL" SG_ 1211 TRM_Warning_Flag_6 500;
BA_ "InvalidValue" SG_ 1211 TRM_Warning_Flag_6 "null";
BA_ "GenSigSendType" SG_ 1211 TRM_Warning_Flag_7 4;
BA_ "GenSigTimeoutTime_ALL" SG_ 1211 TRM_Warning_Flag_7 500;
BA_ "InvalidValue" SG_ 1211 TRM_Warning_Flag_7 "null";
BA_ "GenSigSendType" SG_ 1211 TRM_Warning_Flag_8 4;
BA_ "GenSigTimeoutTime_ALL" SG_ 1211 TRM_Warning_Flag_8 500;
BA_ "InvalidValue" SG_ 1211 TRM_Warning_Flag_8 "null";
BA_ "GenSigSendType" SG_ 1211 TRM_Warning_Flag_9 4;
BA_ "GenSigTimeoutTime_ALL" SG_ 1211 TRM_Warning_Flag_9 500;
BA_ "InvalidValue" SG_ 1211 TRM_Warning_Flag_9 "null";
BA_ "GenSigSendType" SG_ 1211 TRM_Warning_Flag_10 4;
BA_ "GenSigTimeoutTime_ALL" SG_ 1211 TRM_Warning_Flag_10 500;
BA_ "InvalidValue" SG_ 1211 TRM_Warning_Flag_10 "null";
BA_ "GenSigSendType" SG_ 1211 TRM_Warning_Flag_11 4;
BA_ "GenSigTimeoutTime_ALL" SG_ 1211 TRM_Warning_Flag_11 500;
BA_ "InvalidValue" SG_ 1211 TRM_Warning_Flag_11 "null";
BA_ "GenSigSendType" SG_ 1211 TRM_Warning_Flag_12 4;
BA_ "GenSigTimeoutTime_ALL" SG_ 1211 TRM_Warning_Flag_12 500;
BA_ "InvalidValue" SG_ 1211 TRM_Warning_Flag_12 "null";
BA_ "GenSigSendType" SG_ 1216 BCM_STAT_DoorHandleRR 3;
BA_ "GenSigSendType" SG_ 1216 BCM_STAT_DoorHandleRL 3;
BA_ "GenSigSendType" SG_ 1216 BCM_STAT_DoorHandleFR 3;
BA_ "GenSigSendType" SG_ 1216 BCM_STAT_DoorHandleFL 3;
BA_ "GenSigSendType" SG_ 1217 CHSKM_APM_WarnMsg 3;
BA_ "GenSigTimeoutTime_ALL" SG_ 1217 CHSKM_APM_WarnMsg 5000;
BA_ "GenSigSendType" SG_ 1217 ALV_APM_WarnMsg 3;
BA_ "GenSigTimeoutTime_ALL" SG_ 1217 ALV_APM_WarnMsg 5000;
BA_ "InvalidValue" SG_ 1217 ALV_APM_WarnMsg "Fh";
BA_ "GenSigSendType" SG_ 1217 APM_Malfunction 4;
BA_ "GenSigTimeoutTime_ALL" SG_ 1217 APM_Malfunction 5000;
BA_ "InvalidValue" SG_ 1217 APM_Malfunction "null";
BA_ "GenSigSendType" SG_ 1217 ChildWindowLockStS 4;
BA_ "GenSigTimeoutTime_ALL" SG_ 1217 ChildWindowLockStS 5000;
BA_ "GenSigSendType" SG_ 1217 APM_Warning_Flag_3 4;
BA_ "GenSigTimeoutTime_ALL" SG_ 1217 APM_Warning_Flag_3 5000;
BA_ "GenSigSendType" SG_ 1217 APM_Warning_Flag_4 4;
BA_ "GenSigTimeoutTime_ALL" SG_ 1217 APM_Warning_Flag_4 5000;
BA_ "GenSigSendType" SG_ 1217 APM_Warning_Flag_5 4;
BA_ "GenSigTimeoutTime_ALL" SG_ 1217 APM_Warning_Flag_5 5000;
BA_ "GenSigSendType" SG_ 1217 APM_Warning_Flag_6 4;
BA_ "GenSigTimeoutTime_ALL" SG_ 1217 APM_Warning_Flag_6 5000;
BA_ "GenSigSendType" SG_ 1217 APM_Warning_Flag_7 4;
BA_ "GenSigTimeoutTime_ALL" SG_ 1217 APM_Warning_Flag_7 5000;
BA_ "GenSigSendType" SG_ 1217 APM_Warning_Flag_8 4;
BA_ "GenSigTimeoutTime_ALL" SG_ 1217 APM_Warning_Flag_8 5000;
BA_ "GenSigSendType" SG_ 1217 APM_Warning_Flag_9 4;
BA_ "GenSigTimeoutTime_ALL" SG_ 1217 APM_Warning_Flag_9 5000;
BA_ "GenSigSendType" SG_ 1217 APM_Warning_Flag_10 4;
BA_ "GenSigTimeoutTime_ALL" SG_ 1217 APM_Warning_Flag_10 5000;
BA_ "GenSigSendType" SG_ 1217 APM_Warning_Flag_11 4;
BA_ "GenSigTimeoutTime_ALL" SG_ 1217 APM_Warning_Flag_11 5000;
BA_ "GenSigSendType" SG_ 1217 APM_Warning_Flag_12 4;
BA_ "GenSigTimeoutTime_ALL" SG_ 1217 APM_Warning_Flag_12 5000;
BA_ "GenSigTimeoutTime_ALL" SG_ 1281 BCM_srcNodeID 2000;
BA_ "InvalidValue" SG_ 1281 BCM_srcNodeID "null";
BA_ "GenSigTimeoutTime_ALL" SG_ 1281 BCM_CtrlBitVector 2000;
BA_ "InvalidValue" SG_ 1281 BCM_CtrlBitVector "null";
BA_ "GenSigStartValue" SG_ 1281 BCM_usrData0 255;
BA_ "GenSigTimeoutTime_ALL" SG_ 1281 BCM_usrData0 2000;
BA_ "InvalidValue" SG_ 1281 BCM_usrData0 "null";
BA_ "GenSigStartValue" SG_ 1281 BCM_usrData1 255;
BA_ "GenSigTimeoutTime_ALL" SG_ 1281 BCM_usrData1 2000;
BA_ "InvalidValue" SG_ 1281 BCM_usrData1 "null";
BA_ "GenSigStartValue" SG_ 1281 BCM_usrData2 255;
BA_ "GenSigTimeoutTime_ALL" SG_ 1281 BCM_usrData2 2000;
BA_ "InvalidValue" SG_ 1281 BCM_usrData2 "null";
BA_ "GenSigStartValue" SG_ 1281 BCM_usrData3 255;
BA_ "GenSigTimeoutTime_ALL" SG_ 1281 BCM_usrData3 2000;
BA_ "InvalidValue" SG_ 1281 BCM_usrData3 "null";
BA_ "GenSigStartValue" SG_ 1281 BCM_usrData4 255;
BA_ "GenSigTimeoutTime_ALL" SG_ 1281 BCM_usrData4 2000;
BA_ "InvalidValue" SG_ 1281 BCM_usrData4 "null";
BA_ "GenSigStartValue" SG_ 1281 BCM_usrData5 255;
BA_ "GenSigTimeoutTime_ALL" SG_ 1281 BCM_usrData5 2000;
BA_ "InvalidValue" SG_ 1281 BCM_usrData5 "null";
BA_ "GenSigTimeoutTime_ALL" SG_ 1282 XGW_srcNodeID 2000;
BA_ "InvalidValue" SG_ 1282 XGW_srcNodeID "FFh";
BA_ "GenSigTimeoutTime_ALL" SG_ 1282 XGW_CtrlBitVector 2000;
BA_ "InvalidValue" SG_ 1282 XGW_CtrlBitVector "null";
BA_ "GenSigStartValue" SG_ 1282 XGW_usrData0 255;
BA_ "GenSigTimeoutTime_ALL" SG_ 1282 XGW_usrData0 2000;
BA_ "InvalidValue" SG_ 1282 XGW_usrData0 "null";
BA_ "GenSigStartValue" SG_ 1282 XGW_usrData1 255;
BA_ "GenSigTimeoutTime_ALL" SG_ 1282 XGW_usrData1 2000;
BA_ "InvalidValue" SG_ 1282 XGW_usrData1 "null";
BA_ "GenSigStartValue" SG_ 1282 XGW_usrData2 255;
BA_ "GenSigTimeoutTime_ALL" SG_ 1282 XGW_usrData2 2000;
BA_ "InvalidValue" SG_ 1282 XGW_usrData2 "null";
BA_ "GenSigStartValue" SG_ 1282 XGW_usrData3 255;
BA_ "GenSigTimeoutTime_ALL" SG_ 1282 XGW_usrData3 2000;
BA_ "InvalidValue" SG_ 1282 XGW_usrData3 "null";
BA_ "GenSigStartValue" SG_ 1282 XGW_usrData4 255;
BA_ "GenSigTimeoutTime_ALL" SG_ 1282 XGW_usrData4 2000;
BA_ "InvalidValue" SG_ 1282 XGW_usrData4 "null";
BA_ "GenSigStartValue" SG_ 1282 XGW_usrData5 255;
BA_ "GenSigTimeoutTime_ALL" SG_ 1282 XGW_usrData5 2000;
BA_ "InvalidValue" SG_ 1282 XGW_usrData5 "null";
BA_ "GenSigTimeoutTime_ALL" SG_ 1289 CCUF_srcNodeID 2000;
BA_ "InvalidValue" SG_ 1289 CCUF_srcNodeID "null";
BA_ "GenSigTimeoutTime_ALL" SG_ 1289 CCUF_CtrlBitVector 2000;
BA_ "InvalidValue" SG_ 1289 CCUF_CtrlBitVector "null";
BA_ "GenSigStartValue" SG_ 1289 CCUF_usrData0 255;
BA_ "GenSigTimeoutTime_ALL" SG_ 1289 CCUF_usrData0 2000;
BA_ "InvalidValue" SG_ 1289 CCUF_usrData0 "null";
BA_ "GenSigStartValue" SG_ 1289 CCUF_usrData1 255;
BA_ "GenSigTimeoutTime_ALL" SG_ 1289 CCUF_usrData1 2000;
BA_ "InvalidValue" SG_ 1289 CCUF_usrData1 "null";
BA_ "GenSigStartValue" SG_ 1289 CCUF_usrData2 255;
BA_ "GenSigTimeoutTime_ALL" SG_ 1289 CCUF_usrData2 2000;
BA_ "InvalidValue" SG_ 1289 CCUF_usrData2 "null";
BA_ "GenSigStartValue" SG_ 1289 CCUF_usrData3 255;
BA_ "GenSigTimeoutTime_ALL" SG_ 1289 CCUF_usrData3 2000;
BA_ "InvalidValue" SG_ 1289 CCUF_usrData3 "null";
BA_ "GenSigStartValue" SG_ 1289 CCUF_usrData4 255;
BA_ "GenSigTimeoutTime_ALL" SG_ 1289 CCUF_usrData4 2000;
BA_ "InvalidValue" SG_ 1289 CCUF_usrData4 "null";
BA_ "GenSigStartValue" SG_ 1289 CCUF_usrData5 255;
BA_ "GenSigTimeoutTime_ALL" SG_ 1289 CCUF_usrData5 2000;
BA_ "InvalidValue" SG_ 1289 CCUF_usrData5 "null";
BA_ "GenSigTimeoutTime_ALL" SG_ 1294 ETG_srcNodeID 2000;
BA_ "InvalidValue" SG_ 1294 ETG_srcNodeID "null";
BA_ "GenSigTimeoutTime_ALL" SG_ 1294 ETG_CtrlBitVector 2000;
BA_ "InvalidValue" SG_ 1294 ETG_CtrlBitVector "null";
BA_ "GenSigStartValue" SG_ 1294 ETG_usrData0 255;
BA_ "GenSigTimeoutTime_ALL" SG_ 1294 ETG_usrData0 2000;
BA_ "InvalidValue" SG_ 1294 ETG_usrData0 "null";
BA_ "GenSigStartValue" SG_ 1294 ETG_usrData1 255;
BA_ "GenSigTimeoutTime_ALL" SG_ 1294 ETG_usrData1 2000;
BA_ "InvalidValue" SG_ 1294 ETG_usrData1 "null";
BA_ "GenSigStartValue" SG_ 1294 ETG_usrData2 255;
BA_ "GenSigTimeoutTime_ALL" SG_ 1294 ETG_usrData2 2000;
BA_ "InvalidValue" SG_ 1294 ETG_usrData2 "null";
BA_ "GenSigStartValue" SG_ 1294 ETG_usrData3 255;
BA_ "GenSigTimeoutTime_ALL" SG_ 1294 ETG_usrData3 2000;
BA_ "InvalidValue" SG_ 1294 ETG_usrData3 "null";
BA_ "GenSigStartValue" SG_ 1294 ETG_usrData4 255;
BA_ "GenSigTimeoutTime_ALL" SG_ 1294 ETG_usrData4 2000;
BA_ "InvalidValue" SG_ 1294 ETG_usrData4 "null";
BA_ "GenSigStartValue" SG_ 1294 ETG_usrData5 255;
BA_ "GenSigTimeoutTime_ALL" SG_ 1294 ETG_usrData5 2000;
BA_ "InvalidValue" SG_ 1294 ETG_usrData5 "null";
BA_ "GenSigTimeoutTime_ALL" SG_ 1339 TRM_srcNodeID 2000;
BA_ "InvalidValue" SG_ 1339 TRM_srcNodeID "FFh";
BA_ "GenSigTimeoutTime_ALL" SG_ 1339 TRM_CtrlBitVector 2000;
BA_ "InvalidValue" SG_ 1339 TRM_CtrlBitVector "null";
BA_ "GenSigStartValue" SG_ 1339 TRM_usrData0 255;
BA_ "GenSigTimeoutTime_ALL" SG_ 1339 TRM_usrData0 2000;
BA_ "InvalidValue" SG_ 1339 TRM_usrData0 "null";
BA_ "GenSigStartValue" SG_ 1339 TRM_usrData1 255;
BA_ "GenSigTimeoutTime_ALL" SG_ 1339 TRM_usrData1 2000;
BA_ "InvalidValue" SG_ 1339 TRM_usrData1 "null";
BA_ "GenSigStartValue" SG_ 1339 TRM_usrData2 255;
BA_ "GenSigTimeoutTime_ALL" SG_ 1339 TRM_usrData2 2000;
BA_ "InvalidValue" SG_ 1339 TRM_usrData2 "null";
BA_ "GenSigStartValue" SG_ 1339 TRM_usrData3 255;
BA_ "GenSigTimeoutTime_ALL" SG_ 1339 TRM_usrData3 2000;
BA_ "InvalidValue" SG_ 1339 TRM_usrData3 "null";
BA_ "GenSigStartValue" SG_ 1339 TRM_usrData4 255;
BA_ "GenSigTimeoutTime_ALL" SG_ 1339 TRM_usrData4 2000;
BA_ "InvalidValue" SG_ 1339 TRM_usrData4 "null";
BA_ "GenSigStartValue" SG_ 1339 TRM_usrData5 255;
BA_ "GenSigTimeoutTime_ALL" SG_ 1339 TRM_usrData5 2000;
BA_ "InvalidValue" SG_ 1339 TRM_usrData5 "null";
BA_ "GenSigTimeoutTime_ALL" SG_ 1310 PSM_D_srcNodeID 2000;
BA_ "InvalidValue" SG_ 1310 PSM_D_srcNodeID "null";
BA_ "GenSigTimeoutTime_ALL" SG_ 1310 PSM_D_CtrlBitVector 2000;
BA_ "InvalidValue" SG_ 1310 PSM_D_CtrlBitVector "null";
BA_ "GenSigStartValue" SG_ 1310 PSM_D_usrData0 255;
BA_ "GenSigTimeoutTime_ALL" SG_ 1310 PSM_D_usrData0 2000;
BA_ "InvalidValue" SG_ 1310 PSM_D_usrData0 "null";
BA_ "GenSigStartValue" SG_ 1310 PSM_D_usrData1 255;
BA_ "GenSigTimeoutTime_ALL" SG_ 1310 PSM_D_usrData1 2000;
BA_ "InvalidValue" SG_ 1310 PSM_D_usrData1 "null";
BA_ "GenSigStartValue" SG_ 1310 PSM_D_usrData2 255;
BA_ "GenSigTimeoutTime_ALL" SG_ 1310 PSM_D_usrData2 2000;
BA_ "InvalidValue" SG_ 1310 PSM_D_usrData2 "null";
BA_ "GenSigStartValue" SG_ 1310 PSM_D_usrData3 255;
BA_ "GenSigTimeoutTime_ALL" SG_ 1310 PSM_D_usrData3 2000;
BA_ "InvalidValue" SG_ 1310 PSM_D_usrData3 "null";
BA_ "GenSigStartValue" SG_ 1310 PSM_D_usrData4 255;
BA_ "GenSigTimeoutTime_ALL" SG_ 1310 PSM_D_usrData4 2000;
BA_ "InvalidValue" SG_ 1310 PSM_D_usrData4 "null";
BA_ "GenSigStartValue" SG_ 1310 PSM_D_usrData5 255;
BA_ "GenSigTimeoutTime_ALL" SG_ 1310 PSM_D_usrData5 2000;
BA_ "InvalidValue" SG_ 1310 PSM_D_usrData5 "null";
BA_ "GenSigTimeoutTime_ALL" SG_ 1337 SRR_RR_M_srcNodeID 2000;
BA_ "InvalidValue" SG_ 1337 SRR_RR_M_srcNodeID "FFh";
BA_ "GenSigTimeoutTime_ALL" SG_ 1337 SRR_RR_M_CtrlBitVector 2000;
BA_ "InvalidValue" SG_ 1337 SRR_RR_M_CtrlBitVector "0";
BA_ "GenSigTimeoutTime_ALL" SG_ 1337 SRR_RR_M_usrData0 2000;
BA_ "InvalidValue" SG_ 1337 SRR_RR_M_usrData0 "0";
BA_ "GenSigTimeoutTime_ALL" SG_ 1337 SRR_RR_M_usrData1 2000;
BA_ "InvalidValue" SG_ 1337 SRR_RR_M_usrData1 "0";
BA_ "GenSigTimeoutTime_ALL" SG_ 1337 SRR_RR_M_usrData2 2000;
BA_ "InvalidValue" SG_ 1337 SRR_RR_M_usrData2 "0";
BA_ "GenSigTimeoutTime_ALL" SG_ 1337 SRR_RR_M_usrData3 2000;
BA_ "InvalidValue" SG_ 1337 SRR_RR_M_usrData3 "0";
BA_ "GenSigTimeoutTime_ALL" SG_ 1337 SRR_RR_M_usrData4 2000;
BA_ "InvalidValue" SG_ 1337 SRR_RR_M_usrData4 "0";
BA_ "GenSigTimeoutTime_ALL" SG_ 1337 SRR_RR_M_usrData5 2000;
BA_ "InvalidValue" SG_ 1337 SRR_RR_M_usrData5 "0";
BA_ "GenSigTimeoutTime_ALL" SG_ 1345 APM_srcNodeID 2000;
BA_ "InvalidValue" SG_ 1345 APM_srcNodeID "null";
BA_ "GenSigTimeoutTime_ALL" SG_ 1345 APM_CtrlBitVector 2000;
BA_ "InvalidValue" SG_ 1345 APM_CtrlBitVector "null";
BA_ "GenSigStartValue" SG_ 1345 APM_usrData0 255;
BA_ "GenSigTimeoutTime_ALL" SG_ 1345 APM_usrData0 2000;
BA_ "InvalidValue" SG_ 1345 APM_usrData0 "null";
BA_ "GenSigStartValue" SG_ 1345 APM_usrData1 255;
BA_ "GenSigTimeoutTime_ALL" SG_ 1345 APM_usrData1 2000;
BA_ "InvalidValue" SG_ 1345 APM_usrData1 "null";
BA_ "GenSigStartValue" SG_ 1345 APM_usrData2 255;
BA_ "GenSigTimeoutTime_ALL" SG_ 1345 APM_usrData2 2000;
BA_ "InvalidValue" SG_ 1345 APM_usrData2 "null";
BA_ "GenSigStartValue" SG_ 1345 APM_usrData3 255;
BA_ "GenSigTimeoutTime_ALL" SG_ 1345 APM_usrData3 2000;
BA_ "InvalidValue" SG_ 1345 APM_usrData3 "null";
BA_ "GenSigStartValue" SG_ 1345 APM_usrData4 255;
BA_ "GenSigTimeoutTime_ALL" SG_ 1345 APM_usrData4 2000;
BA_ "InvalidValue" SG_ 1345 APM_usrData4 "null";
BA_ "GenSigStartValue" SG_ 1345 APM_usrData5 255;
BA_ "GenSigTimeoutTime_ALL" SG_ 1345 APM_usrData5 2000;
BA_ "InvalidValue" SG_ 1345 APM_usrData5 "null";
BA_ "GenSigTimeoutTime_ALL" SG_ 1353 LDM_L_srcNodeID 2000;
BA_ "InvalidValue" SG_ 1353 LDM_L_srcNodeID "null";
BA_ "GenSigTimeoutTime_ALL" SG_ 1353 LDM_L_CtrlBitVector 2000;
BA_ "InvalidValue" SG_ 1353 LDM_L_CtrlBitVector "null";
BA_ "GenSigTimeoutTime_ALL" SG_ 1353 LDM_L_usrData0 2000;
BA_ "InvalidValue" SG_ 1353 LDM_L_usrData0 "null";
BA_ "GenSigTimeoutTime_ALL" SG_ 1353 LDM_L_usrData1 2000;
BA_ "InvalidValue" SG_ 1353 LDM_L_usrData1 "null";
BA_ "GenSigTimeoutTime_ALL" SG_ 1353 LDM_L_usrData2 2000;
BA_ "InvalidValue" SG_ 1353 LDM_L_usrData2 "null";
BA_ "GenSigTimeoutTime_ALL" SG_ 1353 LDM_L_usrData3 2000;
BA_ "InvalidValue" SG_ 1353 LDM_L_usrData3 "null";
BA_ "GenSigTimeoutTime_ALL" SG_ 1353 LDM_L_usrData4 2000;
BA_ "InvalidValue" SG_ 1353 LDM_L_usrData4 "null";
BA_ "GenSigTimeoutTime_ALL" SG_ 1353 LDM_L_usrData5 2000;
BA_ "InvalidValue" SG_ 1353 LDM_L_usrData5 "null";
BA_ "GenSigTimeoutTime_ALL" SG_ 1354 LDM_R_srcNodeID 2000;
BA_ "InvalidValue" SG_ 1354 LDM_R_srcNodeID "null";
BA_ "GenSigTimeoutTime_ALL" SG_ 1354 LDM_R_CtrlBitVector 2000;
BA_ "InvalidValue" SG_ 1354 LDM_R_CtrlBitVector "null";
BA_ "GenSigTimeoutTime_ALL" SG_ 1354 LDM_R_usrData0 2000;
BA_ "InvalidValue" SG_ 1354 LDM_R_usrData0 "null";
BA_ "GenSigTimeoutTime_ALL" SG_ 1354 LDM_R_usrData1 2000;
BA_ "InvalidValue" SG_ 1354 LDM_R_usrData1 "null";
BA_ "GenSigTimeoutTime_ALL" SG_ 1354 LDM_R_usrData2 2000;
BA_ "InvalidValue" SG_ 1354 LDM_R_usrData2 "null";
BA_ "GenSigTimeoutTime_ALL" SG_ 1354 LDM_R_usrData3 2000;
BA_ "InvalidValue" SG_ 1354 LDM_R_usrData3 "null";
BA_ "GenSigTimeoutTime_ALL" SG_ 1354 LDM_R_usrData4 2000;
BA_ "InvalidValue" SG_ 1354 LDM_R_usrData4 "null";
BA_ "GenSigTimeoutTime_ALL" SG_ 1354 LDM_R_usrData5 2000;
BA_ "InvalidValue" SG_ 1354 LDM_R_usrData5 "null";
BA_ "GenSigTimeoutTime_ALL" SG_ 1360 CCUR_srcNodeID 2000;
BA_ "InvalidValue" SG_ 1360 CCUR_srcNodeID "null";
BA_ "GenSigTimeoutTime_ALL" SG_ 1360 CCUR_CtrlBitVector 2000;
BA_ "InvalidValue" SG_ 1360 CCUR_CtrlBitVector "null";
BA_ "GenSigStartValue" SG_ 1360 CCUR_usrData0 255;
BA_ "GenSigTimeoutTime_ALL" SG_ 1360 CCUR_usrData0 2000;
BA_ "InvalidValue" SG_ 1360 CCUR_usrData0 "null";
BA_ "GenSigStartValue" SG_ 1360 CCUR_usrData1 255;
BA_ "GenSigTimeoutTime_ALL" SG_ 1360 CCUR_usrData1 2000;
BA_ "InvalidValue" SG_ 1360 CCUR_usrData1 "null";
BA_ "GenSigStartValue" SG_ 1360 CCUR_usrData2 255;
BA_ "GenSigTimeoutTime_ALL" SG_ 1360 CCUR_usrData2 2000;
BA_ "InvalidValue" SG_ 1360 CCUR_usrData2 "null";
BA_ "GenSigStartValue" SG_ 1360 CCUR_usrData3 255;
BA_ "GenSigTimeoutTime_ALL" SG_ 1360 CCUR_usrData3 2000;
BA_ "InvalidValue" SG_ 1360 CCUR_usrData3 "null";
BA_ "GenSigStartValue" SG_ 1360 CCUR_usrData4 255;
BA_ "GenSigTimeoutTime_ALL" SG_ 1360 CCUR_usrData4 2000;
BA_ "InvalidValue" SG_ 1360 CCUR_usrData4 "null";
BA_ "GenSigStartValue" SG_ 1360 CCUR_usrData5 255;
BA_ "GenSigTimeoutTime_ALL" SG_ 1360 CCUR_usrData5 2000;
BA_ "InvalidValue" SG_ 1360 CCUR_usrData5 "null";
BA_ "GenSigSendType" SG_ 1537 BCM_DiagRespData0 7;
BA_ "InvalidValue" SG_ 1537 BCM_DiagRespData0 "null";
BA_ "GenSigSendType" SG_ 1537 BCM_DiagRespData1 7;
BA_ "InvalidValue" SG_ 1537 BCM_DiagRespData1 "null";
BA_ "GenSigSendType" SG_ 1537 BCM_DiagRespData2 7;
BA_ "InvalidValue" SG_ 1537 BCM_DiagRespData2 "null";
BA_ "GenSigSendType" SG_ 1537 BCM_DiagRespData3 7;
BA_ "InvalidValue" SG_ 1537 BCM_DiagRespData3 "null";
BA_ "GenSigSendType" SG_ 1537 BCM_DiagRespData4 7;
BA_ "InvalidValue" SG_ 1537 BCM_DiagRespData4 "null";
BA_ "GenSigSendType" SG_ 1537 BCM_DiagRespData5 7;
BA_ "InvalidValue" SG_ 1537 BCM_DiagRespData5 "null";
BA_ "GenSigSendType" SG_ 1537 BCM_DiagRespData6 7;
BA_ "InvalidValue" SG_ 1537 BCM_DiagRespData6 "null";
BA_ "GenSigSendType" SG_ 1537 BCM_DiagRespData7 7;
BA_ "InvalidValue" SG_ 1537 BCM_DiagRespData7 "null";
BA_ "GenSigSendType" SG_ 1544 ACM_DiagRespData0 7;
BA_ "InvalidValue" SG_ 1544 ACM_DiagRespData0 "null";
BA_ "GenSigSendType" SG_ 1544 ACM_DiagRespData1 7;
BA_ "InvalidValue" SG_ 1544 ACM_DiagRespData1 "null";
BA_ "GenSigSendType" SG_ 1544 ACM_DiagRespData2 7;
BA_ "InvalidValue" SG_ 1544 ACM_DiagRespData2 "null";
BA_ "GenSigSendType" SG_ 1544 ACM_DiagRespData3 7;
BA_ "InvalidValue" SG_ 1544 ACM_DiagRespData3 "null";
BA_ "GenSigSendType" SG_ 1544 ACM_DiagRespData4 7;
BA_ "InvalidValue" SG_ 1544 ACM_DiagRespData4 "null";
BA_ "GenSigSendType" SG_ 1544 ACM_DiagRespData5 7;
BA_ "InvalidValue" SG_ 1544 ACM_DiagRespData5 "null";
BA_ "GenSigSendType" SG_ 1544 ACM_DiagRespData6 7;
BA_ "InvalidValue" SG_ 1544 ACM_DiagRespData6 "null";
BA_ "GenSigSendType" SG_ 1544 ACM_DiagRespData7 7;
BA_ "InvalidValue" SG_ 1544 ACM_DiagRespData7 "null";
BA_ "GenSigSendType" SG_ 1545 CCUF_DiagRespData0 7;
BA_ "InvalidValue" SG_ 1545 CCUF_DiagRespData0 "null";
BA_ "GenSigSendType" SG_ 1545 CCUF_DiagRespData1 7;
BA_ "InvalidValue" SG_ 1545 CCUF_DiagRespData1 "null";
BA_ "GenSigSendType" SG_ 1545 CCUF_DiagRespData2 7;
BA_ "InvalidValue" SG_ 1545 CCUF_DiagRespData2 "null";
BA_ "GenSigSendType" SG_ 1545 CCUF_DiagRespData3 7;
BA_ "InvalidValue" SG_ 1545 CCUF_DiagRespData3 "null";
BA_ "GenSigSendType" SG_ 1545 CCUF_DiagRespData4 7;
BA_ "InvalidValue" SG_ 1545 CCUF_DiagRespData4 "null";
BA_ "GenSigSendType" SG_ 1545 CCUF_DiagRespData5 7;
BA_ "InvalidValue" SG_ 1545 CCUF_DiagRespData5 "null";
BA_ "GenSigSendType" SG_ 1545 CCUF_DiagRespData6 7;
BA_ "InvalidValue" SG_ 1545 CCUF_DiagRespData6 "null";
BA_ "GenSigSendType" SG_ 1545 CCUF_DiagRespData7 7;
BA_ "InvalidValue" SG_ 1545 CCUF_DiagRespData7 "null";
BA_ "GenSigSendType" SG_ 1550 ETG_DiagRespData0 7;
BA_ "InvalidValue" SG_ 1550 ETG_DiagRespData0 "null";
BA_ "GenSigSendType" SG_ 1550 ETG_DiagRespData1 7;
BA_ "InvalidValue" SG_ 1550 ETG_DiagRespData1 "null";
BA_ "GenSigSendType" SG_ 1550 ETG_DiagRespData2 7;
BA_ "InvalidValue" SG_ 1550 ETG_DiagRespData2 "null";
BA_ "GenSigSendType" SG_ 1550 ETG_DiagRespData3 7;
BA_ "InvalidValue" SG_ 1550 ETG_DiagRespData3 "null";
BA_ "GenSigSendType" SG_ 1550 ETG_DiagRespData4 7;
BA_ "InvalidValue" SG_ 1550 ETG_DiagRespData4 "null";
BA_ "GenSigSendType" SG_ 1550 ETG_DiagRespData5 7;
BA_ "InvalidValue" SG_ 1550 ETG_DiagRespData5 "null";
BA_ "GenSigSendType" SG_ 1550 ETG_DiagRespData6 7;
BA_ "InvalidValue" SG_ 1550 ETG_DiagRespData6 "null";
BA_ "GenSigSendType" SG_ 1550 ETG_DiagRespData7 7;
BA_ "InvalidValue" SG_ 1550 ETG_DiagRespData7 "null";
BA_ "GenSigSendType" SG_ 1553 ASU_Gateway_DiagRespData0 7;
BA_ "InvalidValue" SG_ 1553 ASU_Gateway_DiagRespData0 "null";
BA_ "GenSigSendType" SG_ 1553 ASU_Gateway_DiagRespData1 7;
BA_ "InvalidValue" SG_ 1553 ASU_Gateway_DiagRespData1 "null";
BA_ "GenSigSendType" SG_ 1553 ASU_Gateway_DiagRespData2 7;
BA_ "InvalidValue" SG_ 1553 ASU_Gateway_DiagRespData2 "null";
BA_ "GenSigSendType" SG_ 1553 ASU_Gateway_DiagRespData3 7;
BA_ "InvalidValue" SG_ 1553 ASU_Gateway_DiagRespData3 "null";
BA_ "GenSigSendType" SG_ 1553 ASU_Gateway_DiagRespData4 7;
BA_ "InvalidValue" SG_ 1553 ASU_Gateway_DiagRespData4 "null";
BA_ "GenSigSendType" SG_ 1553 ASU_Gateway_DiagRespData5 7;
BA_ "InvalidValue" SG_ 1553 ASU_Gateway_DiagRespData5 "null";
BA_ "GenSigSendType" SG_ 1553 ASU_Gateway_DiagRespData6 7;
BA_ "InvalidValue" SG_ 1553 ASU_Gateway_DiagRespData6 "null";
BA_ "GenSigSendType" SG_ 1553 ASU_Gateway_DiagRespData7 7;
BA_ "InvalidValue" SG_ 1553 ASU_Gateway_DiagRespData7 "null";
BA_ "GenSigSendType" SG_ 1556 CCUR_DiagRespData0 7;
BA_ "InvalidValue" SG_ 1556 CCUR_DiagRespData0 "null";
BA_ "GenSigSendType" SG_ 1556 CCUR_DiagRespData1 7;
BA_ "InvalidValue" SG_ 1556 CCUR_DiagRespData1 "null";
BA_ "GenSigSendType" SG_ 1556 CCUR_DiagRespData2 7;
BA_ "InvalidValue" SG_ 1556 CCUR_DiagRespData2 "null";
BA_ "GenSigSendType" SG_ 1556 CCUR_DiagRespData3 7;
BA_ "InvalidValue" SG_ 1556 CCUR_DiagRespData3 "null";
BA_ "GenSigSendType" SG_ 1556 CCUR_DiagRespData4 7;
BA_ "InvalidValue" SG_ 1556 CCUR_DiagRespData4 "null";
BA_ "GenSigSendType" SG_ 1556 CCUR_DiagRespData5 7;
BA_ "InvalidValue" SG_ 1556 CCUR_DiagRespData5 "null";
BA_ "GenSigSendType" SG_ 1556 CCUR_DiagRespData6 7;
BA_ "InvalidValue" SG_ 1556 CCUR_DiagRespData6 "null";
BA_ "GenSigSendType" SG_ 1556 CCUR_DiagRespData7 7;
BA_ "InvalidValue" SG_ 1556 CCUR_DiagRespData7 "null";
BA_ "GenSigSendType" SG_ 1566 PSM_D_DiagRespData0 7;
BA_ "InvalidValue" SG_ 1566 PSM_D_DiagRespData0 "null";
BA_ "GenSigSendType" SG_ 1566 PSM_D_DiagRespData1 7;
BA_ "InvalidValue" SG_ 1566 PSM_D_DiagRespData1 "null";
BA_ "GenSigSendType" SG_ 1566 PSM_D_DiagRespData2 7;
BA_ "InvalidValue" SG_ 1566 PSM_D_DiagRespData2 "null";
BA_ "GenSigSendType" SG_ 1566 PSM_D_DiagRespData3 7;
BA_ "InvalidValue" SG_ 1566 PSM_D_DiagRespData3 "null";
BA_ "GenSigSendType" SG_ 1566 PSM_D_DiagRespData4 7;
BA_ "InvalidValue" SG_ 1566 PSM_D_DiagRespData4 "null";
BA_ "GenSigSendType" SG_ 1566 PSM_D_DiagRespData5 7;
BA_ "InvalidValue" SG_ 1566 PSM_D_DiagRespData5 "null";
BA_ "GenSigSendType" SG_ 1566 PSM_D_DiagRespData6 7;
BA_ "InvalidValue" SG_ 1566 PSM_D_DiagRespData6 "null";
BA_ "GenSigSendType" SG_ 1566 PSM_D_DiagRespData7 7;
BA_ "InvalidValue" SG_ 1566 PSM_D_DiagRespData7 "null";
BA_ "GenSigSendType" SG_ 1585 USS_R_DiagRespData0 7;
BA_ "InvalidValue" SG_ 1585 USS_R_DiagRespData0 "null";
BA_ "GenSigSendType" SG_ 1585 USS_R_DiagRespData1 7;
BA_ "InvalidValue" SG_ 1585 USS_R_DiagRespData1 "null";
BA_ "GenSigSendType" SG_ 1585 USS_R_DiagRespData2 7;
BA_ "InvalidValue" SG_ 1585 USS_R_DiagRespData2 "null";
BA_ "GenSigSendType" SG_ 1585 USS_R_DiagRespData3 7;
BA_ "InvalidValue" SG_ 1585 USS_R_DiagRespData3 "null";
BA_ "GenSigSendType" SG_ 1585 USS_R_DiagRespData4 7;
BA_ "InvalidValue" SG_ 1585 USS_R_DiagRespData4 "null";
BA_ "GenSigSendType" SG_ 1585 USS_R_DiagRespData5 7;
BA_ "InvalidValue" SG_ 1585 USS_R_DiagRespData5 "null";
BA_ "GenSigSendType" SG_ 1585 USS_R_DiagRespData6 7;
BA_ "InvalidValue" SG_ 1585 USS_R_DiagRespData6 "null";
BA_ "GenSigSendType" SG_ 1585 USS_R_DiagRespData7 7;
BA_ "InvalidValue" SG_ 1585 USS_R_DiagRespData7 "null";
BA_ "GenSigSendType" SG_ 1586 USS_F_DiagRespData0 7;
BA_ "InvalidValue" SG_ 1586 USS_F_DiagRespData0 "null";
BA_ "GenSigSendType" SG_ 1586 USS_F_DiagRespData1 7;
BA_ "InvalidValue" SG_ 1586 USS_F_DiagRespData1 "null";
BA_ "GenSigSendType" SG_ 1586 USS_F_DiagRespData2 7;
BA_ "InvalidValue" SG_ 1586 USS_F_DiagRespData2 "null";
BA_ "GenSigSendType" SG_ 1586 USS_F_DiagRespData3 7;
BA_ "InvalidValue" SG_ 1586 USS_F_DiagRespData3 "null";
BA_ "GenSigSendType" SG_ 1586 USS_F_DiagRespData4 7;
BA_ "InvalidValue" SG_ 1586 USS_F_DiagRespData4 "null";
BA_ "GenSigSendType" SG_ 1586 USS_F_DiagRespData5 7;
BA_ "InvalidValue" SG_ 1586 USS_F_DiagRespData5 "null";
BA_ "GenSigSendType" SG_ 1586 USS_F_DiagRespData6 7;
BA_ "InvalidValue" SG_ 1586 USS_F_DiagRespData6 "null";
BA_ "GenSigSendType" SG_ 1586 USS_F_DiagRespData7 7;
BA_ "InvalidValue" SG_ 1586 USS_F_DiagRespData7 "null";
BA_ "GenSigSendType" SG_ 1592 ASU_DiagRespData0 7;
BA_ "GenSigSendType" SG_ 1592 ASU_DiagRespData1 7;
BA_ "GenSigSendType" SG_ 1592 ASU_DiagRespData2 7;
BA_ "GenSigSendType" SG_ 1592 ASU_DiagRespData3 7;
BA_ "GenSigSendType" SG_ 1592 ASU_DiagRespData4 7;
BA_ "GenSigSendType" SG_ 1592 ASU_DiagRespData5 7;
BA_ "GenSigSendType" SG_ 1592 ASU_DiagRespData6 7;
BA_ "GenSigSendType" SG_ 1592 ASU_DiagRespData7 7;
BA_ "GenSigSendType" SG_ 1593 SRR_RR_M_DiagResp_Data0 7;
BA_ "InvalidValue" SG_ 1593 SRR_RR_M_DiagResp_Data0 "0";
BA_ "GenSigSendType" SG_ 1593 SRR_RR_M_DiagResp_Data1 7;
BA_ "InvalidValue" SG_ 1593 SRR_RR_M_DiagResp_Data1 "0";
BA_ "GenSigSendType" SG_ 1593 SRR_RR_M_DiagResp_Data2 7;
BA_ "InvalidValue" SG_ 1593 SRR_RR_M_DiagResp_Data2 "0";
BA_ "GenSigSendType" SG_ 1593 SRR_RR_M_DiagResp_Data3 7;
BA_ "InvalidValue" SG_ 1593 SRR_RR_M_DiagResp_Data3 "0";
BA_ "GenSigSendType" SG_ 1593 SRR_RR_M_DiagResp_Data4 7;
BA_ "InvalidValue" SG_ 1593 SRR_RR_M_DiagResp_Data4 "0";
BA_ "GenSigSendType" SG_ 1593 SRR_RR_M_DiagResp_Data5 7;
BA_ "InvalidValue" SG_ 1593 SRR_RR_M_DiagResp_Data5 "0";
BA_ "GenSigSendType" SG_ 1593 SRR_RR_M_DiagResp_Data6 7;
BA_ "InvalidValue" SG_ 1593 SRR_RR_M_DiagResp_Data6 "0";
BA_ "GenSigSendType" SG_ 1593 SRR_RR_M_DiagResp_Data7 7;
BA_ "InvalidValue" SG_ 1593 SRR_RR_M_DiagResp_Data7 "0";
BA_ "GenSigSendType" SG_ 1595 TRM_DiagRespData0 7;
BA_ "InvalidValue" SG_ 1595 TRM_DiagRespData0 "null";
BA_ "GenSigSendType" SG_ 1595 TRM_DiagRespData1 7;
BA_ "InvalidValue" SG_ 1595 TRM_DiagRespData1 "null";
BA_ "GenSigSendType" SG_ 1595 TRM_DiagRespData2 7;
BA_ "InvalidValue" SG_ 1595 TRM_DiagRespData2 "null";
BA_ "GenSigSendType" SG_ 1595 TRM_DiagRespData3 7;
BA_ "InvalidValue" SG_ 1595 TRM_DiagRespData3 "null";
BA_ "GenSigSendType" SG_ 1595 TRM_DiagRespData4 7;
BA_ "InvalidValue" SG_ 1595 TRM_DiagRespData4 "null";
BA_ "GenSigSendType" SG_ 1595 TRM_DiagRespData5 7;
BA_ "InvalidValue" SG_ 1595 TRM_DiagRespData5 "null";
BA_ "GenSigSendType" SG_ 1595 TRM_DiagRespData6 7;
BA_ "InvalidValue" SG_ 1595 TRM_DiagRespData6 "null";
BA_ "GenSigSendType" SG_ 1595 TRM_DiagRespData7 7;
BA_ "InvalidValue" SG_ 1595 TRM_DiagRespData7 "null";
BA_ "GenSigSendType" SG_ 1601 APM_DiagRespData0 7;
BA_ "InvalidValue" SG_ 1601 APM_DiagRespData0 "null";
BA_ "GenSigSendType" SG_ 1601 APM_DiagRespData1 7;
BA_ "InvalidValue" SG_ 1601 APM_DiagRespData1 "null";
BA_ "GenSigSendType" SG_ 1601 APM_DiagRespData2 7;
BA_ "InvalidValue" SG_ 1601 APM_DiagRespData2 "null";
BA_ "GenSigSendType" SG_ 1601 APM_DiagRespData3 7;
BA_ "InvalidValue" SG_ 1601 APM_DiagRespData3 "null";
BA_ "GenSigSendType" SG_ 1601 APM_DiagRespData4 7;
BA_ "InvalidValue" SG_ 1601 APM_DiagRespData4 "null";
BA_ "GenSigSendType" SG_ 1601 APM_DiagRespData5 7;
BA_ "InvalidValue" SG_ 1601 APM_DiagRespData5 "null";
BA_ "GenSigSendType" SG_ 1601 APM_DiagRespData6 7;
BA_ "InvalidValue" SG_ 1601 APM_DiagRespData6 "null";
BA_ "GenSigSendType" SG_ 1601 APM_DiagRespData7 7;
BA_ "InvalidValue" SG_ 1601 APM_DiagRespData7 "null";
BA_ "GenSigSendType" SG_ 1602 SHVU_F_DiagRespData0 7;
BA_ "InvalidValue" SG_ 1602 SHVU_F_DiagRespData0 "null";
BA_ "GenSigSendType" SG_ 1602 SHVU_F_DiagRespData1 7;
BA_ "InvalidValue" SG_ 1602 SHVU_F_DiagRespData1 "null";
BA_ "GenSigSendType" SG_ 1602 SHVU_F_DiagRespData2 7;
BA_ "InvalidValue" SG_ 1602 SHVU_F_DiagRespData2 "null";
BA_ "GenSigSendType" SG_ 1602 SHVU_F_DiagRespData3 7;
BA_ "InvalidValue" SG_ 1602 SHVU_F_DiagRespData3 "null";
BA_ "GenSigSendType" SG_ 1602 SHVU_F_DiagRespData4 7;
BA_ "InvalidValue" SG_ 1602 SHVU_F_DiagRespData4 "null";
BA_ "GenSigSendType" SG_ 1602 SHVU_F_DiagRespData5 7;
BA_ "InvalidValue" SG_ 1602 SHVU_F_DiagRespData5 "null";
BA_ "GenSigSendType" SG_ 1602 SHVU_F_DiagRespData6 7;
BA_ "InvalidValue" SG_ 1602 SHVU_F_DiagRespData6 "null";
BA_ "GenSigSendType" SG_ 1602 SHVU_F_DiagRespData7 7;
BA_ "InvalidValue" SG_ 1602 SHVU_F_DiagRespData7 "null";
BA_ "GenSigSendType" SG_ 1603 SHVU_R_DiagRespData0 7;
BA_ "InvalidValue" SG_ 1603 SHVU_R_DiagRespData0 "null";
BA_ "GenSigSendType" SG_ 1603 SHVU_R_DiagRespData1 7;
BA_ "InvalidValue" SG_ 1603 SHVU_R_DiagRespData1 "null";
BA_ "GenSigSendType" SG_ 1603 SHVU_R_DiagRespData2 7;
BA_ "InvalidValue" SG_ 1603 SHVU_R_DiagRespData2 "null";
BA_ "GenSigSendType" SG_ 1603 SHVU_R_DiagRespData3 7;
BA_ "InvalidValue" SG_ 1603 SHVU_R_DiagRespData3 "null";
BA_ "GenSigSendType" SG_ 1603 SHVU_R_DiagRespData4 7;
BA_ "InvalidValue" SG_ 1603 SHVU_R_DiagRespData4 "null";
BA_ "GenSigSendType" SG_ 1603 SHVU_R_DiagRespData5 7;
BA_ "InvalidValue" SG_ 1603 SHVU_R_DiagRespData5 "null";
BA_ "GenSigSendType" SG_ 1603 SHVU_R_DiagRespData6 7;
BA_ "InvalidValue" SG_ 1603 SHVU_R_DiagRespData6 "null";
BA_ "GenSigSendType" SG_ 1603 SHVU_R_DiagRespData7 7;
BA_ "InvalidValue" SG_ 1603 SHVU_R_DiagRespData7 "null";
BA_ "GenSigSendType" SG_ 1604 OCS_P_DiagRespData0 7;
BA_ "InvalidValue" SG_ 1604 OCS_P_DiagRespData0 "null";
BA_ "GenSigSendType" SG_ 1604 OCS_P_DiagRespData1 7;
BA_ "InvalidValue" SG_ 1604 OCS_P_DiagRespData1 "null";
BA_ "GenSigSendType" SG_ 1604 OCS_P_DiagRespData2 7;
BA_ "InvalidValue" SG_ 1604 OCS_P_DiagRespData2 "null";
BA_ "GenSigSendType" SG_ 1604 OCS_P_DiagRespData3 7;
BA_ "InvalidValue" SG_ 1604 OCS_P_DiagRespData3 "null";
BA_ "GenSigSendType" SG_ 1604 OCS_P_DiagRespData4 7;
BA_ "InvalidValue" SG_ 1604 OCS_P_DiagRespData4 "null";
BA_ "GenSigSendType" SG_ 1604 OCS_P_DiagRespData5 7;
BA_ "InvalidValue" SG_ 1604 OCS_P_DiagRespData5 "null";
BA_ "GenSigSendType" SG_ 1604 OCS_P_DiagRespData6 7;
BA_ "InvalidValue" SG_ 1604 OCS_P_DiagRespData6 "null";
BA_ "GenSigSendType" SG_ 1604 OCS_P_DiagRespData7 7;
BA_ "InvalidValue" SG_ 1604 OCS_P_DiagRespData7 "null";
BA_ "GenSigSendType" SG_ 1609 LDM_L_DiagRespData0 7;
BA_ "InvalidValue" SG_ 1609 LDM_L_DiagRespData0 "null";
BA_ "GenSigSendType" SG_ 1609 LDM_L_DiagRespData1 7;
BA_ "InvalidValue" SG_ 1609 LDM_L_DiagRespData1 "null";
BA_ "GenSigSendType" SG_ 1609 LDM_L_DiagRespData2 7;
BA_ "InvalidValue" SG_ 1609 LDM_L_DiagRespData2 "null";
BA_ "GenSigSendType" SG_ 1609 LDM_L_DiagRespData3 7;
BA_ "InvalidValue" SG_ 1609 LDM_L_DiagRespData3 "null";
BA_ "GenSigSendType" SG_ 1609 LDM_L_DiagRespData4 7;
BA_ "InvalidValue" SG_ 1609 LDM_L_DiagRespData4 "null";
BA_ "GenSigSendType" SG_ 1609 LDM_L_DiagRespData5 7;
BA_ "InvalidValue" SG_ 1609 LDM_L_DiagRespData5 "null";
BA_ "GenSigSendType" SG_ 1609 LDM_L_DiagRespData6 7;
BA_ "InvalidValue" SG_ 1609 LDM_L_DiagRespData6 "null";
BA_ "GenSigSendType" SG_ 1609 LDM_L_DiagRespData7 7;
BA_ "InvalidValue" SG_ 1609 LDM_L_DiagRespData7 "null";
BA_ "GenSigSendType" SG_ 1610 LDM_R_DiagRespData0 7;
BA_ "InvalidValue" SG_ 1610 LDM_R_DiagRespData0 "null";
BA_ "GenSigSendType" SG_ 1610 LDM_R_DiagRespData1 7;
BA_ "InvalidValue" SG_ 1610 LDM_R_DiagRespData1 "null";
BA_ "GenSigSendType" SG_ 1610 LDM_R_DiagRespData2 7;
BA_ "InvalidValue" SG_ 1610 LDM_R_DiagRespData2 "null";
BA_ "GenSigSendType" SG_ 1610 LDM_R_DiagRespData3 7;
BA_ "InvalidValue" SG_ 1610 LDM_R_DiagRespData3 "null";
BA_ "GenSigSendType" SG_ 1610 LDM_R_DiagRespData4 7;
BA_ "InvalidValue" SG_ 1610 LDM_R_DiagRespData4 "null";
BA_ "GenSigSendType" SG_ 1610 LDM_R_DiagRespData5 7;
BA_ "InvalidValue" SG_ 1610 LDM_R_DiagRespData5 "null";
BA_ "GenSigSendType" SG_ 1610 LDM_R_DiagRespData6 7;
BA_ "InvalidValue" SG_ 1610 LDM_R_DiagRespData6 "null";
BA_ "GenSigSendType" SG_ 1610 LDM_R_DiagRespData7 7;
BA_ "InvalidValue" SG_ 1610 LDM_R_DiagRespData7 "null";
BA_ "GenSigSendType" SG_ 1624 BAS_DiagRespData0 7;
BA_ "InvalidValue" SG_ 1624 BAS_DiagRespData0 "null";
BA_ "GenSigSendType" SG_ 1624 BAS_DiagRespData1 7;
BA_ "InvalidValue" SG_ 1624 BAS_DiagRespData1 "null";
BA_ "GenSigSendType" SG_ 1624 BAS_DiagRespData2 7;
BA_ "InvalidValue" SG_ 1624 BAS_DiagRespData2 "null";
BA_ "GenSigSendType" SG_ 1624 BAS_DiagRespData3 7;
BA_ "InvalidValue" SG_ 1624 BAS_DiagRespData3 "null";
BA_ "GenSigSendType" SG_ 1624 BAS_DiagRespData4 7;
BA_ "InvalidValue" SG_ 1624 BAS_DiagRespData4 "null";
BA_ "GenSigSendType" SG_ 1624 BAS_DiagRespData5 7;
BA_ "InvalidValue" SG_ 1624 BAS_DiagRespData5 "null";
BA_ "GenSigSendType" SG_ 1624 BAS_DiagRespData6 7;
BA_ "InvalidValue" SG_ 1624 BAS_DiagRespData6 "null";
BA_ "GenSigSendType" SG_ 1624 BAS_DiagRespData7 7;
BA_ "InvalidValue" SG_ 1624 BAS_DiagRespData7 "null";
BA_ "GenSigSendType" SG_ 1636 DCM_APM_DiagRespData0 7;
BA_ "InvalidValue" SG_ 1636 DCM_APM_DiagRespData0 "null";
BA_ "GenSigSendType" SG_ 1636 DCM_APM_DiagRespData1 7;
BA_ "InvalidValue" SG_ 1636 DCM_APM_DiagRespData1 "null";
BA_ "GenSigSendType" SG_ 1636 DCM_APM_DiagRespData2 7;
BA_ "InvalidValue" SG_ 1636 DCM_APM_DiagRespData2 "null";
BA_ "GenSigSendType" SG_ 1636 DCM_APM_DiagRespData3 7;
BA_ "InvalidValue" SG_ 1636 DCM_APM_DiagRespData3 "null";
BA_ "GenSigSendType" SG_ 1636 DCM_APM_DiagRespData4 7;
BA_ "InvalidValue" SG_ 1636 DCM_APM_DiagRespData4 "null";
BA_ "GenSigSendType" SG_ 1636 DCM_APM_DiagRespData5 7;
BA_ "InvalidValue" SG_ 1636 DCM_APM_DiagRespData5 "null";
BA_ "GenSigSendType" SG_ 1636 DCM_APM_DiagRespData6 7;
BA_ "InvalidValue" SG_ 1636 DCM_APM_DiagRespData6 "null";
BA_ "GenSigSendType" SG_ 1636 DCM_APM_DiagRespData7 7;
BA_ "InvalidValue" SG_ 1636 DCM_APM_DiagRespData7 "null";
BA_ "GenSigSendType" SG_ 1659 BCM_BPM_DiagRespData0 7;
BA_ "InvalidValue" SG_ 1659 BCM_BPM_DiagRespData0 "null";
BA_ "GenSigSendType" SG_ 1659 BCM_BPM_DiagRespData1 7;
BA_ "InvalidValue" SG_ 1659 BCM_BPM_DiagRespData1 "null";
BA_ "GenSigSendType" SG_ 1659 BCM_BPM_DiagRespData2 7;
BA_ "InvalidValue" SG_ 1659 BCM_BPM_DiagRespData2 "null";
BA_ "GenSigSendType" SG_ 1659 BCM_BPM_DiagRespData3 7;
BA_ "InvalidValue" SG_ 1659 BCM_BPM_DiagRespData3 "null";
BA_ "GenSigSendType" SG_ 1659 BCM_BPM_DiagRespData4 7;
BA_ "InvalidValue" SG_ 1659 BCM_BPM_DiagRespData4 "null";
BA_ "GenSigSendType" SG_ 1659 BCM_BPM_DiagRespData5 7;
BA_ "InvalidValue" SG_ 1659 BCM_BPM_DiagRespData5 "null";
BA_ "GenSigSendType" SG_ 1659 BCM_BPM_DiagRespData6 7;
BA_ "InvalidValue" SG_ 1659 BCM_BPM_DiagRespData6 "null";
BA_ "GenSigSendType" SG_ 1659 BCM_BPM_DiagRespData7 7;
BA_ "InvalidValue" SG_ 1659 BCM_BPM_DiagRespData7 "null";
BA_ "GenSigSendType" SG_ 1665 BCM_DiagReqData0 7;
BA_ "InvalidValue" SG_ 1665 BCM_DiagReqData0 "null";
BA_ "GenSigSendType" SG_ 1665 BCM_DiagReqData1 7;
BA_ "InvalidValue" SG_ 1665 BCM_DiagReqData1 "null";
BA_ "GenSigSendType" SG_ 1665 BCM_DiagReqData2 7;
BA_ "InvalidValue" SG_ 1665 BCM_DiagReqData2 "null";
BA_ "GenSigSendType" SG_ 1665 BCM_DiagReqData3 7;
BA_ "InvalidValue" SG_ 1665 BCM_DiagReqData3 "null";
BA_ "GenSigSendType" SG_ 1665 BCM_DiagReqData4 7;
BA_ "InvalidValue" SG_ 1665 BCM_DiagReqData4 "null";
BA_ "GenSigSendType" SG_ 1665 BCM_DiagReqData5 7;
BA_ "InvalidValue" SG_ 1665 BCM_DiagReqData5 "null";
BA_ "GenSigSendType" SG_ 1665 BCM_DiagReqData6 7;
BA_ "InvalidValue" SG_ 1665 BCM_DiagReqData6 "null";
BA_ "GenSigSendType" SG_ 1665 BCM_DiagReqData7 7;
BA_ "InvalidValue" SG_ 1665 BCM_DiagReqData7 "null";
BA_ "GenSigSendType" SG_ 1672 ACM_DiagReqData0 7;
BA_ "InvalidValue" SG_ 1672 ACM_DiagReqData0 "null";
BA_ "GenSigSendType" SG_ 1672 ACM_DiagReqData1 7;
BA_ "InvalidValue" SG_ 1672 ACM_DiagReqData1 "null";
BA_ "GenSigSendType" SG_ 1672 ACM_DiagReqData2 7;
BA_ "InvalidValue" SG_ 1672 ACM_DiagReqData2 "null";
BA_ "GenSigSendType" SG_ 1672 ACM_DiagReqData3 7;
BA_ "InvalidValue" SG_ 1672 ACM_DiagReqData3 "null";
BA_ "GenSigSendType" SG_ 1672 ACM_DiagReqData4 7;
BA_ "InvalidValue" SG_ 1672 ACM_DiagReqData4 "null";
BA_ "GenSigSendType" SG_ 1672 ACM_DiagReqData5 7;
BA_ "InvalidValue" SG_ 1672 ACM_DiagReqData5 "null";
BA_ "GenSigSendType" SG_ 1672 ACM_DiagReqData6 7;
BA_ "InvalidValue" SG_ 1672 ACM_DiagReqData6 "null";
BA_ "GenSigSendType" SG_ 1672 ACM_DiagReqData7 7;
BA_ "InvalidValue" SG_ 1672 ACM_DiagReqData7 "null";
BA_ "GenSigSendType" SG_ 1673 CCUF_DiagReqData0 7;
BA_ "InvalidValue" SG_ 1673 CCUF_DiagReqData0 "null";
BA_ "GenSigSendType" SG_ 1673 CCUF_DiagReqData1 7;
BA_ "InvalidValue" SG_ 1673 CCUF_DiagReqData1 "null";
BA_ "GenSigSendType" SG_ 1673 CCUF_DiagReqData2 7;
BA_ "InvalidValue" SG_ 1673 CCUF_DiagReqData2 "null";
BA_ "GenSigSendType" SG_ 1673 CCUF_DiagReqData3 7;
BA_ "InvalidValue" SG_ 1673 CCUF_DiagReqData3 "null";
BA_ "GenSigSendType" SG_ 1673 CCUF_DiagReqData4 7;
BA_ "InvalidValue" SG_ 1673 CCUF_DiagReqData4 "null";
BA_ "GenSigSendType" SG_ 1673 CCUF_DiagReqData5 7;
BA_ "InvalidValue" SG_ 1673 CCUF_DiagReqData5 "null";
BA_ "GenSigSendType" SG_ 1673 CCUF_DiagReqData6 7;
BA_ "InvalidValue" SG_ 1673 CCUF_DiagReqData6 "null";
BA_ "GenSigSendType" SG_ 1673 CCUF_DiagReqData7 7;
BA_ "InvalidValue" SG_ 1673 CCUF_DiagReqData7 "null";
BA_ "GenSigSendType" SG_ 1678 ETG_DiagReqData0 7;
BA_ "InvalidValue" SG_ 1678 ETG_DiagReqData0 "null";
BA_ "GenSigSendType" SG_ 1678 ETG_DiagReqData1 7;
BA_ "InvalidValue" SG_ 1678 ETG_DiagReqData1 "null";
BA_ "GenSigSendType" SG_ 1678 ETG_DiagReqData2 7;
BA_ "InvalidValue" SG_ 1678 ETG_DiagReqData2 "null";
BA_ "GenSigSendType" SG_ 1678 ETG_DiagReqData3 7;
BA_ "InvalidValue" SG_ 1678 ETG_DiagReqData3 "null";
BA_ "GenSigSendType" SG_ 1678 ETG_DiagReqData4 7;
BA_ "InvalidValue" SG_ 1678 ETG_DiagReqData4 "null";
BA_ "GenSigSendType" SG_ 1678 ETG_DiagReqData5 7;
BA_ "InvalidValue" SG_ 1678 ETG_DiagReqData5 "null";
BA_ "GenSigSendType" SG_ 1678 ETG_DiagReqData6 7;
BA_ "InvalidValue" SG_ 1678 ETG_DiagReqData6 "null";
BA_ "GenSigSendType" SG_ 1678 ETG_DiagReqData7 7;
BA_ "InvalidValue" SG_ 1678 ETG_DiagReqData7 "null";
BA_ "GenSigSendType" SG_ 1681 ASU_Gateway_DiagReqData0 7;
BA_ "InvalidValue" SG_ 1681 ASU_Gateway_DiagReqData0 "null";
BA_ "GenSigSendType" SG_ 1681 ASU_Gateway_DiagReqData1 7;
BA_ "InvalidValue" SG_ 1681 ASU_Gateway_DiagReqData1 "null";
BA_ "GenSigSendType" SG_ 1681 ASU_Gateway_DiagReqData2 7;
BA_ "InvalidValue" SG_ 1681 ASU_Gateway_DiagReqData2 "null";
BA_ "GenSigSendType" SG_ 1681 ASU_Gateway_DiagReqData3 7;
BA_ "InvalidValue" SG_ 1681 ASU_Gateway_DiagReqData3 "null";
BA_ "GenSigSendType" SG_ 1681 ASU_Gateway_DiagReqData4 7;
BA_ "InvalidValue" SG_ 1681 ASU_Gateway_DiagReqData4 "null";
BA_ "GenSigSendType" SG_ 1681 ASU_Gateway_DiagReqData5 7;
BA_ "InvalidValue" SG_ 1681 ASU_Gateway_DiagReqData5 "null";
BA_ "GenSigSendType" SG_ 1681 ASU_Gateway_DiagReqData6 7;
BA_ "InvalidValue" SG_ 1681 ASU_Gateway_DiagReqData6 "null";
BA_ "GenSigSendType" SG_ 1681 ASU_Gateway_DiagReqData7 7;
BA_ "InvalidValue" SG_ 1681 ASU_Gateway_DiagReqData7 "null";
BA_ "GenSigSendType" SG_ 1684 CCUR_DiagReqData0 7;
BA_ "InvalidValue" SG_ 1684 CCUR_DiagReqData0 "null";
BA_ "GenSigSendType" SG_ 1684 CCUR_DiagReqData1 7;
BA_ "InvalidValue" SG_ 1684 CCUR_DiagReqData1 "null";
BA_ "GenSigSendType" SG_ 1684 CCUR_DiagReqData2 7;
BA_ "InvalidValue" SG_ 1684 CCUR_DiagReqData2 "null";
BA_ "GenSigSendType" SG_ 1684 CCUR_DiagReqData3 7;
BA_ "InvalidValue" SG_ 1684 CCUR_DiagReqData3 "null";
BA_ "GenSigSendType" SG_ 1684 CCUR_DiagReqData4 7;
BA_ "InvalidValue" SG_ 1684 CCUR_DiagReqData4 "null";
BA_ "GenSigSendType" SG_ 1684 CCUR_DiagReqData5 7;
BA_ "InvalidValue" SG_ 1684 CCUR_DiagReqData5 "null";
BA_ "GenSigSendType" SG_ 1684 CCUR_DiagReqData6 7;
BA_ "InvalidValue" SG_ 1684 CCUR_DiagReqData6 "null";
BA_ "GenSigSendType" SG_ 1684 CCUR_DiagReqData7 7;
BA_ "InvalidValue" SG_ 1684 CCUR_DiagReqData7 "null";
BA_ "GenSigSendType" SG_ 1694 PSM_D_DiagReqData0 7;
BA_ "InvalidValue" SG_ 1694 PSM_D_DiagReqData0 "null";
BA_ "GenSigSendType" SG_ 1694 PSM_D_DiagReqData1 7;
BA_ "InvalidValue" SG_ 1694 PSM_D_DiagReqData1 "null";
BA_ "GenSigSendType" SG_ 1694 PSM_D_DiagReqData2 7;
BA_ "InvalidValue" SG_ 1694 PSM_D_DiagReqData2 "null";
BA_ "GenSigSendType" SG_ 1694 PSM_D_DiagReqData3 7;
BA_ "InvalidValue" SG_ 1694 PSM_D_DiagReqData3 "null";
BA_ "GenSigSendType" SG_ 1694 PSM_D_DiagReqData4 7;
BA_ "InvalidValue" SG_ 1694 PSM_D_DiagReqData4 "null";
BA_ "GenSigSendType" SG_ 1694 PSM_D_DiagReqData5 7;
BA_ "InvalidValue" SG_ 1694 PSM_D_DiagReqData5 "null";
BA_ "GenSigSendType" SG_ 1694 PSM_D_DiagReqData6 7;
BA_ "InvalidValue" SG_ 1694 PSM_D_DiagReqData6 "null";
BA_ "GenSigSendType" SG_ 1694 PSM_D_DiagReqData7 7;
BA_ "InvalidValue" SG_ 1694 PSM_D_DiagReqData7 "null";
BA_ "GenSigSendType" SG_ 1713 USS_R_DiagReqData0 7;
BA_ "InvalidValue" SG_ 1713 USS_R_DiagReqData0 "null";
BA_ "GenSigSendType" SG_ 1713 USS_R_DiagReqData1 7;
BA_ "InvalidValue" SG_ 1713 USS_R_DiagReqData1 "null";
BA_ "GenSigSendType" SG_ 1713 USS_R_DiagReqData2 7;
BA_ "InvalidValue" SG_ 1713 USS_R_DiagReqData2 "null";
BA_ "GenSigSendType" SG_ 1713 USS_R_DiagReqData3 7;
BA_ "InvalidValue" SG_ 1713 USS_R_DiagReqData3 "null";
BA_ "GenSigSendType" SG_ 1713 USS_R_DiagReqData4 7;
BA_ "InvalidValue" SG_ 1713 USS_R_DiagReqData4 "null";
BA_ "GenSigSendType" SG_ 1713 USS_R_DiagReqData5 7;
BA_ "InvalidValue" SG_ 1713 USS_R_DiagReqData5 "null";
BA_ "GenSigSendType" SG_ 1713 USS_R_DiagReqData6 7;
BA_ "InvalidValue" SG_ 1713 USS_R_DiagReqData6 "null";
BA_ "GenSigSendType" SG_ 1713 USS_R_DiagReqData7 7;
BA_ "InvalidValue" SG_ 1713 USS_R_DiagReqData7 "null";
BA_ "GenSigSendType" SG_ 1714 USS_F_DiagReqData0 7;
BA_ "InvalidValue" SG_ 1714 USS_F_DiagReqData0 "null";
BA_ "GenSigSendType" SG_ 1714 USS_F_DiagReqData1 7;
BA_ "InvalidValue" SG_ 1714 USS_F_DiagReqData1 "null";
BA_ "GenSigSendType" SG_ 1714 USS_F_DiagReqData2 7;
BA_ "InvalidValue" SG_ 1714 USS_F_DiagReqData2 "null";
BA_ "GenSigSendType" SG_ 1714 USS_F_DiagReqData3 7;
BA_ "InvalidValue" SG_ 1714 USS_F_DiagReqData3 "null";
BA_ "GenSigSendType" SG_ 1714 USS_F_DiagReqData4 7;
BA_ "InvalidValue" SG_ 1714 USS_F_DiagReqData4 "null";
BA_ "GenSigSendType" SG_ 1714 USS_F_DiagReqData5 7;
BA_ "InvalidValue" SG_ 1714 USS_F_DiagReqData5 "null";
BA_ "GenSigSendType" SG_ 1714 USS_F_DiagReqData6 7;
BA_ "InvalidValue" SG_ 1714 USS_F_DiagReqData6 "null";
BA_ "GenSigSendType" SG_ 1714 USS_F_DiagReqData7 7;
BA_ "InvalidValue" SG_ 1714 USS_F_DiagReqData7 "null";
BA_ "GenSigSendType" SG_ 1721 SRR_RR_M_DiagReq_Data0 7;
BA_ "InvalidValue" SG_ 1721 SRR_RR_M_DiagReq_Data0 "null";
BA_ "GenSigSendType" SG_ 1721 SRR_RR_M_DiagReq_Data1 7;
BA_ "InvalidValue" SG_ 1721 SRR_RR_M_DiagReq_Data1 "null";
BA_ "GenSigSendType" SG_ 1721 SRR_RR_M_DiagReq_Data2 7;
BA_ "InvalidValue" SG_ 1721 SRR_RR_M_DiagReq_Data2 "null";
BA_ "GenSigSendType" SG_ 1721 SRR_RR_M_DiagReq_Data3 7;
BA_ "InvalidValue" SG_ 1721 SRR_RR_M_DiagReq_Data3 "null";
BA_ "GenSigSendType" SG_ 1721 SRR_RR_M_DiagReq_Data4 7;
BA_ "InvalidValue" SG_ 1721 SRR_RR_M_DiagReq_Data4 "null";
BA_ "GenSigSendType" SG_ 1721 SRR_RR_M_DiagReq_Data5 7;
BA_ "InvalidValue" SG_ 1721 SRR_RR_M_DiagReq_Data5 "null";
BA_ "GenSigSendType" SG_ 1721 SRR_RR_M_DiagReq_Data6 7;
BA_ "InvalidValue" SG_ 1721 SRR_RR_M_DiagReq_Data6 "null";
BA_ "GenSigSendType" SG_ 1721 SRR_RR_M_DiagReq_Data7 7;
BA_ "InvalidValue" SG_ 1721 SRR_RR_M_DiagReq_Data7 "null";
BA_ "GenSigSendType" SG_ 1723 TRM_DiagReqData0 7;
BA_ "InvalidValue" SG_ 1723 TRM_DiagReqData0 "null";
BA_ "GenSigSendType" SG_ 1723 TRM_DiagReqData1 7;
BA_ "InvalidValue" SG_ 1723 TRM_DiagReqData1 "null";
BA_ "GenSigSendType" SG_ 1723 TRM_DiagReqData2 7;
BA_ "InvalidValue" SG_ 1723 TRM_DiagReqData2 "null";
BA_ "GenSigSendType" SG_ 1723 TRM_DiagReqData3 7;
BA_ "InvalidValue" SG_ 1723 TRM_DiagReqData3 "null";
BA_ "GenSigSendType" SG_ 1723 TRM_DiagReqData4 7;
BA_ "InvalidValue" SG_ 1723 TRM_DiagReqData4 "null";
BA_ "GenSigSendType" SG_ 1723 TRM_DiagReqData5 7;
BA_ "InvalidValue" SG_ 1723 TRM_DiagReqData5 "null";
BA_ "GenSigSendType" SG_ 1723 TRM_DiagReqData6 7;
BA_ "InvalidValue" SG_ 1723 TRM_DiagReqData6 "null";
BA_ "GenSigSendType" SG_ 1723 TRM_DiagReqData7 7;
BA_ "InvalidValue" SG_ 1723 TRM_DiagReqData7 "null";
BA_ "GenSigSendType" SG_ 1729 APM_DiagReqData0 7;
BA_ "InvalidValue" SG_ 1729 APM_DiagReqData0 "null";
BA_ "GenSigSendType" SG_ 1729 APM_DiagReqData1 7;
BA_ "InvalidValue" SG_ 1729 APM_DiagReqData1 "null";
BA_ "GenSigSendType" SG_ 1729 APM_DiagReqData2 7;
BA_ "InvalidValue" SG_ 1729 APM_DiagReqData2 "null";
BA_ "GenSigSendType" SG_ 1729 APM_DiagReqData3 7;
BA_ "InvalidValue" SG_ 1729 APM_DiagReqData3 "null";
BA_ "GenSigSendType" SG_ 1729 APM_DiagReqData4 7;
BA_ "InvalidValue" SG_ 1729 APM_DiagReqData4 "null";
BA_ "GenSigSendType" SG_ 1729 APM_DiagReqData5 7;
BA_ "InvalidValue" SG_ 1729 APM_DiagReqData5 "null";
BA_ "GenSigSendType" SG_ 1729 APM_DiagReqData6 7;
BA_ "InvalidValue" SG_ 1729 APM_DiagReqData6 "null";
BA_ "GenSigSendType" SG_ 1729 APM_DiagReqData7 7;
BA_ "InvalidValue" SG_ 1729 APM_DiagReqData7 "null";
BA_ "GenSigSendType" SG_ 1730 SHVU_F_DiagReqData0 7;
BA_ "InvalidValue" SG_ 1730 SHVU_F_DiagReqData0 "null";
BA_ "GenSigSendType" SG_ 1730 SHVU_F_DiagReqData1 7;
BA_ "InvalidValue" SG_ 1730 SHVU_F_DiagReqData1 "null";
BA_ "GenSigSendType" SG_ 1730 SHVU_F_DiagReqData2 7;
BA_ "InvalidValue" SG_ 1730 SHVU_F_DiagReqData2 "null";
BA_ "GenSigSendType" SG_ 1730 SHVU_F_DiagReqData3 7;
BA_ "InvalidValue" SG_ 1730 SHVU_F_DiagReqData3 "null";
BA_ "GenSigSendType" SG_ 1730 SHVU_F_DiagReqData4 7;
BA_ "InvalidValue" SG_ 1730 SHVU_F_DiagReqData4 "null";
BA_ "GenSigSendType" SG_ 1730 SHVU_F_DiagReqData5 7;
BA_ "InvalidValue" SG_ 1730 SHVU_F_DiagReqData5 "null";
BA_ "GenSigSendType" SG_ 1730 SHVU_F_DiagReqData6 7;
BA_ "InvalidValue" SG_ 1730 SHVU_F_DiagReqData6 "null";
BA_ "GenSigSendType" SG_ 1730 SHVU_F_DiagReqData7 7;
BA_ "InvalidValue" SG_ 1730 SHVU_F_DiagReqData7 "null";
BA_ "GenSigSendType" SG_ 1731 SHVU_R_DiagReqData0 7;
BA_ "InvalidValue" SG_ 1731 SHVU_R_DiagReqData0 "null";
BA_ "GenSigSendType" SG_ 1731 SHVU_R_DiagReqData1 7;
BA_ "InvalidValue" SG_ 1731 SHVU_R_DiagReqData1 "null";
BA_ "GenSigSendType" SG_ 1731 SHVU_R_DiagReqData2 7;
BA_ "InvalidValue" SG_ 1731 SHVU_R_DiagReqData2 "null";
BA_ "GenSigSendType" SG_ 1731 SHVU_R_DiagReqData3 7;
BA_ "InvalidValue" SG_ 1731 SHVU_R_DiagReqData3 "null";
BA_ "GenSigSendType" SG_ 1731 SHVU_R_DiagReqData4 7;
BA_ "InvalidValue" SG_ 1731 SHVU_R_DiagReqData4 "null";
BA_ "GenSigSendType" SG_ 1731 SHVU_R_DiagReqData5 7;
BA_ "InvalidValue" SG_ 1731 SHVU_R_DiagReqData5 "null";
BA_ "GenSigSendType" SG_ 1731 SHVU_R_DiagReqData6 7;
BA_ "InvalidValue" SG_ 1731 SHVU_R_DiagReqData6 "null";
BA_ "GenSigSendType" SG_ 1731 SHVU_R_DiagReqData7 7;
BA_ "InvalidValue" SG_ 1731 SHVU_R_DiagReqData7 "null";
BA_ "GenSigSendType" SG_ 1732 OCS_P_DiagReqData0 7;
BA_ "InvalidValue" SG_ 1732 OCS_P_DiagReqData0 "null";
BA_ "GenSigSendType" SG_ 1732 OCS_P_DiagReqData1 7;
BA_ "InvalidValue" SG_ 1732 OCS_P_DiagReqData1 "null";
BA_ "GenSigSendType" SG_ 1732 OCS_P_DiagReqData2 7;
BA_ "InvalidValue" SG_ 1732 OCS_P_DiagReqData2 "null";
BA_ "GenSigSendType" SG_ 1732 OCS_P_DiagReqData3 7;
BA_ "InvalidValue" SG_ 1732 OCS_P_DiagReqData3 "null";
BA_ "GenSigSendType" SG_ 1732 OCS_P_DiagReqData4 7;
BA_ "InvalidValue" SG_ 1732 OCS_P_DiagReqData4 "null";
BA_ "GenSigSendType" SG_ 1732 OCS_P_DiagReqData5 7;
BA_ "InvalidValue" SG_ 1732 OCS_P_DiagReqData5 "null";
BA_ "GenSigSendType" SG_ 1732 OCS_P_DiagReqData6 7;
BA_ "InvalidValue" SG_ 1732 OCS_P_DiagReqData6 "null";
BA_ "GenSigSendType" SG_ 1732 OCS_P_DiagReqData7 7;
BA_ "InvalidValue" SG_ 1732 OCS_P_DiagReqData7 "null";
BA_ "GenSigSendType" SG_ 1737 LDM_L_DiagReqData0 7;
BA_ "InvalidValue" SG_ 1737 LDM_L_DiagReqData0 "null";
BA_ "GenSigSendType" SG_ 1737 LDM_L_DiagReqData1 7;
BA_ "InvalidValue" SG_ 1737 LDM_L_DiagReqData1 "null";
BA_ "GenSigSendType" SG_ 1737 LDM_L_DiagReqData2 7;
BA_ "InvalidValue" SG_ 1737 LDM_L_DiagReqData2 "null";
BA_ "GenSigSendType" SG_ 1737 LDM_L_DiagReqData3 7;
BA_ "InvalidValue" SG_ 1737 LDM_L_DiagReqData3 "null";
BA_ "GenSigSendType" SG_ 1737 LDM_L_DiagReqData4 7;
BA_ "InvalidValue" SG_ 1737 LDM_L_DiagReqData4 "null";
BA_ "GenSigSendType" SG_ 1737 LDM_L_DiagReqData5 7;
BA_ "InvalidValue" SG_ 1737 LDM_L_DiagReqData5 "null";
BA_ "GenSigSendType" SG_ 1737 LDM_L_DiagReqData6 7;
BA_ "InvalidValue" SG_ 1737 LDM_L_DiagReqData6 "null";
BA_ "GenSigSendType" SG_ 1737 LDM_L_DiagReqData7 7;
BA_ "InvalidValue" SG_ 1737 LDM_L_DiagReqData7 "null";
BA_ "GenSigSendType" SG_ 1738 LDM_R_DiagReqData0 7;
BA_ "InvalidValue" SG_ 1738 LDM_R_DiagReqData0 "null";
BA_ "GenSigSendType" SG_ 1738 LDM_R_DiagReqData1 7;
BA_ "InvalidValue" SG_ 1738 LDM_R_DiagReqData1 "null";
BA_ "GenSigSendType" SG_ 1738 LDM_R_DiagReqData2 7;
BA_ "InvalidValue" SG_ 1738 LDM_R_DiagReqData2 "null";
BA_ "GenSigSendType" SG_ 1738 LDM_R_DiagReqData3 7;
BA_ "InvalidValue" SG_ 1738 LDM_R_DiagReqData3 "null";
BA_ "GenSigSendType" SG_ 1738 LDM_R_DiagReqData4 7;
BA_ "InvalidValue" SG_ 1738 LDM_R_DiagReqData4 "null";
BA_ "GenSigSendType" SG_ 1738 LDM_R_DiagReqData5 7;
BA_ "InvalidValue" SG_ 1738 LDM_R_DiagReqData5 "null";
BA_ "GenSigSendType" SG_ 1738 LDM_R_DiagReqData6 7;
BA_ "InvalidValue" SG_ 1738 LDM_R_DiagReqData6 "null";
BA_ "GenSigSendType" SG_ 1738 LDM_R_DiagReqData7 7;
BA_ "InvalidValue" SG_ 1738 LDM_R_DiagReqData7 "null";
BA_ "GenSigSendType" SG_ 1752 BAS_DiagReqData0 7;
BA_ "InvalidValue" SG_ 1752 BAS_DiagReqData0 "null";
BA_ "GenSigSendType" SG_ 1752 BAS_DiagReqData1 7;
BA_ "InvalidValue" SG_ 1752 BAS_DiagReqData1 "null";
BA_ "GenSigSendType" SG_ 1752 BAS_DiagReqData2 7;
BA_ "InvalidValue" SG_ 1752 BAS_DiagReqData2 "null";
BA_ "GenSigSendType" SG_ 1752 BAS_DiagReqData3 7;
BA_ "InvalidValue" SG_ 1752 BAS_DiagReqData3 "null";
BA_ "GenSigSendType" SG_ 1752 BAS_DiagReqData4 7;
BA_ "InvalidValue" SG_ 1752 BAS_DiagReqData4 "null";
BA_ "GenSigSendType" SG_ 1752 BAS_DiagReqData5 7;
BA_ "InvalidValue" SG_ 1752 BAS_DiagReqData5 "null";
BA_ "GenSigSendType" SG_ 1752 BAS_DiagReqData6 7;
BA_ "InvalidValue" SG_ 1752 BAS_DiagReqData6 "null";
BA_ "GenSigSendType" SG_ 1752 BAS_DiagReqData7 7;
BA_ "InvalidValue" SG_ 1752 BAS_DiagReqData7 "null";
BA_ "GenSigSendType" SG_ 1764 DCM_APM_DiagReqData0 7;
BA_ "InvalidValue" SG_ 1764 DCM_APM_DiagReqData0 "null";
BA_ "GenSigSendType" SG_ 1764 DCM_APM_DiagReqData1 7;
BA_ "InvalidValue" SG_ 1764 DCM_APM_DiagReqData1 "null";
BA_ "GenSigSendType" SG_ 1764 DCM_APM_DiagReqData2 7;
BA_ "InvalidValue" SG_ 1764 DCM_APM_DiagReqData2 "null";
BA_ "GenSigSendType" SG_ 1764 DCM_APM_DiagReqData3 7;
BA_ "InvalidValue" SG_ 1764 DCM_APM_DiagReqData3 "null";
BA_ "GenSigSendType" SG_ 1764 DCM_APM_DiagReqData4 7;
BA_ "InvalidValue" SG_ 1764 DCM_APM_DiagReqData4 "null";
BA_ "GenSigSendType" SG_ 1764 DCM_APM_DiagReqData5 7;
BA_ "InvalidValue" SG_ 1764 DCM_APM_DiagReqData5 "null";
BA_ "GenSigSendType" SG_ 1764 DCM_APM_DiagReqData6 7;
BA_ "InvalidValue" SG_ 1764 DCM_APM_DiagReqData6 "null";
BA_ "GenSigSendType" SG_ 1764 DCM_APM_DiagReqData7 7;
BA_ "InvalidValue" SG_ 1764 DCM_APM_DiagReqData7 "null";
BA_ "GenSigSendType" SG_ 1777 ASU_DiagReqData0 7;
BA_ "GenSigSendType" SG_ 1777 ASU_DiagReqData1 7;
BA_ "GenSigSendType" SG_ 1777 ASU_DiagReqData2 7;
BA_ "GenSigSendType" SG_ 1777 ASU_DiagReqData3 7;
BA_ "GenSigSendType" SG_ 1777 ASU_DiagReqData4 7;
BA_ "GenSigSendType" SG_ 1777 ASU_DiagReqData5 7;
BA_ "GenSigSendType" SG_ 1777 ASU_DiagReqData6 7;
BA_ "GenSigSendType" SG_ 1777 ASU_DiagReqData7 7;
BA_ "GenSigSendType" SG_ 1787 BCM_BPM_DiagReqData0 7;
BA_ "InvalidValue" SG_ 1787 BCM_BPM_DiagReqData0 "null";
BA_ "GenSigSendType" SG_ 1787 BCM_BPM_DiagReqData1 7;
BA_ "InvalidValue" SG_ 1787 BCM_BPM_DiagReqData1 "null";
BA_ "GenSigSendType" SG_ 1787 BCM_BPM_DiagReqData2 7;
BA_ "InvalidValue" SG_ 1787 BCM_BPM_DiagReqData2 "null";
BA_ "GenSigSendType" SG_ 1787 BCM_BPM_DiagReqData3 7;
BA_ "InvalidValue" SG_ 1787 BCM_BPM_DiagReqData3 "null";
BA_ "GenSigSendType" SG_ 1787 BCM_BPM_DiagReqData4 7;
BA_ "InvalidValue" SG_ 1787 BCM_BPM_DiagReqData4 "null";
BA_ "GenSigSendType" SG_ 1787 BCM_BPM_DiagReqData5 7;
BA_ "InvalidValue" SG_ 1787 BCM_BPM_DiagReqData5 "null";
BA_ "GenSigSendType" SG_ 1787 BCM_BPM_DiagReqData6 7;
BA_ "InvalidValue" SG_ 1787 BCM_BPM_DiagReqData6 "null";
BA_ "GenSigSendType" SG_ 1787 BCM_BPM_DiagReqData7 7;
BA_ "InvalidValue" SG_ 1787 BCM_BPM_DiagReqData7 "null";
BA_ "GenSigSendType" SG_ 1791 OBD_Func_DiagReqData0 7;
BA_ "InvalidValue" SG_ 1791 OBD_Func_DiagReqData0 "null";
BA_ "GenSigSendType" SG_ 1791 OBD_Func_DiagReqData1 7;
BA_ "InvalidValue" SG_ 1791 OBD_Func_DiagReqData1 "null";
BA_ "GenSigSendType" SG_ 1791 OBD_Func_DiagReqData2 7;
BA_ "InvalidValue" SG_ 1791 OBD_Func_DiagReqData2 "null";
BA_ "GenSigSendType" SG_ 1791 OBD_Func_DiagReqData3 7;
BA_ "InvalidValue" SG_ 1791 OBD_Func_DiagReqData3 "null";
BA_ "GenSigSendType" SG_ 1791 OBD_Func_DiagReqData4 7;
BA_ "InvalidValue" SG_ 1791 OBD_Func_DiagReqData4 "null";
BA_ "GenSigSendType" SG_ 1791 OBD_Func_DiagReqData5 7;
BA_ "InvalidValue" SG_ 1791 OBD_Func_DiagReqData5 "null";
BA_ "GenSigSendType" SG_ 1791 OBD_Func_DiagReqData6 7;
BA_ "InvalidValue" SG_ 1791 OBD_Func_DiagReqData6 "null";
BA_ "GenSigSendType" SG_ 1791 OBD_Func_DiagReqData7 7;
BA_ "InvalidValue" SG_ 1791 OBD_Func_DiagReqData7 "null";
BA_ "GenSigSendType" SG_ 1793 SEED_CAN_Req1 7;
BA_ "InvalidValue" SG_ 1793 SEED_CAN_Req1 "null";
BA_ "GenSigSendType" SG_ 1795 SEED_CAN_Req2 7;
BA_ "InvalidValue" SG_ 1795 SEED_CAN_Req2 "null";
BA_ "GenSigSendType" SG_ 1803 SEED_CAN_Req6 7;
BA_ "InvalidValue" SG_ 1803 SEED_CAN_Req6 "null";
BA_ "GenSigSendType" SG_ 1805 SEED_CAN_Req7 7;
BA_ "InvalidValue" SG_ 1805 SEED_CAN_Req7 "null";
BA_ "GenSigSendType" SG_ 1809 BCM_Data0 4;
BA_ "GenSigTimeoutTime_ALL" SG_ 1809 BCM_Data0 500;
BA_ "InvalidValue" SG_ 1809 BCM_Data0 "null";
BA_ "GenSigSendType" SG_ 1809 BCM_Data1 4;
BA_ "GenSigTimeoutTime_ALL" SG_ 1809 BCM_Data1 500;
BA_ "InvalidValue" SG_ 1809 BCM_Data1 "null";
BA_ "GenSigSendType" SG_ 1809 BCM_Data2 4;
BA_ "GenSigTimeoutTime_ALL" SG_ 1809 BCM_Data2 500;
BA_ "InvalidValue" SG_ 1809 BCM_Data2 "null";
BA_ "GenSigSendType" SG_ 1809 BCM_Data3 4;
BA_ "GenSigTimeoutTime_ALL" SG_ 1809 BCM_Data3 500;
BA_ "InvalidValue" SG_ 1809 BCM_Data3 "null";
BA_ "GenSigSendType" SG_ 1809 BCM_Data4 4;
BA_ "GenSigTimeoutTime_ALL" SG_ 1809 BCM_Data4 500;
BA_ "InvalidValue" SG_ 1809 BCM_Data4 "null";
BA_ "GenSigSendType" SG_ 1809 BCM_Data5 4;
BA_ "GenSigTimeoutTime_ALL" SG_ 1809 BCM_Data5 500;
BA_ "InvalidValue" SG_ 1809 BCM_Data5 "null";
BA_ "GenSigSendType" SG_ 1809 BCM_Data6 4;
BA_ "GenSigTimeoutTime_ALL" SG_ 1809 BCM_Data6 500;
BA_ "InvalidValue" SG_ 1809 BCM_Data6 "null";
BA_ "GenSigSendType" SG_ 1809 BCM_Data7 4;
BA_ "GenSigTimeoutTime_ALL" SG_ 1809 BCM_Data7 500;
BA_ "InvalidValue" SG_ 1809 BCM_Data7 "null";
BA_ "GenSigSendType" SG_ 1810 BCM_BPM_Data0 4;
BA_ "GenSigTimeoutTime_ALL" SG_ 1810 BCM_BPM_Data0 500;
BA_ "InvalidValue" SG_ 1810 BCM_BPM_Data0 "null";
BA_ "GenSigSendType" SG_ 1810 BCM_BPM_Data1 4;
BA_ "GenSigTimeoutTime_ALL" SG_ 1810 BCM_BPM_Data1 500;
BA_ "InvalidValue" SG_ 1810 BCM_BPM_Data1 "null";
BA_ "GenSigSendType" SG_ 1810 BCM_BPM_Data2 4;
BA_ "GenSigTimeoutTime_ALL" SG_ 1810 BCM_BPM_Data2 500;
BA_ "InvalidValue" SG_ 1810 BCM_BPM_Data2 "null";
BA_ "GenSigSendType" SG_ 1810 BCM_BPM_Data3 4;
BA_ "GenSigTimeoutTime_ALL" SG_ 1810 BCM_BPM_Data3 500;
BA_ "InvalidValue" SG_ 1810 BCM_BPM_Data3 "null";
BA_ "GenSigSendType" SG_ 1810 BCM_BPM_Data4 4;
BA_ "GenSigTimeoutTime_ALL" SG_ 1810 BCM_BPM_Data4 500;
BA_ "InvalidValue" SG_ 1810 BCM_BPM_Data4 "null";
BA_ "GenSigSendType" SG_ 1810 BCM_BPM_Data5 4;
BA_ "GenSigTimeoutTime_ALL" SG_ 1810 BCM_BPM_Data5 500;
BA_ "InvalidValue" SG_ 1810 BCM_BPM_Data5 "null";
BA_ "GenSigSendType" SG_ 1810 BCM_BPM_Data6 4;
BA_ "GenSigTimeoutTime_ALL" SG_ 1810 BCM_BPM_Data6 500;
BA_ "InvalidValue" SG_ 1810 BCM_BPM_Data6 "null";
BA_ "GenSigSendType" SG_ 1810 BCM_BPM_Data7 4;
BA_ "GenSigTimeoutTime_ALL" SG_ 1810 BCM_BPM_Data7 500;
BA_ "InvalidValue" SG_ 1810 BCM_BPM_Data7 "null";
BA_ "GenSigStartValue" SG_ 1814 CCU_DuctSensor1 60;
BA_ "GenSigTimeoutTime_ALL" SG_ 1814 CCU_DuctSensor1 1000;
BA_ "InvalidValue" SG_ 1814 CCU_DuctSensor1 "0xFF";
BA_ "GenSigStartValue" SG_ 1814 CCU_DuctSensor2 60;
BA_ "GenSigTimeoutTime_ALL" SG_ 1814 CCU_DuctSensor2 1000;
BA_ "InvalidValue" SG_ 1814 CCU_DuctSensor2 "0xFF";
BA_ "GenSigStartValue" SG_ 1814 CCU_DuctSensor3 60;
BA_ "GenSigTimeoutTime_ALL" SG_ 1814 CCU_DuctSensor3 1000;
BA_ "InvalidValue" SG_ 1814 CCU_DuctSensor3 "0xFF";
BA_ "GenSigStartValue" SG_ 1814 CCU_DuctSensor4 60;
BA_ "GenSigTimeoutTime_ALL" SG_ 1814 CCU_DuctSensor4 1000;
BA_ "InvalidValue" SG_ 1814 CCU_DuctSensor4 "0xFF";
BA_ "GenSigTimeoutTime_ALL" SG_ 1814 CCU_AQS_PWM_IN 1000;
BA_ "InvalidValue" SG_ 1814 CCU_AQS_PWM_IN "0xFF";
BA_ "GenSigTimeoutTime_ALL" SG_ 1814 CCU_AQSCtrlFrequency 1000;
BA_ "InvalidValue" SG_ 1814 CCU_AQSCtrlFrequency "0x3FF";
BA_ "GenSigTimeoutTime_ALL" SG_ 1814 CCU_BattVoltSts 1000;
BA_ "InvalidValue" SG_ 1814 CCU_BattVoltSts "0xF";
BA_ "GenSigTimeoutTime_ALL" SG_ 1814 CCU_BattVoltVal 1000;
BA_ "InvalidValue" SG_ 1814 CCU_BattVoltVal "0xFF";
BA_ "GenSigSendType" SG_ 1843 SEED_CAN_Req18 7;
BA_ "InvalidValue" SG_ 1843 SEED_CAN_Req18 "null";
BA_ "GenSigSendType" SG_ 1847 SEED_CAN_Req21 7;
BA_ "InvalidValue" SG_ 1847 SEED_CAN_Req21 "null";
BA_ "GenSigSendType" SG_ 1850 SEED_CAN_Req25 7;
BA_ "GenSigSendType" SG_ 1853 SEED_CAN_Req29 7;
BA_ "GenSigTimeoutTime_ALL" SG_ 1857 CCU_ERL_FL 1000;
BA_ "InvalidValue" SG_ 1857 CCU_ERL_FL "null";
BA_ "GenSigTimeoutTime_ALL" SG_ 1857 CCU_ERL_FR 1000;
BA_ "InvalidValue" SG_ 1857 CCU_ERL_FR "null";
BA_ "GenSigStartValue" SG_ 1857 CCU_EvapTempSet 50;
BA_ "GenSigTimeoutTime_ALL" SG_ 1857 CCU_EvapTempSet 1000;
BA_ "InvalidValue" SG_ 1857 CCU_EvapTempSet "null";
BA_ "GenSigTimeoutTime_ALL" SG_ 1857 CCU_BlowerFltPWM 1000;
BA_ "InvalidValue" SG_ 1857 CCU_BlowerFltPWM "null";
BA_ "GenSigTimeoutTime_ALL" SG_ 1857 CCU_AirDistribFlapPos 1000;
BA_ "InvalidValue" SG_ 1857 CCU_AirDistribFlapPos "null";
BA_ "GenSigTimeoutTime_ALL" SG_ 1857 CCU_RecircFlapPos 1000;
BA_ "InvalidValue" SG_ 1857 CCU_RecircFlapPos "null";
BA_ "GenSigTimeoutTime_ALL" SG_ 1857 CCU_AirDistribFeedback 1000;
BA_ "InvalidValue" SG_ 1857 CCU_AirDistribFeedback "null";
BA_ "GenSigTimeoutTime_ALL" SG_ 1857 CCU_RecircFlapFeedback 1000;
BA_ "InvalidValue" SG_ 1857 CCU_RecircFlapFeedback "null";
BA_ "GenSigTimeoutTime_ALL" SG_ 2046 TST_TxMsgConfirm_CcuHeatCoolReq 1000;
BA_ "GenSigTimeoutTime_ALL" SG_ 2046 TST_RxMsgConfirm_BCM_CLAMP_STAT 1000;
BA_ "GenSigTimeoutTime_ALL" SG_ 2046 CCU_TST_TxMsgConfirm_CcuWarnMsg 1000;
BA_ "GenSigTimeoutTime_ALL" SG_ 2046 CCU_TST_TxMsgConfirm_CcuNm 1000;
BA_ "GenSigTimeoutTime_ALL" SG_ 2046 CCU_TST_StateMngr_States 1000;
BA_ "GenSigTimeoutTime_ALL" SG_ 2046 CCU_TST_Reserve_6 1000;
BA_ "GenSigTimeoutTime_ALL" SG_ 2046 CCU_TST_Reserve_5 1000;
BA_ "GenSigTimeoutTime_ALL" SG_ 2046 CCU_TST_Reserve_4 1000;
BA_ "GenSigTimeoutTime_ALL" SG_ 2046 CCU_TST_Reserve_3 1000;
BA_ "GenSigTimeoutTime_ALL" SG_ 2046 CCU_TST_Reserve_2 1000;
BA_ "GenSigTimeoutTime_ALL" SG_ 2046 CCU_TST_Reserve_1 1000;
BA_ "GenSigTimeoutTime_ALL" SG_ 2046 CCU_TST_Reserve_0 1000;
BA_ "GenSigTimeoutTime_ALL" SG_ 2046 CCU_TST_NetworkMngr_States 1000;
BA_ "GenSigTimeoutTime_ALL" SG_ 2046 CCU_TST_BCM_CRC 1000;
BA_ "GenSigTimeoutTime_ALL" SG_ 1858 CCU_TempFlapPos_FL 1000;
BA_ "InvalidValue" SG_ 1858 CCU_TempFlapPos_FL "null";
BA_ "GenSigTimeoutTime_ALL" SG_ 1858 CCU_TempFlapPos_FR 1000;
BA_ "InvalidValue" SG_ 1858 CCU_TempFlapPos_FR "null";
BA_ "GenSigStartValue" SG_ 1858 CCU_DuctTargetTemp_FL 80;
BA_ "GenSigTimeoutTime_ALL" SG_ 1858 CCU_DuctTargetTemp_FL 1000;
BA_ "InvalidValue" SG_ 1858 CCU_DuctTargetTemp_FL "null";
BA_ "GenSigStartValue" SG_ 1858 CCU_DuctTargetTemp_FR 80;
BA_ "GenSigTimeoutTime_ALL" SG_ 1858 CCU_DuctTargetTemp_FR 1000;
BA_ "InvalidValue" SG_ 1858 CCU_DuctTargetTemp_FR "null";
BA_ "GenSigTimeoutTime_ALL" SG_ 1858 CCU_TempFLFeedback 1000;
BA_ "InvalidValue" SG_ 1858 CCU_TempFLFeedback "null";
BA_ "GenSigTimeoutTime_ALL" SG_ 1858 CCU_TempFRFeedback 1000;
BA_ "InvalidValue" SG_ 1858 CCU_TempFRFeedback "null";
BA_ "GenSigTimeoutTime_ALL" SG_ 1858 CCU_PTCSetTemp 1000;
BA_ "InvalidValue" SG_ 1858 CCU_PTCSetTemp "null";
BA_ "GenSigSendType" SG_ 1938 CCU_Resp_CCP 7;
BA_ "InvalidValue" SG_ 1938 CCU_Resp_CCP "null";
BA_ "GenSigTimeoutTime_ALL" SG_ 1939 LDML_FltReactn 500;
BA_ "InvalidValue" SG_ 1939 LDML_FltReactn "null";
BA_ "GenSigStartValue" SG_ 1939 LDML_RiAdjstAgOutp 1000;
BA_ "GenSigTimeoutTime_ALL" SG_ 1939 LDML_RiAdjstAgOutp 500;
BA_ "InvalidValue" SG_ 1939 LDML_RiAdjstAgOutp "null";
BA_ "GenSigTimeoutTime_ALL" SG_ 1940 LDMR_FltReactn 500;
BA_ "InvalidValue" SG_ 1940 LDMR_FltReactn "null";
BA_ "GenSigStartValue" SG_ 1940 LDMR_ModuleCurAg 1000;
BA_ "GenSigTimeoutTime_ALL" SG_ 1940 LDMR_ModuleCurAg 500;
BA_ "InvalidValue" SG_ 1940 LDMR_ModuleCurAg "null";
BA_ "GenSigSendType" SG_ 1977 CCU_Resp_EOL 7;
BA_ "InvalidValue" SG_ 1977 CCU_Resp_EOL "null";
BA_ "GenSigSendType" SG_ 1980 CCUR_Resp_EOL_ 7;
BA_ "InvalidValue" SG_ 1980 CCUR_Resp_EOL_ "null";
BA_ "GenSigSendType" SG_ 2015 Diag_Request_ECU_Data0 7;
BA_ "InvalidValue" SG_ 2015 Diag_Request_ECU_Data0 "null";
BA_ "GenSigSendType" SG_ 2015 Diag_Request_ECU_Data1 7;
BA_ "InvalidValue" SG_ 2015 Diag_Request_ECU_Data1 "null";
BA_ "GenSigSendType" SG_ 2015 Diag_Request_ECU_Data2 7;
BA_ "InvalidValue" SG_ 2015 Diag_Request_ECU_Data2 "null";
BA_ "GenSigSendType" SG_ 2015 Diag_Request_ECU_Data3 7;
BA_ "InvalidValue" SG_ 2015 Diag_Request_ECU_Data3 "null";
BA_ "GenSigSendType" SG_ 2015 Diag_Request_ECU_Data4 7;
BA_ "InvalidValue" SG_ 2015 Diag_Request_ECU_Data4 "null";
BA_ "GenSigSendType" SG_ 2015 Diag_Request_ECU_Data5 7;
BA_ "InvalidValue" SG_ 2015 Diag_Request_ECU_Data5 "null";
BA_ "GenSigSendType" SG_ 2015 Diag_Request_ECU_Data6 7;
BA_ "InvalidValue" SG_ 2015 Diag_Request_ECU_Data6 "null";
BA_ "GenSigSendType" SG_ 2015 Diag_Request_ECU_Data7 7;
BA_ "InvalidValue" SG_ 2015 Diag_Request_ECU_Data7 "null";
BA_ "GenSigSendType" SG_ 2033 Request_Airbag_Deployment 7;
BA_ "InvalidValue" SG_ 2033 Request_Airbag_Deployment "null";
BA_ "GenSigSendType" SG_ 2041 Response_Airbag_Deployment 7;
BA_ "InvalidValue" SG_ 2041 Response_Airbag_Deployment "null";
VAL_ 1161 CCU_Malfunction 0 "No Error" 1 "Error" ;
VAL_ 1161 CCU_Warning_Flag_2 0 "No Error" 1 "Error" ;
VAL_ 1161 CCU_Warning_Flag_3 0 "No Error" 1 "Error" ;
VAL_ 1161 CCU_Warning_Flag_4 0 "No Error" 1 "Error" ;
VAL_ 1161 CCU_Warning_Flag_5 0 "No Error" 1 "Error" ;
VAL_ 1161 CCU_Warning_Flag_6 0 "No Error" 1 "Error" ;
VAL_ 1161 CCU_Warning_Flag_7 0 "No Error" 1 "Error" ;
VAL_ 1161 CCU_Warning_Flag_8 0 "No Error" 1 "Error" ;
VAL_ 1161 CCU_Warning_Flag_9 0 "No Error" 1 "Error" ;
VAL_ 1161 CCU_Warning_Flag_10 0 "No Error" 1 "Error" ;
VAL_ 1161 CCU_Warning_Flag_11 0 "No Error" 1 "Error" ;
VAL_ 1161 CCU_Warning_Flag_12 0 "No Error" 1 "Error" ;
VAL_ 1166 ETG_Malfunction 0 "No Error" 1 "Error" ;
VAL_ 1166 ETG_Warning_Flag_2 0 "No Error" 1 "Error" ;
VAL_ 1166 ETG_Warning_Flag_3 0 "No Error" 1 "Error" ;
VAL_ 1166 ETG_Warning_Flag_4 0 "No Error" 1 "Error" ;
VAL_ 1166 ETG_Warning_Flag_5 0 "No Error" 1 "Error" ;
VAL_ 1166 ETG_Warning_Flag_6 0 "No Error" 1 "Error" ;
VAL_ 1166 ETG_Warning_Flag_7 0 "No Error" 1 "Error" ;
VAL_ 1166 ETG_Warning_Flag_8 0 "No Error" 1 "Error" ;
VAL_ 1166 ETG_Warning_Flag_9 0 "No Error" 1 "Error" ;
VAL_ 1166 ETG_Warning_Flag_10 0 "No Error" 1 "Error" ;
VAL_ 1166 ETG_Warning_Flag_11 0 "No Error" 1 "Error" ;
VAL_ 1166 ETG_Warning_Flag_12 0 "No Error" 1 "Error" ;
VAL_ 1171 BMS_PackTempSts 0 "No warning" 1 "Over Temperature Warning" 2 "Under Temperature Warning" 3 "Extreme Low Temp Error";
VAL_ 1171 BMS_ThermalRunaway 0 "No Warning" 1 "Warning" ;
VAL_ 1171 BMS_BatteryReplacement 0 "No Warning" 1 "Warning" ;
VAL_ 1171 BMS_Warning_PowerDegrade 0 "Normal" 1 "Pack Power Degrade" ;
VAL_ 1171 BMS_Warning_DeltaSoC 0 "Normal" 1 "Delta SOC high" ;
VAL_ 1171 BMS_Warning_HVILSts 0 "Normal" 1 "HVIL error detected" ;
VAL_ 1171 BMS_Warning_Isolation 0 "Normal" 1 "Isolation reached level 3" ;
VAL_ 1171 BMS_Warning_CoolantLeakage 0 "Normal" 1 "Coolant leakage detected" ;
VAL_ 1171 BMS_MalfunctionSts 0 "No Warning" 1 "Warning" ;
VAL_ 1171 BMS_LowBattery 0 "No warning" 1 "Low level" 2 "Extremely low level" ;
VAL_ 1171 BMS_Warning_DeltaTemperature 0 "Normal" 1 "Level 1 warning" 2 "Level 2 extreme" ;
VAL_ 1171 BMS_Warning_BDUTemperatureSts 0 "Normal" 1 "BDU temp warning" 2 "BDU hot" 3 "BDU extreme hot" ;
VAL_ 1209 BSD_Warning_Flag_7 0 "No Error" 1 "Error";
VAL_ 1209 BSD_Warning_Flag_8 0 "No Error" 1 "Error";
VAL_ 1209 BSD_Warning_Flag_9 0 "No Error" 1 "Error";
VAL_ 1209 BSD_Warning_Flag_10 0 "No Error" 1 "Error";
VAL_ 1209 BSD_Warning_Flag_14 0 "No Error" 1 "Error";
VAL_ 1209 BSD_Warning_Flag_21 0 "No Error" 1 "Error";
VAL_ 1209 BSD_Warning_Flag_22 0 "No Error" 1 "Error";
VAL_ 1209 BSD_Warning_Flag_23 0 "No Error" 1 "Error";
VAL_ 1209 BSD_Warning_Flag_24 0 "No Error" 1 "Error";
VAL_ 1211 TRM_LightMalfnc 0 "No Error" 1 "Error" ;
VAL_ 1211 TRM_TurnLeftMafnc 0 "No Error" 1 "Error" ;
VAL_ 1211 TRM_TurnRightMafnc 0 "No Error" 1 "Error" ;
VAL_ 1211 TRM_TrailerMalfnc 0 "No Error" 1 "Error" ;
VAL_ 1211 TRM_Warning_Flag_5 0 "No Error" 1 "Error" ;
VAL_ 1211 TRM_Warning_Flag_6 0 "No Error" 1 "Error" ;
VAL_ 1211 TRM_Warning_Flag_7 0 "No Error" 1 "Error" ;
VAL_ 1211 TRM_Warning_Flag_8 0 "No Error" 1 "Error" ;
VAL_ 1211 TRM_Warning_Flag_9 0 "No Error" 1 "Error" ;
VAL_ 1211 TRM_Warning_Flag_10 0 "No Error" 1 "Error" ;
VAL_ 1211 TRM_Warning_Flag_11 0 "No Error" 1 "Error" ;
VAL_ 1211 TRM_Warning_Flag_12 0 "No Error" 1 "Error" ;
VAL_ 1216 BCM_STAT_DoorHandleRR 0 "Released" 1 "Pulled" ;
VAL_ 1216 BCM_STAT_DoorHandleRL 0 "Released" 1 "Pulled" ;
VAL_ 1216 BCM_STAT_DoorHandleFR 0 "Released" 1 "Pulled" ;
VAL_ 1216 BCM_STAT_DoorHandleFL 0 "Released" 1 "Pulled" ;
VAL_ 1217 APM_Malfunction 0 "No Error" 1 "Error" ;
VAL_ 1217 ChildWindowLockStS 0 "No Error" 1 "Error" ;
VAL_ 1217 APM_Warning_Flag_3 0 "No Error" 1 "Error" ;
VAL_ 1217 APM_Warning_Flag_4 0 "No Error" 1 "Error" ;
VAL_ 1217 APM_Warning_Flag_5 0 "No Error" 1 "Error" ;
VAL_ 1217 APM_Warning_Flag_6 0 "No Error" 1 "Error" ;
VAL_ 1217 APM_Warning_Flag_7 0 "No Error" 1 "Error" ;
VAL_ 1217 APM_Warning_Flag_8 0 "No Error" 1 "Error" ;
VAL_ 1217 APM_Warning_Flag_9 0 "No Error" 1 "Error" ;
VAL_ 1217 APM_Warning_Flag_10 0 "No Error" 1 "Error" ;
VAL_ 1217 APM_Warning_Flag_11 0 "No Error" 1 "Error" ;
VAL_ 1217 APM_Warning_Flag_12 0 "No Error" 1 "Error" ;
VAL_ 2046 TST_TxMsgConfirm_CcuHeatCoolReq 1 "Message Transmitted" 0 "Message Not Transmitted" ;
VAL_ 2046 TST_RxMsgConfirm_BCM_CLAMP_STAT 1 "Message Received" 0 "Message Not Received" ;
VAL_ 2046 CCU_TST_TxMsgConfirm_CcuWarnMsg 1 "Message Transmitted" 0 "Message Not Transmitted" ;
VAL_ 2046 CCU_TST_TxMsgConfirm_CcuNm 1 "Message Transmitted" 0 "Message Not Transmitted" ;
VAL_ 2046 CCU_TST_StateMngr_States 7 "SM_ACC_STATE" 6 "SM_BET_INIT" 5 "SM_SHUTDOWN" 4 "SM_SLEEPING" 3 "SM_STANDBY" 2 "SM_NORMAL_RUN" 1 "SM_SAFE_STATE" 0 "SM_INIT_CYCLIC" ;
VAL_ 2046 CCU_TST_NetworkMngr_States 7 "Not used" 6 "0x9 NM_STATE_BUS_OFF" 5 "NM_STATE_REPEAT_MESSAGE" 4 "NM_STATE_NORMAL_OPERATION" 3 "NM_STATE_READY_SLEEP" 2 "NM_STATE_PREPARE_BUS_SLEEP" 1 "NM_STATE_BUS_SLEEP" 0 "NM_STATE_UNINIT" ;
VAL_ 2046 CCU_TST_BCM_CRC 1 "CRC correct" 0 "CRC not correct" ;
